VERSION "dbc-export 1 2025.20.8"

NS_ :

BS_:

BU_: ADSP APB APP APS APSB BB BMS CC CMP CMPD CP DAS DI DIF DIR DPB EPAS3P EPAS3S EPASTP EPASTS EPBL EPBR ESP EVSE FC GTW HCML HCMR HVP IBST ICR IDB LS OCS1P ODIN PARK PCS PLG PM PMF PMR PNCD PTC RADC RCM RCM2 RCM3 RCU SCCM SCM SCS SDCR TAS TCU TPMS TRCM UDS UI UIS UMC USM VC VCFRONT VCLEFT VCRIGHT VCSEC VEH

BO_ 1481 APS_alertLog: 8 APS
 SG_ APS_alertID M : 0|14@1+ (1,0) [0|16383] "" Vector__XXX
 SG_ APS_alertSource : 14|1@1+ (1,0) [0|1] "" Vector__XXX
 SG_ APS_alertState : 15|1@1+ (1,0) [0|1] "" Vector__XXX
 SG_ APS_sw010_a04calibNotDone m10 : 16|1@1+ (1,0) [0|1] "" Vector__XXX
 SG_ APS_sw010_a05calibReqd m10 : 17|1@1+ (1,0) [0|1] "" Vector__XXX
 SG_ APS_sw010_a06calibNotOK m10 : 18|1@1+ (1,0) [0|1] "" Vector__XXX
 SG_ APS_sw010_a08PlantMode m10 : 19|1@1+ (1,0) [0|1] "" Vector__XXX
 SG_ APS_sw010_HorizontalMisalignment m10 : 20|16@1+ (0.00137332,-45) [-45|45.0005262] "deg" Vector__XXX
 SG_ APS_sw010_VerticalMisalignment m10 : 36|10@1+ (0.087977,-45) [-45|45.000471] "deg" Vector__XXX
 SG_ APS_sw010_unusedBits m10 : 46|2@1+ (1,0) [0|3] "" Vector__XXX
 SG_ APS_sw010_VmaPlausibility m10 : 48|16@1+ (1.52587890625e-05,0) [0|0.999984741211] "FIXME" Vector__XXX
 SG_ APS_sw019_taskId m19 : 16|8@1+ (1,0) [0|255] "" Vector__XXX
 SG_ APS_sw019_numFreeBytes m19 : 24|8@1+ (1,-191) [-191|64] "# of bytes" Vector__XXX
 SG_ APS_sw019_timeStamp m19 : 32|32@1+ (1,0) [0|4294967295] "ms" Vector__XXX
 SG_ APS_sw020_unusedW0 m20 : 16|16@1+ (1,0) [0|65535] "" Vector__XXX
 SG_ APS_sw020_unusedW1 m20 : 32|16@1+ (1,0) [0|65535] "" Vector__XXX
 SG_ APS_sw020_unusedW2 m20 : 48|16@1+ (1,0) [0|65535] "" Vector__XXX
 SG_ APS_sw021_tempSensorId m21 : 16|8@1+ (1,0) [0|255] "" Vector__XXX
 SG_ APS_sw021_minThreshold m21 : 24|8@1- (1,0) [-128|127] "degC" Vector__XXX
 SG_ APS_sw021_maxThreshold m21 : 32|8@1- (1,0) [-128|127] "degC" Vector__XXX
 SG_ APS_sw021_currentTemperature m21 : 40|8@1- (1,0) [-128|127] "degC" Vector__XXX
 SG_ APS_sw021_unusedWord m21 : 48|16@1+ (1,0) [0|65535] "" Vector__XXX
 SG_ APS_sw024_Task_ID m24 : 16|4@1+ (1,0) [0|15] "" Vector__XXX
 SG_ APS_sw024_numVirtualLaneVeh m24 : 20|4@1+ (1,0) [0|15] "" Vector__XXX
 SG_ APS_sw024_currentVehicleApp m24 : 24|8@1+ (1,0) [0|255] "" Vector__XXX
 SG_ APS_sw024_taskProgramCounter m24 : 32|32@1+ (1,0) [0|4294967295] "" Vector__XXX
 SG_ APS_sw027_JTAG_Reset m27 : 16|1@1+ (1,0) [0|1] "" Vector__XXX
 SG_ APS_sw027_Core_Reset m27 : 17|1@1+ (1,0) [0|1] "" Vector__XXX
 SG_ APS_sw027_Unused_Bit_0 m27 : 18|1@1+ (1,0) [0|1] "" Vector__XXX
 SG_ APS_sw027_CPU_Checkstop_Error m27 : 19|1@1+ (1,0) [0|1] "" Vector__XXX
 SG_ APS_sw027_PLL_0_Failure m27 : 20|1@1+ (1,0) [0|1] "" Vector__XXX
 SG_ APS_sw027_Clock_Monitor_0_Low m27 : 21|1@1+ (1,0) [0|1] "" Vector__XXX
 SG_ APS_sw027_Clock_Monitor_0_Off m27 : 22|1@1+ (1,0) [0|1] "" Vector__XXX
 SG_ APS_sw027_LVD_4v5 m27 : 23|1@1+ (1,0) [0|1] "" Vector__XXX
 SG_ APS_sw027_Flash_Fatal_Error m27 : 24|1@1+ (1,0) [0|1] "" Vector__XXX
 SG_ APS_sw027_PLL_1_Failure m27 : 25|1@1+ (1,0) [0|1] "" Vector__XXX
 SG_ APS_sw027_Unused_Bit_1 m27 : 26|1@1+ (1,0) [0|1] "" Vector__XXX
 SG_ APS_sw027_f_PLL_1_Off m27 : 27|1@1+ (1,0) [0|1] "" Vector__XXX
 SG_ APS_sw027_Unused_Nibble m27 : 28|4@1+ (1,0) [0|15] "" Vector__XXX
 SG_ APS_sw027_LVD_1v2 m27 : 32|1@1+ (1,0) [0|1] "" Vector__XXX
 SG_ APS_sw027_Unused_Bit_2 m27 : 33|1@1+ (1,0) [0|1] "" Vector__XXX
 SG_ APS_sw027_Watchdog m27 : 34|1@1+ (1,0) [0|1] "" Vector__XXX
 SG_ APS_sw027_Unused_Bit_3 m27 : 35|1@1+ (1,0) [0|1] "" Vector__XXX
 SG_ APS_sw027_LVD_2v7_VREG m27 : 36|1@1+ (1,0) [0|1] "" Vector__XXX
 SG_ APS_sw027_LVD_2v7_Flash m27 : 37|1@1+ (1,0) [0|1] "" Vector__XXX
 SG_ APS_sw027_LVD_2v7_IO m27 : 38|1@1+ (1,0) [0|1] "" Vector__XXX
 SG_ APS_sw027_Unused_Bit_4 m27 : 39|1@1+ (1,0) [0|1] "" Vector__XXX
 SG_ APS_sw027_Unused_Byte m27 : 40|8@1+ (1,0) [0|255] "" Vector__XXX
 SG_ APS_sw027_ESR0 m27 : 48|1@1+ (1,0) [0|1] "" Vector__XXX
 SG_ APS_sw027_ESR1 m27 : 49|1@1+ (1,0) [0|1] "" Vector__XXX
 SG_ APS_sw027_SW m27 : 50|1@1+ (1,0) [0|1] "" Vector__XXX
 SG_ APS_sw027_STM0 m27 : 51|1@1+ (1,0) [0|1] "" Vector__XXX
 SG_ APS_sw027_STM1 m27 : 52|1@1+ (1,0) [0|1] "" Vector__XXX
 SG_ APS_sw027_STM2 m27 : 53|1@1+ (1,0) [0|1] "" Vector__XXX
 SG_ APS_sw027_CBS_SYSTEM m27 : 54|1@1+ (1,0) [0|1] "" Vector__XXX
 SG_ APS_sw027_CBS_DEBUG m27 : 55|1@1+ (1,0) [0|1] "" Vector__XXX
 SG_ APS_sw027_CBS_APP m27 : 56|1@1+ (1,0) [0|1] "" Vector__XXX
 SG_ APS_sw027_EVR13 m27 : 57|1@1+ (1,0) [0|1] "" Vector__XXX
 SG_ APS_sw027_EVR33 m27 : 58|1@1+ (1,0) [0|1] "" Vector__XXX
 SG_ APS_sw027_SWD m27 : 59|1@1+ (1,0) [0|1] "" Vector__XXX
 SG_ APS_sw027_STDBY_WDG m27 : 60|1@1+ (1,0) [0|1] "" Vector__XXX
 SG_ APS_sw027_PORST m27 : 61|1@1+ (1,0) [0|1] "" Vector__XXX
 SG_ APS_sw027_Unused_word m27 : 62|2@1+ (1,0) [0|3] "" Vector__XXX
 SG_ APS_sw030_heaterState m30 : 16|8@1+ (1,0) [0|255] "" Vector__XXX
 SG_ APS_sw030_unusedByte m30 : 24|8@1+ (1,0) [0|255] "" Vector__XXX
 SG_ APS_sw030_unusedW0 m30 : 32|16@1+ (1,0) [0|65535] "" Vector__XXX
 SG_ APS_sw030_unusedW1 m30 : 48|16@1+ (1,0) [0|65535] "" Vector__XXX
 SG_ APS_sw031_canBus m31 : 16|4@1+ (1,0) [0|15] "" Vector__XXX
 SG_ APS_sw031_errorType m31 : 24|8@1+ (1,0) [0|255] "" Vector__XXX
 SG_ APS_sw031_errorData1 m31 : 32|16@1+ (1,0) [0|65535] "" Vector__XXX
 SG_ APS_sw031_errorData2 m31 : 48|16@1+ (1,0) [0|65535] "" Vector__XXX
 SG_ APS_sw032_canBus m32 : 16|4@1+ (1,0) [0|15] "" Vector__XXX
 SG_ APS_sw032_errorType m32 : 24|8@1+ (1,0) [0|255] "" Vector__XXX
 SG_ APS_sw032_errorData1 m32 : 32|16@1+ (1,0) [0|65535] "" Vector__XXX
 SG_ APS_sw032_errorData2 m32 : 48|16@1+ (1,0) [0|65535] "" Vector__XXX
 SG_ APS_sw033_carConfig m33 : 16|1@1+ (1,0) [0|1] "" Vector__XXX
 SG_ APS_sw033_chNm m33 : 17|1@1+ (1,0) [0|1] "" Vector__XXX
 SG_ APS_sw033_vin m33 : 18|1@1+ (1,0) [0|1] "" Vector__XXX
 SG_ APS_sw033_carState m33 : 19|1@1+ (1,0) [0|1] "" Vector__XXX
 SG_ APS_sw034_sccmMia m34 : 16|8@1+ (1,0) [0|255] "" Vector__XXX
 SG_ APS_sw034_unusedByte m34 : 24|8@1+ (1,0) [0|255] "" Vector__XXX
 SG_ APS_sw034_unusedW0 m34 : 32|16@1+ (1,0) [0|65535] "" Vector__XXX
 SG_ APS_sw034_unusedW1 m34 : 48|16@1+ (1,0) [0|65535] "" Vector__XXX
 SG_ APS_sw035_wheelSpeeds m35 : 16|1@1+ (1,0) [0|1] "" Vector__XXX
 SG_ APS_sw035_status m35 : 17|1@1+ (1,0) [0|1] "" Vector__XXX
 SG_ APS_sw035_wheelRotation m35 : 18|1@1+ (1,0) [0|1] "" Vector__XXX
 SG_ APS_sw036_bdyMia m36 : 16|8@1+ (1,0) [0|255] "" Vector__XXX
 SG_ APS_sw036_unusedByte m36 : 24|8@1+ (1,0) [0|255] "" Vector__XXX
 SG_ APS_sw036_unusedW0 m36 : 32|16@1+ (1,0) [0|65535] "" Vector__XXX
 SG_ APS_sw036_unusedW1 m36 : 48|16@1+ (1,0) [0|65535] "" Vector__XXX
 SG_ APS_sw039_sdm_rcm_Mia m39 : 16|8@1+ (1,0) [0|255] "" Vector__XXX
 SG_ APS_sw039_unusedByte m39 : 24|8@1+ (1,0) [0|255] "" Vector__XXX
 SG_ APS_sw039_unusedW0 m39 : 32|16@1+ (1,0) [0|65535] "" Vector__XXX
 SG_ APS_sw039_unusedW1 m39 : 48|16@1+ (1,0) [0|65535] "" Vector__XXX
 SG_ APS_sw045_radMia m45 : 16|8@1+ (1,0) [0|255] "" Vector__XXX
 SG_ APS_sw045_unusedByte m45 : 24|8@1+ (1,0) [0|255] "" Vector__XXX
 SG_ APS_sw045_unusedW0 m45 : 32|16@1+ (1,0) [0|65535] "" Vector__XXX
 SG_ APS_sw045_unusedW1 m45 : 48|16@1+ (1,0) [0|65535] "" Vector__XXX
 SG_ APS_sw048_swAssert m48 : 16|1@1+ (1,0) [0|1] "" Vector__XXX
 SG_ APS_sw048_thermalIssue m48 : 17|1@1+ (1,0) [0|1] "" Vector__XXX
 SG_ APS_sw048_powerIssue m48 : 18|1@1+ (1,0) [0|1] "" Vector__XXX
 SG_ APS_sw048_stackOverflow m48 : 19|1@1+ (1,0) [0|1] "" Vector__XXX
 SG_ APS_sw048_checkStop m48 : 20|1@1+ (1,0) [0|1] "" Vector__XXX
 SG_ APS_sw048_ecuWatchdog m48 : 21|1@1+ (1,0) [0|1] "" Vector__XXX
 SG_ APS_sw048_ecuReset m48 : 22|1@1+ (1,0) [0|1] "" Vector__XXX
 SG_ APS_sw048_radcVersionMismatch m48 : 23|1@1+ (1,0) [0|1] "" Vector__XXX
 SG_ APS_sw048_radcCalibration m48 : 24|1@1+ (1,0) [0|1] "" Vector__XXX
 SG_ APS_sw048_radcMia m48 : 25|1@1+ (1,0) [0|1] "" Vector__XXX
 SG_ APS_sw048_eyeQVersionMismatch m48 : 26|1@1+ (1,0) [0|1] "" Vector__XXX
 SG_ APS_sw048_camIssue m48 : 27|1@1+ (1,0) [0|1] "" Vector__XXX
 SG_ APS_sw048_parkerIssue m48 : 28|1@1+ (1,0) [0|1] "" Vector__XXX
 SG_ APS_sw048_prolongedUiMia m48 : 29|1@1+ (1,0) [0|1] "" Vector__XXX
 SG_ APS_sw048_uiMiaAtBootup m48 : 30|1@1+ (1,0) [0|1] "" Vector__XXX
 SG_ APS_sw051_a01ecuInternalPerf m51 : 16|1@1+ (1,0) [0|1] "" Vector__XXX
 SG_ APS_sw051_a02flashPerformance m51 : 17|1@1+ (1,0) [0|1] "" Vector__XXX
 SG_ APS_sw051_a03vBatHigh m51 : 18|1@1+ (1,0) [0|1] "" Vector__XXX
 SG_ APS_sw051_a09configMismatch m51 : 19|1@1+ (1,0) [0|1] "" Vector__XXX
 SG_ APS_sw051_a52radomeHtrInop m51 : 20|1@1+ (1,0) [0|1] "" Vector__XXX
 SG_ APS_sw051_unused m51 : 21|3@1+ (1,0) [0|7] "" Vector__XXX
 SG_ APS_sw051_SCUTemperature m51 : 24|8@1- (1,0) [-128|127] "" Vector__XXX
 SG_ APS_sw051_HWFail m51 : 32|1@1+ (1,0) [0|1] "" Vector__XXX
 SG_ APS_sw051_SGUFail m51 : 33|1@1+ (1,0) [0|1] "" Vector__XXX
 SG_ APS_sw051_unusedBits m51 : 34|6@1+ (1,0) [0|63] "" Vector__XXX
 SG_ APS_sw051_unusedB0 m51 : 40|8@1+ (1,0) [0|255] "" Vector__XXX
 SG_ APS_sw051_unusedW1 m51 : 48|16@1+ (1,0) [0|65535] "" Vector__XXX
 SG_ APS_sw052_a07sensorBlinded m52 : 16|1@1+ (1,0) [0|1] "" Vector__XXX
 SG_ APS_sw052_sensorDirty m52 : 17|1@1+ (1,0) [0|1] "" Vector__XXX
 SG_ APS_sw052_HWFail m52 : 18|1@1+ (1,0) [0|1] "" Vector__XXX
 SG_ APS_sw052_overTemperature m52 : 19|1@1+ (1,0) [0|1] "" Vector__XXX
 SG_ APS_sw052_underTemperature m52 : 20|1@1+ (1,0) [0|1] "" Vector__XXX
 SG_ APS_sw052_chirpError m52 : 21|1@1+ (1,0) [0|1] "" Vector__XXX
 SG_ APS_sw052_rspError m52 : 22|1@1+ (1,0) [0|1] "" Vector__XXX
 SG_ APS_sw052_sensorBlocked m52 : 23|1@1+ (1,0) [0|1] "" Vector__XXX
 SG_ APS_sw053_a10canBusOff m53 : 16|1@1+ (1,0) [0|1] "" Vector__XXX
 SG_ APS_sw053_a11bdyMIA m53 : 17|1@1+ (1,0) [0|1] "" Vector__XXX
 SG_ APS_sw053_a12espMIA m53 : 18|1@1+ (1,0) [0|1] "" Vector__XXX
 SG_ APS_sw053_a13gtwMIA m53 : 19|1@1+ (1,0) [0|1] "" Vector__XXX
 SG_ APS_sw053_a14sccmMIA m53 : 20|1@1+ (1,0) [0|1] "" Vector__XXX
 SG_ APS_sw053_a15adasMIA m53 : 21|1@1+ (1,0) [0|1] "" Vector__XXX
 SG_ APS_sw053_a16bdyInvalidCount m53 : 22|1@1+ (1,0) [0|1] "" Vector__XXX
 SG_ APS_sw053_a17adasInvalidCount m53 : 23|1@1+ (1,0) [0|1] "" Vector__XXX
 SG_ APS_sw053_a18espInvalidCount m53 : 24|1@1+ (1,0) [0|1] "" Vector__XXX
 SG_ APS_sw053_a19sccmInvalidCount m53 : 25|1@1+ (1,0) [0|1] "" Vector__XXX
 SG_ APS_sw053_a20bdyInvalidChkSm m53 : 26|1@1+ (1,0) [0|1] "" Vector__XXX
 SG_ APS_sw053_a21espInvalidChkSm m53 : 27|1@1+ (1,0) [0|1] "" Vector__XXX
 SG_ APS_sw053_a22sccmInvalidChkSm m53 : 28|1@1+ (1,0) [0|1] "" Vector__XXX
 SG_ APS_sw053_a23sccmInvalidChkSm m53 : 29|1@1+ (1,0) [0|1] "" Vector__XXX
 SG_ APS_sw053_a24absValidity m53 : 30|1@1+ (1,0) [0|1] "" Vector__XXX
 SG_ APS_sw053_a25ambTValidity m53 : 31|1@1+ (1,0) [0|1] "" Vector__XXX
 SG_ APS_sw053_a26brakeValidity m53 : 32|1@1+ (1,0) [0|1] "" Vector__XXX
 SG_ APS_sw053_a27CntryCdValidity m53 : 33|1@1+ (1,0) [0|1] "" Vector__XXX
 SG_ APS_sw053_a28espValidity m53 : 34|1@1+ (1,0) [0|1] "" Vector__XXX
 SG_ APS_sw053_a29longAccOffValidity m53 : 35|1@1+ (1,0) [0|1] "" Vector__XXX
 SG_ APS_sw053_a30longAccValidity m53 : 36|1@1+ (1,0) [0|1] "" Vector__XXX
 SG_ APS_sw053_a31odoValidity m53 : 37|1@1+ (1,0) [0|1] "" Vector__XXX
 SG_ APS_sw053_a32gearValidity m53 : 38|1@1+ (1,0) [0|1] "" Vector__XXX
 SG_ APS_sw053_a33steerAngValidity m53 : 39|1@1+ (1,0) [0|1] "" Vector__XXX
 SG_ APS_sw053_a34steerAngSpdValidity m53 : 40|1@1+ (1,0) [0|1] "" Vector__XXX
 SG_ APS_sw053_a35indctrValidity m53 : 41|1@1+ (1,0) [0|1] "" Vector__XXX
 SG_ APS_sw053_a36vehStndStllValidty m53 : 42|1@1+ (1,0) [0|1] "" Vector__XXX
 SG_ APS_sw053_a37vinValidity m53 : 43|1@1+ (1,0) [0|1] "" Vector__XXX
 SG_ APS_sw053_a38whlRotValidity m53 : 44|1@1+ (1,0) [0|1] "" Vector__XXX
 SG_ APS_sw053_a39whlSpdValidity m53 : 45|1@1+ (1,0) [0|1] "" Vector__XXX
 SG_ APS_sw053_a40whlStndStllValidty m53 : 46|1@1+ (1,0) [0|1] "" Vector__XXX
 SG_ APS_sw053_a41wiperValidity m53 : 47|1@1+ (1,0) [0|1] "" Vector__XXX
 SG_ APS_sw053_a42xwdValidity m53 : 48|1@1+ (1,0) [0|1] "" Vector__XXX
 SG_ APS_sw053_a43yawOffValidity m53 : 49|1@1+ (1,0) [0|1] "" Vector__XXX
 SG_ APS_sw053_a44yawValidity m53 : 50|1@1+ (1,0) [0|1] "" Vector__XXX
 SG_ APS_sw053_a48steerAngOffSanity m53 : 51|1@1+ (1,0) [0|1] "" Vector__XXX
 SG_ APS_sw053_a49tireSizeSanity m53 : 52|1@1+ (1,0) [0|1] "" Vector__XXX
 SG_ APS_sw053_a50velocitySanity m53 : 53|1@1+ (1,0) [0|1] "" Vector__XXX
 SG_ APS_sw053_a51yawSanity m53 : 54|1@1+ (1,0) [0|1] "" Vector__XXX
 SG_ APS_sw053_a53espmodValidity m53 : 55|1@1+ (1,0) [0|1] "" Vector__XXX
 SG_ APS_sw053_a54gtwmodValidity m53 : 56|1@1+ (1,0) [0|1] "" Vector__XXX
 SG_ APS_sw053_a55stwmodValidity m53 : 57|1@1+ (1,0) [0|1] "" Vector__XXX
 SG_ APS_sw053_a56bcmodValidity m53 : 58|1@1+ (1,0) [0|1] "" Vector__XXX
 SG_ APS_sw053_a57dimodValidity m53 : 59|1@1+ (1,0) [0|1] "" Vector__XXX
 SG_ APS_sw053_a59drmiInvalidChkSm m53 : 60|1@1+ (1,0) [0|1] "" Vector__XXX
 SG_ APS_sw053_a60drmiInvalidCount m53 : 61|1@1+ (1,0) [0|1] "" Vector__XXX
 SG_ APS_sw053_a61radPositionMismatch m53 : 62|1@1+ (1,0) [0|1] "" Vector__XXX
 SG_ APS_sw053_a62strRackMismatch m53 : 63|1@1+ (1,0) [0|1] "" Vector__XXX
 SG_ APS_sw055_detectedRadcVersion m55 : 16|32@1+ (1,0) [0|4294967295] "" Vector__XXX
 SG_ APS_sw055_expectedCrcLsw m55 : 48|16@1+ (1,0) [0|65535] "" Vector__XXX
 SG_ APS_sw056_diMia m56 : 16|8@1+ (1,0) [0|255] "" Vector__XXX
 SG_ APS_sw056_unusedByte m56 : 24|8@1+ (1,0) [0|255] "" Vector__XXX
 SG_ APS_sw056_unusedW0 m56 : 32|16@1+ (1,0) [0|65535] "" Vector__XXX
 SG_ APS_sw056_unusedW1 m56 : 48|16@1+ (1,0) [0|65535] "" Vector__XXX
 SG_ APS_sw058_epbMia m58 : 16|8@1+ (1,0) [0|255] "" Vector__XXX
 SG_ APS_sw058_unusedByte m58 : 24|8@1+ (1,0) [0|255] "" Vector__XXX
 SG_ APS_sw058_unusedW0 m58 : 32|16@1+ (1,0) [0|65535] "" Vector__XXX
 SG_ APS_sw058_unusedW1 m58 : 48|16@1+ (1,0) [0|65535] "" Vector__XXX
 SG_ APS_sw059_sdiFront m59 : 16|1@1+ (1,0) [0|1] "" Vector__XXX
 SG_ APS_sw059_sdiRear m59 : 17|1@1+ (1,0) [0|1] "" Vector__XXX
 SG_ APS_sw059_status m59 : 18|1@1+ (1,0) [0|1] "" Vector__XXX
 SG_ APS_sw059_sensorStatusFront m59 : 19|1@1+ (1,0) [0|1] "" Vector__XXX
 SG_ APS_sw059_pasFrontMiddle m59 : 20|1@1+ (1,0) [0|1] "" Vector__XXX
 SG_ APS_sw059_sensorStatusRear m59 : 21|1@1+ (1,0) [0|1] "" Vector__XXX
 SG_ APS_sw059_pasRearMiddle m59 : 22|1@1+ (1,0) [0|1] "" Vector__XXX
 SG_ APS_sw059_pscStatus m59 : 23|1@1+ (1,0) [0|1] "" Vector__XXX
 SG_ APS_sw059_pscVehSlot m59 : 24|1@1+ (1,0) [0|1] "" Vector__XXX
 SG_ APS_sw059_status2 m59 : 25|1@1+ (1,0) [0|1] "" Vector__XXX
 SG_ APS_sw059_oloDict m59 : 26|1@1+ (1,0) [0|1] "" Vector__XXX
 SG_ APS_sw059_oocStatus m59 : 27|1@1+ (1,0) [0|1] "" Vector__XXX
 SG_ APS_sw061_states m61 : 16|1@1+ (1,0) [0|1] "" Vector__XXX
 SG_ APS_sw063_expectedMajorVer m63 : 16|8@1+ (1,0) [0|255] "" Vector__XXX
 SG_ APS_sw063_detectedMajorVer m63 : 24|8@1+ (1,0) [0|255] "" Vector__XXX
 SG_ APS_sw063_expectedMinorVer m63 : 32|8@1+ (1,0) [0|255] "" Vector__XXX
 SG_ APS_sw063_detectedMinorVer m63 : 40|8@1+ (1,0) [0|255] "" Vector__XXX
 SG_ APS_sw063_expectedSubMinorVer m63 : 48|8@1+ (1,0) [0|255] "" Vector__XXX
 SG_ APS_sw063_detectedSubMinorVer m63 : 56|8@1+ (1,0) [0|255] "" Vector__XXX
 SG_ APS_sw064_sysStatus m64 : 16|1@1+ (1,0) [0|1] "" Vector__XXX
 SG_ APS_sw064_status m64 : 17|1@1+ (1,0) [0|1] "" Vector__XXX
 SG_ APS_sw070_currTireFitment m70 : 16|3@1+ (1,0) [0|7] "" Vector__XXX
 SG_ APS_sw070_lastTireFitment m70 : 19|3@1+ (1,0) [0|7] "" Vector__XXX
 SG_ APS_sw070_diGear m70 : 24|3@1+ (1,0) [0|7] "" Vector__XXX
 SG_ APS_sw070_driveRail m70 : 27|1@1+ (1,0) [0|1] "" Vector__XXX
 SG_ APS_sw070_accRail m70 : 28|1@1+ (1,0) [0|1] "" Vector__XXX
 SG_ APS_sw070_temperature m70 : 32|8@1+ (0.5,-40) [-40|87.5] "C" Vector__XXX
 SG_ APS_sw070_currentSpeed m70 : 40|12@1+ (0.1,-204.7) [-204.7|204.8] "mph" Vector__XXX
 SG_ APS_sw071_selfParkType m71 : 16|4@1+ (1,0) [0|15] "" Vector__XXX
 SG_ APS_sw071_endPosX m71 : 20|10@1+ (0.05,-25.6) [-25.6|25.55] "m" Vector__XXX
 SG_ APS_sw071_endPosY m71 : 30|10@1+ (0.05,-25.6) [-25.6|25.55] "m" Vector__XXX
 SG_ APS_sw071_roadClass m71 : 40|3@1+ (1,0) [0|7] "" Vector__XXX
 SG_ APS_sw071_driverPresent m71 : 43|1@1+ (1,0) [0|1] "" Vector__XXX
 SG_ APS_sw071_airSuspension m71 : 44|3@1+ (1,0) [0|7] "" Vector__XXX
 SG_ APS_sw071_temperature m71 : 48|8@1+ (0.5,-40) [-40|87.5] "C" Vector__XXX
 SG_ APS_sw071_activationType m71 : 56|2@1+ (1,0) [0|3] "" Vector__XXX
 SG_ APS_sw072_vehicleX m72 : 16|10@1+ (0.05,-25.6) [-25.6|25.55] "m" Vector__XXX
 SG_ APS_sw072_vehicleY m72 : 26|10@1+ (0.05,-25.6) [-25.6|25.55] "m" Vector__XXX
 SG_ APS_sw072_vehicleHeading m72 : 36|10@1+ (0.005,-2.56) [-2.56|2.555] "rad" Vector__XXX
 SG_ APS_sw072_endDistance m72 : 48|8@1+ (1,0) [0|255] "cm" Vector__XXX
 SG_ APS_sw072_guidanceComplete m72 : 56|1@1+ (1,0) [0|1] "" Vector__XXX
 SG_ APS_sw072_guidanceRunaway m72 : 57|1@1+ (1,0) [0|1] "" Vector__XXX
 SG_ APS_sw072_guidanceTimer m72 : 58|1@1+ (1,0) [0|1] "" Vector__XXX
 SG_ APS_sw072_handlePress m72 : 59|1@1+ (1,0) [0|1] "" Vector__XXX
 SG_ APS_sw072_keyfobPress m72 : 60|1@1+ (1,0) [0|1] "" Vector__XXX
 SG_ APS_sw072_garageOpened m72 : 61|1@1+ (1,0) [0|1] "" Vector__XXX
 SG_ APS_sw072_userTimeout m72 : 62|1@1+ (1,0) [0|1] "" Vector__XXX
 SG_ APS_sw075_scMia m75 : 16|8@1+ (1,0) [0|255] "" Vector__XXX
 SG_ APS_sw075_unusedByte m75 : 24|8@1+ (1,0) [0|255] "" Vector__XXX
 SG_ APS_sw075_unusedW0 m75 : 32|16@1+ (1,0) [0|65535] "" Vector__XXX
 SG_ APS_sw075_unusedW1 m75 : 48|16@1+ (1,0) [0|65535] "" Vector__XXX
 SG_ APS_sw077_oocDistance m77 : 16|9@1+ (1,0) [0|511] "cm" Vector__XXX
 SG_ APS_sw077_oocConfidence m77 : 25|7@1+ (1,0) [0|127] "%" Vector__XXX
 SG_ APS_sw077_oocCollisionSide m77 : 32|3@1+ (1,0) [0|7] "" Vector__XXX
 SG_ APS_sw077_oocHeight m77 : 35|2@1+ (1,0) [0|3] "" Vector__XXX
 SG_ APS_sw077_vehicleSpeed m77 : 37|10@1+ (0.05,-25) [-25|26.15] "MPH" Vector__XXX
 SG_ APS_sw077_oocUntrackedTime m77 : 48|6@1+ (0.1,0) [0|6.3] "s" Vector__XXX
 SG_ APS_sw077_oocOffCourseDist_cm m77 : 54|10@1- (1,0) [-512|511] "" Vector__XXX
 SG_ APS_sw081_radarDistance m81 : 16|8@1+ (0.0625,0) [0|15.9375] "m" Vector__XXX
 SG_ APS_sw081_radarTTC m81 : 24|8@1+ (0.02,0) [0|5.1] "seconds" Vector__XXX
 SG_ APS_sw081_cameraDistance m81 : 32|8@1+ (0.0625,0) [0|15.9375] "m" Vector__XXX
 SG_ APS_sw081_cameraTTC m81 : 40|8@1+ (0.02,0) [0|5.1] "seconds" Vector__XXX
 SG_ APS_sw081_pedalPosition m81 : 48|7@1+ (1,0) [0|127] "%" Vector__XXX
 SG_ APS_sw129_currentVoltage m129 : 16|14@1+ (1,0) [0|16383] "mV" Vector__XXX
 SG_ APS_sw129_maxThreshold m129 : 30|13@1+ (1,50) [50|8241] "mV" Vector__XXX
 SG_ APS_sw129_minThreshold m129 : 43|13@1+ (1,0) [0|8191] "mV" Vector__XXX
 SG_ APS_sw129_powerSequnceError m129 : 56|1@1+ (1,0) [0|1] "" Vector__XXX
 SG_ APS_sw129_railControl m129 : 57|1@1+ (1,0) [0|1] "" Vector__XXX
 SG_ APS_sw129_railID m129 : 58|6@1+ (1,0) [0|63] "" Vector__XXX
 SG_ APS_sw130_currentTemperature m130 : 16|8@1- (1,0) [-128|127] "degC" Vector__XXX
 SG_ APS_sw130_maxThreshold m130 : 24|8@1- (1,0) [-128|127] "degC" Vector__XXX
 SG_ APS_sw130_minThreshold m130 : 32|8@1- (1,0) [-128|127] "degC" Vector__XXX
 SG_ APS_sw130_tempSensorId m130 : 40|6@1+ (1,0) [0|63] "" Vector__XXX
 SG_ APS_sw130_shouldForceApPowerOn m130 : 46|1@1+ (1,0) [0|1] "" Vector__XXX
 SG_ APS_sw130_shouldBlockOkToPowerAp m130 : 47|1@1+ (1,0) [0|1] "" Vector__XXX
 SG_ APS_sw132_mismatchType m132 : 16|1@1+ (1,0) [0|1] "" Vector__XXX
 SG_ APS_sw132_actualHash m132 : 24|24@1+ (1,0) [0|16777215] "" Vector__XXX
 SG_ APS_sw132_expectedHash m132 : 48|16@1+ (1,0) [0|65535] "" Vector__XXX
 SG_ APS_sw133_failedInitStep m133 : 16|8@1+ (1,0) [0|255] "" Vector__XXX
 SG_ APS_sw133_switchInReset m133 : 24|1@1+ (1,0) [0|1] "" Vector__XXX
 SG_ APS_sw133_phyIsNotRMIIMode m133 : 25|1@1+ (1,0) [0|1] "" Vector__XXX
 SG_ APS_sw133_phyInterruptStorm m133 : 26|1@1+ (1,0) [0|1] "" Vector__XXX
 SG_ APS_sw133_switchEthernetInterLin m133 : 27|1@1+ (1,0) [0|1] "" Vector__XXX
 SG_ APS_sw133_ethSwitchReadFwVerFail m133 : 28|1@1+ (1,0) [0|1] "" Vector__XXX
 SG_ APS_sw133_ethSwitchFailedToBoot m133 : 29|1@1+ (1,0) [0|1] "" Vector__XXX
 SG_ APS_sw133_ethSwitchTimedoutUpdat m133 : 30|1@1+ (1,0) [0|1] "" Vector__XXX
 SG_ APS_sw133_unused m133 : 31|33@1+ (1,0) [0|8589934591] "" Vector__XXX
 SG_ APS_sw134_appCamCalibStatus m134 : 16|1@1+ (1,0) [0|1] "" Vector__XXX
 SG_ APS_sw134_appCameraLux m134 : 17|1@1+ (1,0) [0|1] "" Vector__XXX
 SG_ APS_sw134_appInfo m134 : 18|1@1+ (1,0) [0|1] "" Vector__XXX
 SG_ APS_sw134_appStatus m134 : 19|1@1+ (1,0) [0|1] "" Vector__XXX
 SG_ APS_sw134_dasBodyControlsVEH m134 : 20|1@1+ (1,0) [0|1] "" Vector__XXX
 SG_ APS_sw134_dasControl m134 : 21|1@1+ (1,0) [0|1] "" Vector__XXX
 SG_ APS_sw134_dasControlPty m134 : 22|1@1+ (1,0) [0|1] "" Vector__XXX
 SG_ APS_sw134_dasIntSafetyFrontPty m134 : 23|1@1+ (1,0) [0|1] "" Vector__XXX
 SG_ APS_sw134_dasLanes m134 : 24|1@1+ (1,0) [0|1] "" Vector__XXX
 SG_ APS_sw134_dasObject m134 : 25|1@1+ (1,0) [0|1] "" Vector__XXX
 SG_ APS_sw134_dasPscControl m134 : 26|1@1+ (1,0) [0|1] "" Vector__XXX
 SG_ APS_sw134_dasStatus m134 : 27|1@1+ (1,0) [0|1] "" Vector__XXX
 SG_ APS_sw134_dasStatus2 m134 : 28|1@1+ (1,0) [0|1] "" Vector__XXX
 SG_ APS_sw134_dasSteeringControl m134 : 29|1@1+ (1,0) [0|1] "" Vector__XXX
 SG_ APS_sw134_dasVisualDebug m134 : 30|1@1+ (1,0) [0|1] "" Vector__XXX
 SG_ APS_sw134_dasSteeringControlPty m134 : 31|1@1+ (1,0) [0|1] "" Vector__XXX
 SG_ APS_sw134_dasChNm m134 : 32|1@1+ (1,0) [0|1] "" Vector__XXX
 SG_ APS_sw134_appSummon m134 : 33|1@1+ (1,0) [0|1] "" Vector__XXX
 SG_ APS_sw134_appEnvironment m134 : 34|1@1+ (1,0) [0|1] "" Vector__XXX
 SG_ APS_sw134_dasStatusPty m134 : 35|1@1+ (1,0) [0|1] "" Vector__XXX
 SG_ APS_sw134_dasStatus2Pty m134 : 36|1@1+ (1,0) [0|1] "" Vector__XXX
 SG_ APS_sw134_dasMatrixHighBeamRqVEH m134 : 37|1@1+ (1,0) [0|1] "" Vector__XXX
 SG_ APS_sw134_dasMatrixBendAngleRqPt m134 : 38|1@1+ (1,0) [0|1] "" Vector__XXX
 SG_ APS_sw134_dasBodyControls2VEH m134 : 39|1@1+ (1,0) [0|1] "" Vector__XXX
 SG_ APS_sw134_timeSinceLastMsg m134 : 40|16@1+ (1,0) [0|65535] "" Vector__XXX
 SG_ APS_sw135_appCriticalReason m135 : 16|4@1+ (1,0) [0|15] "" Vector__XXX
 SG_ APS_sw135_appTimesyncStatus m135 : 24|32@1+ (1,0) [0|4294967295] "" Vector__XXX
 SG_ APS_sw136_gpsCommIrrecoverable m136 : 16|1@1+ (1,0) [0|1] "" Vector__XXX
 SG_ APS_sw136_fusionIrrecoverable m136 : 17|1@1+ (1,0) [0|1] "" Vector__XXX
 SG_ APS_sw136_antennaUnplugged m136 : 18|1@1+ (1,0) [0|1] "" Vector__XXX
 SG_ APS_sw136_badgpsfix m136 : 19|1@1+ (1,0) [0|1] "" Vector__XXX
 SG_ APS_sw137_gpsCommMissing m137 : 16|1@1+ (1,0) [0|1] "" Vector__XXX
 SG_ APS_sw137_gpsJunkData m137 : 17|1@1+ (1,0) [0|1] "" Vector__XXX
 SG_ APS_sw137_gpsNMEAmissing m137 : 18|1@1+ (1,0) [0|1] "" Vector__XXX
 SG_ APS_sw137_gpsUBXmissing m137 : 19|1@1+ (1,0) [0|1] "" Vector__XXX
 SG_ APS_sw137_fusionModeDisabled m137 : 20|1@1+ (1,0) [0|1] "" Vector__XXX
 SG_ APS_sw137_gpsCfgFail m137 : 21|1@1+ (1,0) [0|1] "" Vector__XXX
 SG_ APS_sw137_esfStatusMsgMIA m137 : 22|1@1+ (1,0) [0|1] "" Vector__XXX
 SG_ APS_sw137_wheelTickCfgMissmatch m137 : 23|1@1+ (1,0) [0|1] "" Vector__XXX
 SG_ APS_sw137_exitTransportMode m137 : 24|1@1+ (1,0) [0|1] "" Vector__XXX
 SG_ APS_sw137_satRejectionTimeout m137 : 25|1@1+ (1,0) [0|1] "" Vector__XXX
 SG_ APS_sw137_gpsPPSMissing m137 : 26|1@1+ (1,0) [0|1] "" Vector__XXX
 SG_ APS_sw138_cfgBufNull m138 : 16|1@1+ (1,0) [0|1] "" Vector__XXX
 SG_ APS_sw138_invalidID m138 : 17|1@1+ (1,0) [0|1] "" Vector__XXX
 SG_ APS_sw138_gpsBufferOverflow m138 : 18|1@1+ (1,0) [0|1] "" Vector__XXX
 SG_ APS_sw138_navx5CfgFailed m138 : 19|1@1+ (1,0) [0|1] "" Vector__XXX
 SG_ APS_sw138_mcuNMEAmsgUDPinvalid m138 : 20|1@1+ (1,0) [0|1] "" Vector__XXX
 SG_ APS_sw138_mcuDbgMsgInvalid m138 : 21|1@1+ (1,0) [0|1] "" Vector__XXX
 SG_ APS_sw138_mcuDbgMsgTooBig m138 : 22|1@1+ (1,0) [0|1] "" Vector__XXX
 SG_ APS_sw138_mcuFwdNMEAfail m138 : 23|1@1+ (1,0) [0|1] "" Vector__XXX
 SG_ APS_sw138_NMEAinvalidChecksum m138 : 24|1@1+ (1,0) [0|1] "" Vector__XXX
 SG_ APS_sw138_unexpectedNMEAmsg m138 : 25|1@1+ (1,0) [0|1] "" Vector__XXX
 SG_ APS_sw138_UARTbusFull m138 : 26|1@1+ (1,0) [0|1] "" Vector__XXX
 SG_ APS_sw138_UARTframeError m138 : 27|1@1+ (1,0) [0|1] "" Vector__XXX
 SG_ APS_sw138_UBXrxFrameTooBig m138 : 28|1@1+ (1,0) [0|1] "" Vector__XXX
 SG_ APS_sw138_emptyValidNMEA m138 : 29|1@1+ (1,0) [0|1] "" Vector__XXX
 SG_ APS_sw138_invalidAsciiNMEA m138 : 30|1@1+ (1,0) [0|1] "" Vector__XXX
 SG_ APS_sw138_wheeltickUARTfault m138 : 31|1@1+ (1,0) [0|1] "" Vector__XXX
 SG_ APS_sw138_baudrateMismatch m138 : 32|1@1+ (1,0) [0|1] "" Vector__XXX
 SG_ APS_sw138_wheelTickInvalidSrc m138 : 33|1@1+ (1,0) [0|1] "" Vector__XXX
 SG_ APS_sw138_UARTparityError m138 : 34|1@1+ (1,0) [0|1] "" Vector__XXX
 SG_ APS_sw138_UARTrxFifoOverflow m138 : 35|1@1+ (1,0) [0|1] "" Vector__XXX
 SG_ APS_sw138_UARTrxFifoUnderflow m138 : 36|1@1+ (1,0) [0|1] "" Vector__XXX
 SG_ APS_sw138_UARTtxFifoOverflow m138 : 37|1@1+ (1,0) [0|1] "" Vector__XXX
 SG_ APS_sw138_esfWtMsgTimeout m138 : 38|1@1+ (1,0) [0|1] "" Vector__XXX
 SG_ APS_sw138_PFLASHReadError m138 : 39|1@1+ (1,0) [0|1] "" Vector__XXX
 SG_ APS_sw138_PFLASHWriteError m138 : 40|1@1+ (1,0) [0|1] "" Vector__XXX
 SG_ APS_sw138_gpsCfgNack m138 : 41|1@1+ (1,0) [0|1] "" Vector__XXX
 SG_ APS_sw138_gpsCfgIdFail m138 : 42|6@1+ (1,0) [0|63] "" Vector__XXX
 SG_ APS_sw138_gpsSetCfgNoAck m138 : 48|1@1+ (1,0) [0|1] "" Vector__XXX
 SG_ APS_sw138_gpsReadCfgNoResponse m138 : 49|1@1+ (1,0) [0|1] "" Vector__XXX
 SG_ APS_sw138_ubxErrorReported m138 : 50|1@1+ (1,0) [0|1] "" Vector__XXX
 SG_ APS_sw140_lvPowerState m140 : 16|1@1+ (1,0) [0|1] "" Vector__XXX
 SG_ APS_sw140_vehicleStatus m140 : 17|1@1+ (1,0) [0|1] "" Vector__XXX
 SG_ APS_sw140_status m140 : 18|1@1+ (1,0) [0|1] "" Vector__XXX
 SG_ APS_sw140_lighting m140 : 19|1@1+ (1,0) [0|1] "" Vector__XXX
 SG_ APS_sw140_sensors m140 : 20|1@1+ (1,0) [0|1] "" Vector__XXX
 SG_ APS_sw140_coolant m140 : 21|1@1+ (1,0) [0|1] "" Vector__XXX
 SG_ APS_sw140_okToUseHighPower m140 : 22|1@1+ (1,0) [0|1] "" Vector__XXX
 SG_ APS_sw141_inertial1 m141 : 16|1@1+ (1,0) [0|1] "" Vector__XXX
 SG_ APS_sw141_inertial2 m141 : 17|1@1+ (1,0) [0|1] "" Vector__XXX
 SG_ APS_sw142_speed m142 : 16|1@1+ (1,0) [0|1] "" Vector__XXX
 SG_ APS_sw142_locStatus m142 : 17|1@1+ (1,0) [0|1] "" Vector__XXX
 SG_ APS_sw142_locStatus2 m142 : 18|1@1+ (1,0) [0|1] "" Vector__XXX
 SG_ APS_sw142_systemStatus m142 : 19|1@1+ (1,0) [0|1] "" Vector__XXX
 SG_ APS_sw142_chassisControl m142 : 20|1@1+ (1,0) [0|1] "" Vector__XXX
 SG_ APS_sw143_status m143 : 16|1@1+ (1,0) [0|1] "" Vector__XXX
 SG_ APS_sw143_wheelRotation m143 : 17|1@1+ (1,0) [0|1] "" Vector__XXX
 SG_ APS_sw143_wheelSpeeds m143 : 18|1@1+ (1,0) [0|1] "" Vector__XXX
 SG_ APS_sw144_restraintStatus m144 : 16|1@1+ (1,0) [0|1] "" Vector__XXX
 SG_ APS_sw145_restraintStatus m145 : 16|1@1+ (1,0) [0|1] "" Vector__XXX
 SG_ APS_sw146_sysStatus m146 : 16|1@1+ (1,0) [0|1] "" Vector__XXX
 SG_ APS_sw146_status m146 : 17|1@1+ (1,0) [0|1] "" Vector__XXX
 SG_ APS_sw147_doorStatus m147 : 16|1@1+ (1,0) [0|1] "" Vector__XXX
 SG_ APS_sw147_switchStatus m147 : 17|1@1+ (1,0) [0|1] "" Vector__XXX
 SG_ APS_sw148_doorStatus m148 : 16|1@1+ (1,0) [0|1] "" Vector__XXX
 SG_ APS_sw148_hvacStatus m148 : 17|1@1+ (1,0) [0|1] "" Vector__XXX
 SG_ APS_sw149_status m149 : 16|1@1+ (1,0) [0|1] "" Vector__XXX
 SG_ APS_sw150_steeringAngleSensor m150 : 16|1@1+ (1,0) [0|1] "" Vector__XXX
 SG_ APS_sw150_rightStalk m150 : 17|1@1+ (1,0) [0|1] "" Vector__XXX
 SG_ APS_sw150_leftStalk m150 : 18|1@1+ (1,0) [0|1] "" Vector__XXX
 SG_ APS_sw151_apGpioState m151 : 16|2@1+ (1,0) [0|3] "" Vector__XXX
 SG_ APS_sw151_apWatchDogState m151 : 18|3@1+ (1,0) [0|6] "" Vector__XXX
 SG_ APS_sw151_diGear m151 : 21|3@1+ (1,0) [0|6] "" Vector__XXX
 SG_ APS_sw151_recoveryPathway m151 : 24|2@1+ (1,0) [0|3] "" Vector__XXX
 SG_ APS_sw151_parkerType m151 : 26|1@1+ (1,0) [0|1] "" Vector__XXX
 SG_ APS_sw153_eacInhibitReason m153 : 16|4@1+ (1,0) [0|15] "" Vector__XXX
 SG_ APS_sw153_eacInternalState m153 : 20|3@1+ (1,0) [0|7] "" Vector__XXX
 SG_ APS_sw155_InUnicastError m155 : 16|1@1+ (1,0) [0|1] "" Vector__XXX
 SG_ APS_sw155_UDPRecvError m155 : 17|1@1+ (1,0) [0|1] "" Vector__XXX
 SG_ APS_sw155_UDPMiscError m155 : 18|1@1+ (1,0) [0|1] "" Vector__XXX
 SG_ APS_sw155_UDPRTEError m155 : 19|1@1+ (1,0) [0|1] "" Vector__XXX
 SG_ APS_sw155_UDPCheckError m155 : 20|1@1+ (1,0) [0|1] "" Vector__XXX
 SG_ APS_sw155_UDPDropError m155 : 21|1@1+ (1,0) [0|1] "" Vector__XXX
 SG_ APS_sw155_UDPMemError m155 : 22|1@1+ (1,0) [0|1] "" Vector__XXX
 SG_ APS_sw155_UDPProtoError m155 : 23|1@1+ (1,0) [0|1] "" Vector__XXX
 SG_ APS_sw155_IPRecvError m155 : 24|1@1+ (1,0) [0|1] "" Vector__XXX
 SG_ APS_sw155_IPMiscError m155 : 25|1@1+ (1,0) [0|1] "" Vector__XXX
 SG_ APS_sw155_IPRTEError m155 : 26|1@1+ (1,0) [0|1] "" Vector__XXX
 SG_ APS_sw155_IPCheckError m155 : 27|1@1+ (1,0) [0|1] "" Vector__XXX
 SG_ APS_sw155_IPMemError m155 : 28|1@1+ (1,0) [0|1] "" Vector__XXX
 SG_ APS_sw155_IPDropError m155 : 29|1@1+ (1,0) [0|1] "" Vector__XXX
 SG_ APS_sw155_IPProtoError m155 : 30|1@1+ (1,0) [0|1] "" Vector__XXX
 SG_ APS_sw158_apbInfo m158 : 16|1@1+ (1,0) [0|1] "" Vector__XXX
 SG_ APS_sw158_apbStatus m158 : 17|1@1+ (1,0) [0|1] "" Vector__XXX
 SG_ APS_sw158_dasBodyControlsVEH m158 : 18|1@1+ (1,0) [0|1] "" Vector__XXX
 SG_ APS_sw158_dasControl m158 : 19|1@1+ (1,0) [0|1] "" Vector__XXX
 SG_ APS_sw158_dasControlPty m158 : 20|1@1+ (1,0) [0|1] "" Vector__XXX
 SG_ APS_sw158_dasIntSafetyFrontPty m158 : 21|1@1+ (1,0) [0|1] "" Vector__XXX
 SG_ APS_sw158_dasLanes m158 : 22|1@1+ (1,0) [0|1] "" Vector__XXX
 SG_ APS_sw158_dasObject m158 : 23|1@1+ (1,0) [0|1] "" Vector__XXX
 SG_ APS_sw158_dasPscControl m158 : 24|1@1+ (1,0) [0|1] "" Vector__XXX
 SG_ APS_sw158_dasStatus m158 : 25|1@1+ (1,0) [0|1] "" Vector__XXX
 SG_ APS_sw158_dasStatus2 m158 : 26|1@1+ (1,0) [0|1] "" Vector__XXX
 SG_ APS_sw158_dasSteeringControl m158 : 27|1@1+ (1,0) [0|1] "" Vector__XXX
 SG_ APS_sw158_dasVisualDebug m158 : 28|1@1+ (1,0) [0|1] "" Vector__XXX
 SG_ APS_sw158_dasSteeringControlPty m158 : 29|1@1+ (1,0) [0|1] "" Vector__XXX
 SG_ APS_sw158_dasChNm m158 : 30|1@1+ (1,0) [0|1] "" Vector__XXX
 SG_ APS_sw158_dasStatusPty m158 : 31|1@1+ (1,0) [0|1] "" Vector__XXX
 SG_ APS_sw158_dasStatus2Pty m158 : 32|1@1+ (1,0) [0|1] "" Vector__XXX
 SG_ APS_sw158_dasMatrixHighBeamRqVEH m158 : 33|1@1+ (1,0) [0|1] "" Vector__XXX
 SG_ APS_sw158_dasMatrixBendAngleRqPt m158 : 34|1@1+ (1,0) [0|1] "" Vector__XXX
 SG_ APS_sw158_dasBodyControls2VEH m158 : 35|1@1+ (1,0) [0|1] "" Vector__XXX
 SG_ APS_sw158_timeSinceLastMsg m158 : 40|24@1+ (1,0) [0|16777215] "" Vector__XXX
 SG_ APS_sw159_apbCriticalReason m159 : 16|4@1+ (1,0) [0|15] "" Vector__XXX
 SG_ APS_sw159_apbTimesyncStatus m159 : 24|32@1+ (1,0) [0|4294967295] "" Vector__XXX
 SG_ APS_sw160_mismatchType m160 : 16|1@1+ (1,0) [0|1] "" Vector__XXX
 SG_ APS_sw160_actualHash m160 : 24|24@1+ (1,0) [0|16777215] "" Vector__XXX
 SG_ APS_sw160_expectedHash m160 : 48|16@1+ (1,0) [0|65535] "" Vector__XXX
 SG_ APS_sw161_antennaDisconnected m161 : 16|1@1+ (1,0) [0|1] "" Vector__XXX
 SG_ APS_sw172_prolongedUiMia m172 : 16|1@1+ (1,0) [0|1] "" Vector__XXX
 SG_ APS_sw172_uiMiaAtBootup m172 : 17|1@1+ (1,0) [0|1] "" Vector__XXX
 SG_ APS_sw188_otherTurbo m188 : 16|2@1+ (1,0) [0|3] "" Vector__XXX
 SG_ APS_sw188_arbUartMiaState m188 : 18|1@1+ (1,0) [0|1] "" Vector__XXX
 SG_ APS_sw188_powerUartMiaState m188 : 19|1@1+ (1,0) [0|1] "" Vector__XXX
 SG_ APS_sw188_faultsUartMiaState m188 : 20|1@1+ (1,0) [0|1] "" Vector__XXX
 SG_ APS_sw188_sleepUartMiaState m188 : 21|1@1+ (1,0) [0|1] "" Vector__XXX
 SG_ APS_sw188_resetUartMiaState m188 : 22|1@1+ (1,0) [0|1] "" Vector__XXX
 SG_ APS_sw188_statMonUartMiaState m188 : 23|1@1+ (1,0) [0|1] "" Vector__XXX
 SG_ APS_sw188_wdogStateUartMiaState m188 : 24|1@1+ (1,0) [0|1] "" Vector__XXX
 SG_ APS_sw188_critReasUartMiaState m188 : 25|1@1+ (1,0) [0|1] "" Vector__XXX
 SG_ APS_sw189_AP_vehicleState10Hz m189 : 16|1@1+ (1,0) [0|1] "" Vector__XXX
 SG_ APS_sw189_AP_vehicleState1Hz m189 : 17|1@1+ (1,0) [0|1] "" Vector__XXX
 SG_ APS_sw190_IBST_status m190 : 16|1@1+ (1,0) [0|1] "" Vector__XXX
 SG_ APS_sw192_CANbus m192 : 16|3@1+ (1,0) [0|7] "" Vector__XXX
 SG_ APS_sw192_SWTxQueueFull m192 : 19|1@1+ (1,0) [0|1] "" Vector__XXX
 SG_ APS_sw192_Busoff m192 : 20|1@1+ (1,0) [0|1] "" Vector__XXX
 SG_ APS_sw192_UncorrectedBitError m192 : 21|1@1+ (1,0) [0|1] "" Vector__XXX
 SG_ APS_sw192_CorrectedBitError m192 : 22|1@1+ (1,0) [0|1] "" Vector__XXX
 SG_ APS_sw192_ErrorPassive m192 : 23|1@1+ (1,0) [0|1] "" Vector__XXX
 SG_ APS_sw192_RamAccessFailed m192 : 24|1@1+ (1,0) [0|1] "" Vector__XXX
 SG_ APS_sw192_RxMsgLost m192 : 25|1@1+ (1,0) [0|1] "" Vector__XXX
 SG_ APS_sw192_msgIo m192 : 26|2@1+ (1,0) [0|3] "" Vector__XXX
 SG_ APS_sw192_queueFailure m192 : 28|2@1+ (1,0) [0|3] "" Vector__XXX
 SG_ APS_sw192_msgId m192 : 32|11@1+ (1,0) [0|2047] "" Vector__XXX
 SG_ APS_sw199_abortCodeDas m199 : 16|6@1+ (1,0) [0|63] "" Vector__XXX
 SG_ APS_sw199_abortCodePARK m199 : 22|5@1+ (1,0) [0|30] "" Vector__XXX
 SG_ APS_sw199_currentSTW m199 : 27|14@1+ (0.1,-819.2) [-819.2|819.1] "deg" Vector__XXX
 SG_ APS_sw199_currentSpeed m199 : 41|8@1+ (0.1,-12.2) [-12.2|13.3] "mph" Vector__XXX
 SG_ APS_sw199_internalState m199 : 49|4@1+ (1,0) [0|15] "" Vector__XXX
 SG_ APS_sw199_maxSpeed m199 : 53|7@1+ (0.2,-12.2) [-12.2|13.2] "mph" Vector__XXX
 SG_ APS_sw199_numShifts m199 : 60|4@1+ (1,0) [0|15] "" Vector__XXX
 SG_ APS_sw203_controlType m203 : 16|4@1+ (1,0) [0|14] "" Vector__XXX
 SG_ APS_sw203_curbType m203 : 20|2@1+ (1,0) [0|3] "" Vector__XXX
 SG_ APS_sw203_roadClass m203 : 22|3@1+ (1,0) [0|7] "" Vector__XXX
 SG_ APS_sw203_slotSizeX m203 : 25|8@1+ (4,0) [0|1020] "cm" Vector__XXX
 SG_ APS_sw203_slotSizeY m203 : 33|8@1+ (4,0) [0|1020] "cm" Vector__XXX
 SG_ APS_sw203_startDistance m203 : 41|11@1+ (1,0) [0|2047] "cm" Vector__XXX
 SG_ APS_sw203_vehicleSkew m203 : 52|12@1+ (0.002,0) [0|8.19] "radians" Vector__XXX
 SG_ APS_sw204_frLeft m204 : 16|8@1+ (1,0) [0|255] "cm" Vector__XXX
 SG_ APS_sw204_frLeftMiddle m204 : 24|8@1+ (1,0) [0|255] "cm" Vector__XXX
 SG_ APS_sw204_frMiddle m204 : 32|8@1+ (1,0) [0|255] "cm" Vector__XXX
 SG_ APS_sw204_frRight m204 : 40|8@1+ (1,0) [0|255] "cm" Vector__XXX
 SG_ APS_sw204_frRightMiddle m204 : 48|8@1+ (1,0) [0|255] "cm" Vector__XXX
 SG_ APS_sw204_maxSpeed m204 : 56|8@1+ (0.1,-12.2) [-12.2|13.3] "mph" Vector__XXX
 SG_ APS_sw205_oocDistance m205 : 16|8@1+ (1,0) [0|255] "cm" Vector__XXX
 SG_ APS_sw205_rrLeft m205 : 24|8@1+ (1,0) [0|255] "cm" Vector__XXX
 SG_ APS_sw205_rrLeftMiddle m205 : 32|8@1+ (1,0) [0|255] "cm" Vector__XXX
 SG_ APS_sw205_rrMiddle m205 : 40|8@1+ (1,0) [0|255] "cm" Vector__XXX
 SG_ APS_sw205_rrRight m205 : 48|8@1+ (1,0) [0|255] "cm" Vector__XXX
 SG_ APS_sw205_rrRightMiddle m205 : 56|8@1+ (1,0) [0|255] "cm" Vector__XXX
 SG_ APS_sw235_resetOrigin m235 : 16|2@1+ (1,0) [0|3] "" Vector__XXX
 SG_ APS_sw235_generalUnrecoverable m235 : 18|1@1+ (1,0) [0|1] "" Vector__XXX
 SG_ APS_sw235_pgoodUnrecoverable m235 : 19|1@1+ (1,0) [0|1] "" Vector__XXX
 SG_ APS_sw235_faultUnrecoverable m235 : 20|1@1+ (1,0) [0|1] "" Vector__XXX
 SG_ APS_sw235_12VFuseUnrecoverable m235 : 21|1@1+ (1,0) [0|1] "" Vector__XXX
 SG_ APS_sw235_pgoodLevelUnrcvrble m235 : 22|1@1+ (1,0) [0|1] "" Vector__XXX
 SG_ APS_sw235_faultLevelUnrcvrble m235 : 23|1@1+ (1,0) [0|1] "" Vector__XXX
 SG_ APS_sw235_12VFuseLvlUnrcvrble m235 : 24|1@1+ (1,0) [0|1] "" Vector__XXX
 SG_ APS_sw235_localSoftwareFault m235 : 25|1@1+ (1,0) [0|1] "" Vector__XXX
 SG_ APS_sw235_unrecoverableFailReset m235 : 26|1@1+ (1,0) [0|1] "" Vector__XXX
 SG_ APS_sw235_generalGic m235 : 27|1@1+ (1,0) [0|1] "" Vector__XXX
 SG_ APS_sw235_a72WdtTimeout m235 : 28|1@1+ (1,0) [0|1] "" Vector__XXX
 SG_ APS_sw235_generalScs m235 : 29|1@1+ (1,0) [0|1] "" Vector__XXX
 SG_ APS_sw235_generalUnexpected m235 : 30|1@1+ (1,0) [0|1] "" Vector__XXX
 SG_ APS_sw235_canUncorrectedBitError m235 : 31|1@1+ (1,0) [0|1] "" Vector__XXX
 SG_ APS_sw235_canExitBusoffFailed m235 : 32|1@1+ (1,0) [0|1] "" Vector__XXX
 SG_ APS_sw235_txEnFdbckNotExpected m235 : 33|1@1+ (1,0) [0|1] "" Vector__XXX
 SG_ APS_sw235_nocSmsFailed m235 : 34|1@1+ (1,0) [0|1] "" Vector__XXX
 SG_ APS_sw235_nocCamFailed m235 : 35|1@1+ (1,0) [0|1] "" Vector__XXX
 SG_ APS_sw235_nocCoreFailed m235 : 36|1@1+ (1,0) [0|1] "" Vector__XXX
 SG_ APS_sw235_nocScsFailed m235 : 37|1@1+ (1,0) [0|1] "" Vector__XXX
 SG_ APS_sw235_model3UiReset m235 : 38|1@1+ (1,0) [0|1] "" Vector__XXX
 SG_ APS_sw235_modelsUiReset m235 : 39|1@1+ (1,0) [0|1] "" Vector__XXX
 SG_ APS_sw235_pmicApOnPrpUnrcvrble m235 : 40|1@1+ (1,0) [0|1] "" Vector__XXX
 SG_ APS_sw235_apOnReadyTimeout m235 : 41|1@1+ (1,0) [0|1] "" Vector__XXX
 SG_ APS_sw235_pmicApOnWaitUnrcvrble m235 : 42|1@1+ (1,0) [0|1] "" Vector__XXX
 SG_ APS_sw235_apBootingTimeout m235 : 43|1@1+ (1,0) [0|1] "" Vector__XXX
 SG_ APS_sw235_pmicApOffWaitUnrcvrble m235 : 44|1@1+ (1,0) [0|1] "" Vector__XXX
 SG_ APS_sw235_resetBeingSent m235 : 45|1@1+ (1,0) [0|1] "" Vector__XXX
 SG_ APS_sw235_udsResetBeingSent m235 : 46|1@1+ (1,0) [0|1] "" Vector__XXX
 SG_ APS_sw235_smsWdtTimeout m235 : 47|1@1+ (1,0) [0|1] "" Vector__XXX
 SG_ APS_sw235_smsCanApHealthTimeout m235 : 48|1@1+ (1,0) [0|1] "" Vector__XXX
 SG_ APS_sw235_smsTaskWdtTimeout m235 : 49|1@1+ (1,0) [0|1] "" Vector__XXX
 SG_ APS_sw236_fifoSizeInvalid m236 : 16|1@1+ (1,0) [0|1] "" Vector__XXX
 SG_ APS_sw236_nocRemapInvalid m236 : 17|1@1+ (1,0) [0|1] "" Vector__XXX
 SG_ APS_sw236_txFifoInvalid m236 : 18|1@1+ (1,0) [0|1] "" Vector__XXX
 SG_ APS_sw236_rxFifoInvalid m236 : 19|1@1+ (1,0) [0|1] "" Vector__XXX
 SG_ APS_sw237_faultSource m237 : 16|7@1+ (1,0) [0|127] "" Vector__XXX
 SG_ APS_sw237_peerSoCFaulted m237 : 23|1@1+ (1,0) [0|1] "" Vector__XXX
 SG_ APS_sw242_instance m242 : 16|3@1+ (1,0) [0|7] "" Vector__XXX
 SG_ APS_sw242_clusterSRAMMBISTFailed m242 : 19|1@1+ (1,0) [0|1] "" Vector__XXX
 SG_ APS_sw242_SRAMBankMBISTFailed m242 : 20|1@1+ (1,0) [0|1] "" Vector__XXX
 SG_ APS_sw243_instance m243 : 16|3@1+ (1,0) [0|7] "" Vector__XXX
 SG_ APS_sw243_errorStatus m243 : 24|8@1+ (1,0) [0|255] "" Vector__XXX
 SG_ APS_sw243_extendedErrorStatus m243 : 32|24@1+ (1,0) [0|16777215] "" Vector__XXX
 SG_ APS_sw244_instance m244 : 16|3@1+ (1,0) [0|7] "" Vector__XXX
 SG_ APS_sw244_exceptionCode m244 : 24|8@1+ (1,0) [0|255] "" Vector__XXX
 SG_ APS_sw245_unknownMACAddrByte0 m245 : 16|8@1+ (1,0) [0|255] "" Vector__XXX
 SG_ APS_sw245_unknownMACAddrByte1 m245 : 24|8@1+ (1,0) [0|255] "" Vector__XXX
 SG_ APS_sw245_unknownMACAddrByte2 m245 : 32|8@1+ (1,0) [0|255] "" Vector__XXX
 SG_ APS_sw245_unknownMACAddrByte3 m245 : 40|8@1+ (1,0) [0|255] "" Vector__XXX
 SG_ APS_sw245_unknownMACAddrByte4 m245 : 48|8@1+ (1,0) [0|255] "" Vector__XXX
 SG_ APS_sw245_unknownMACAddrByte5 m245 : 56|8@1+ (1,0) [0|255] "" Vector__XXX
 SG_ APS_sw246_ethloopSwitchPort0 m246 : 16|1@1+ (1,0) [0|1] "" Vector__XXX
 SG_ APS_sw246_ethloopSwitchPort1 m246 : 17|1@1+ (1,0) [0|1] "" Vector__XXX
 SG_ APS_sw246_ethloopSwitchPort2 m246 : 18|1@1+ (1,0) [0|1] "" Vector__XXX
 SG_ APS_sw246_ethloopSwitchPort3 m246 : 19|1@1+ (1,0) [0|1] "" Vector__XXX
 SG_ APS_sw246_ethloopSwitchPort4 m246 : 20|1@1+ (1,0) [0|1] "" Vector__XXX
 SG_ APS_sw246_ethloopSwitchPort5 m246 : 21|1@1+ (1,0) [0|1] "" Vector__XXX
 SG_ APS_sw246_ethloopSwitchPort6 m246 : 22|1@1+ (1,0) [0|1] "" Vector__XXX
 SG_ APS_sw246_ethloopSwitchPort7 m246 : 23|1@1+ (1,0) [0|1] "" Vector__XXX
 SG_ APS_sw247_crcError m247 : 16|1@1+ (1,0) [0|1] "" Vector__XXX
 SG_ APS_sw247_dribbleError m247 : 17|1@1+ (1,0) [0|1] "" Vector__XXX
 SG_ APS_sw247_receiveError m247 : 18|1@1+ (1,0) [0|1] "" Vector__XXX
 SG_ APS_sw247_wdogTimeout m247 : 19|1@1+ (1,0) [0|1] "" Vector__XXX
 SG_ APS_sw247_overflowError m247 : 20|1@1+ (1,0) [0|1] "" Vector__XXX
 SG_ APS_sw247_giantPacket m247 : 21|1@1+ (1,0) [0|1] "" Vector__XXX
 SG_ APS_sw247_destAddrFilterFail m247 : 22|1@1+ (1,0) [0|1] "" Vector__XXX
 SG_ APS_sw247_saAddressFilterFail m247 : 23|1@1+ (1,0) [0|1] "" Vector__XXX
 SG_ APS_sw248_ethloopSwitchPort2Sqi m248 : 16|3@1+ (1,0) [0|7] "" Vector__XXX
 SG_ APS_sw248_ethloopSwitchPort3Sqi m248 : 19|3@1+ (1,0) [0|7] "" Vector__XXX
 SG_ APS_sw249_ufsInitFailureReason m249 : 16|3@1+ (1,0) [0|7] "" Vector__XXX
 SG_ APS_sw252_ethSwitchPort2 m252 : 16|1@1+ (1,0) [0|1] "" Vector__XXX
 SG_ APS_sw253_apWaitForShutdownTimeo m253 : 16|1@1+ (1,0) [0|1] "" Vector__XXX
 SG_ APS_sw253_apOffPrepareTimeout m253 : 17|1@1+ (1,0) [0|1] "" Vector__XXX
 SG_ APS_sw253_apSuspendedTimeout m253 : 18|1@1+ (1,0) [0|1] "" Vector__XXX
 SG_ APS_sw253_socOffReadyTimeout m253 : 19|1@1+ (1,0) [0|1] "" Vector__XXX
 SG_ APS_sw253_apInLinuxTimeout m253 : 20|1@1+ (1,0) [0|1] "" Vector__XXX
 SG_ APS_sw253_apInCorebootTimeout m253 : 21|1@1+ (1,0) [0|1] "" Vector__XXX
 SG_ APS_sw253_apBootingTimeout m253 : 22|1@1+ (1,0) [0|1] "" Vector__XXX
 SG_ APS_sw253_apOnTimeout m253 : 23|1@1+ (1,0) [0|1] "" Vector__XXX
 SG_ APS_sw254_waitForBusSilenceTimeo m254 : 16|1@1+ (1,0) [0|1] "" Vector__XXX
 SG_ APS_sw254_sleepReadyTimeout m254 : 17|1@1+ (1,0) [0|1] "" Vector__XXX
 SG_ APS_sw254_sleepingTimeout m254 : 18|1@1+ (1,0) [0|1] "" Vector__XXX
 SG_ APS_sw255_unknownBootError m255 : 16|1@1+ (1,0) [0|1] "" Vector__XXX
 SG_ APS_sw255_adcWrapperInitBootErro m255 : 17|1@1+ (1,0) [0|1] "" Vector__XXX
 SG_ APS_sw255_boardRevisionInitBootE m255 : 18|1@1+ (1,0) [0|1] "" Vector__XXX
 SG_ APS_sw255_i2cInitBootError m255 : 19|1@1+ (1,0) [0|1] "" Vector__XXX
 SG_ APS_sw255_provisionInitBootError m255 : 20|1@1+ (1,0) [0|1] "" Vector__XXX
 SG_ APS_sw255_rtcInitBootError m255 : 21|1@1+ (1,0) [0|1] "" Vector__XXX
 SG_ APS_sw255_vrmInitConfigBootError m255 : 22|1@1+ (1,0) [0|1] "" Vector__XXX
 SG_ APS_sw255_powerAonIoBootError m255 : 23|1@1+ (1,0) [0|1] "" Vector__XXX
 SG_ APS_sw255_bl1TocInitBootError m255 : 24|1@1+ (1,0) [0|1] "" Vector__XXX
 SG_ APS_sw255_tmuInitBootError m255 : 25|1@1+ (1,0) [0|1] "" Vector__XXX
 SG_ APS_sw255_udpInitBootError m255 : 26|1@1+ (1,0) [0|1] "" Vector__XXX
 SG_ APS_sw255_gpsInitBootError m255 : 27|1@1+ (1,0) [0|1] "" Vector__XXX
 SG_ APS_sw255_canInitBootError m255 : 28|1@1+ (1,0) [0|1] "" Vector__XXX
 SG_ APS_sw255_dfuCheckinSubsystemBoo m255 : 29|1@1+ (1,0) [0|1] "" Vector__XXX
 SG_ APS_sw255_sectorProtectionBootEr m255 : 30|1@1+ (1,0) [0|1] "" Vector__XXX
 SG_ APS_sw255_flashOpBootError m255 : 31|1@1+ (1,0) [0|1] "" Vector__XXX
 SG_ APS_sw280_pepsStatus m280 : 16|1@1+ (1,0) [0|1] "" Vector__XXX
 SG_ APS_sw281_rearSteerStatus m281 : 16|1@1+ (1,0) [0|1] "" Vector__XXX
 SG_ APS_sw288_status m288 : 16|1@1+ (1,0) [0|1] "" Vector__XXX
 SG_ APS_sw289_turboTemperature m289 : 16|8@1- (1,0) [-128|127] "degC" Vector__XXX
 SG_ APS_sw289_turboProbe m289 : 24|6@1+ (1,0) [0|63] "" Vector__XXX
 SG_ APS_sw289_peer_turboTemperature m289 : 32|8@1- (1,0) [-128|127] "degC" Vector__XXX
 SG_ APS_sw289_peer_turboProbe m289 : 40|6@1+ (1,0) [0|63] "" Vector__XXX

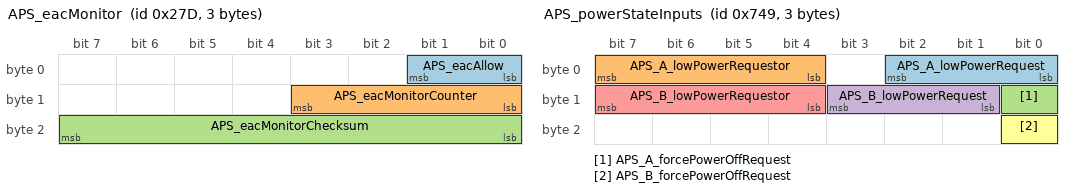
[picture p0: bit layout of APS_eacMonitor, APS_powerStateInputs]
BO_ 637 APS_eacMonitor: 3 APS
 SG_ APS_eacAllow : 0|2@1+ (1,0) [0|2] "" Vector__XXX
 SG_ APS_eacMonitorCounter : 8|4@1+ (1,0) [0|15] "" Vector__XXX
 SG_ APS_eacMonitorChecksum : 16|8@1+ (1,0) [0|255] "" Vector__XXX

BO_ 1865 APS_powerStateInputs: 3 APS
 SG_ APS_A_lowPowerRequest : 0|3@1+ (1,0) [0|7] "" Vector__XXX
 SG_ APS_A_lowPowerRequestor : 4|4@1+ (1,0) [0|15] "" Vector__XXX
 SG_ APS_A_forcePowerOffRequest : 8|1@1+ (1,0) [0|1] "" Vector__XXX
 SG_ APS_B_lowPowerRequest : 9|3@1+ (1,0) [0|7] "" Vector__XXX
 SG_ APS_B_lowPowerRequestor : 12|4@1+ (1,0) [0|15] "" Vector__XXX
 SG_ APS_B_forcePowerOffRequest : 16|1@1+ (1,0) [0|1] "" Vector__XXX

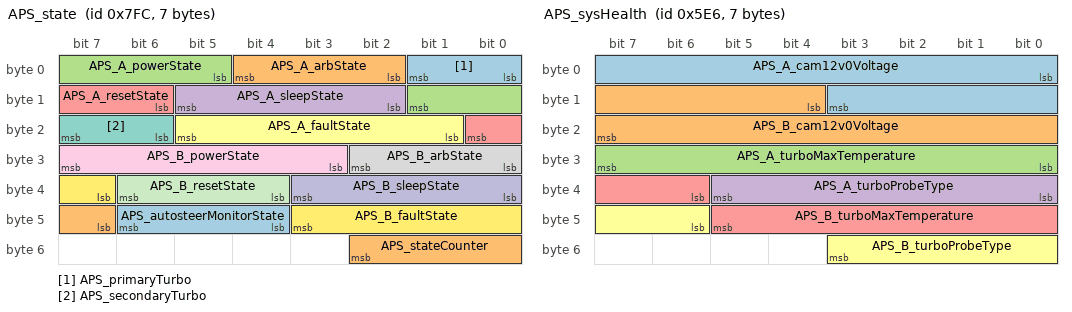
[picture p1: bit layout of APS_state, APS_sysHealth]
BO_ 2044 APS_state: 7 APS
 SG_ APS_primaryTurbo : 0|2@1+ (1,0) [0|3] "" Vector__XXX
 SG_ APS_A_arbState : 2|3@1+ (1,0) [0|7] "" Vector__XXX
 SG_ APS_A_powerState : 5|5@1+ (1,0) [0|31] "" Vector__XXX
 SG_ APS_A_sleepState : 10|4@1+ (1,0) [0|15] "" Vector__XXX
 SG_ APS_A_resetState : 14|3@1+ (1,0) [0|7] "" Vector__XXX
 SG_ APS_A_faultState : 17|5@1+ (1,0) [0|31] "" Vector__XXX
 SG_ APS_secondaryTurbo : 22|2@1+ (1,0) [0|3] "" Vector__XXX
 SG_ APS_B_arbState : 24|3@1+ (1,0) [0|7] "" Vector__XXX
 SG_ APS_B_powerState : 27|5@1+ (1,0) [0|31] "" Vector__XXX
 SG_ APS_B_sleepState : 32|4@1+ (1,0) [0|15] "" Vector__XXX
 SG_ APS_B_resetState : 36|3@1+ (1,0) [0|7] "" Vector__XXX
 SG_ APS_B_faultState : 39|5@1+ (1,0) [0|31] "" Vector__XXX
 SG_ APS_autosteerMonitorState : 44|3@1+ (1,0) [0|7] "" Vector__XXX
 SG_ APS_stateCounter : 47|4@1+ (1,0) [0|15] "" Vector__XXX

BO_ 970 APS_status: 8 APS
 SG_ APS_appStatusMonitorState : 0|3@1+ (1,0) [0|7] "" Vector__XXX
 SG_ APS_vehBehaviorState : 4|4@1+ (1,0) [0|15] "" Vector__XXX
 SG_ APS_canMaster : 8|2@1+ (1,0) [0|2] "" Vector__XXX
 SG_ APS_appGpioState : 10|2@1+ (1,0) [0|3] "" Vector__XXX
 SG_ APS_eacInternalState : 12|3@1+ (1,0) [0|7] "" Vector__XXX
 SG_ APS_switchState : 15|1@1+ (1,0) [0|1] "" Vector__XXX
 SG_ APS_apbStatusMonitorState : 16|3@1+ (1,0) [0|7] "" Vector__XXX
 SG_ APS_apbGpioState : 20|2@1+ (1,0) [0|3] "" Vector__XXX
 SG_ APS_statusCounter : 22|4@1+ (1,0) [0|15] "" Vector__XXX
 SG_ APS_locLimitReason : 26|3@1+ (1,0) [0|7] "" Vector__XXX
 SG_ APS_appPowerStateRequest : 29|2@1+ (1,0) [0|3] "" Vector__XXX
 SG_ APS_appPowerStateReason : 31|4@1+ (1,0) [0|15] "" Vector__XXX
 SG_ APS_apbPowerStateRequest : 36|2@1+ (1,0) [0|3] "" Vector__XXX
 SG_ APS_apbPowerStateReason : 38|4@1+ (1,0) [0|15] "" Vector__XXX
 SG_ APS_heaterStateDebug : 43|3@1+ (1,0) [0|6] "" Vector__XXX
 SG_ APS_autosummonCounter : 46|3@1+ (1,0) [0|7] "" Vector__XXX
 SG_ APS_autosummonAlert : 49|1@1+ (1,0) [0|1] "" Vector__XXX
 SG_ APS_gpsAntennaState : 50|2@1+ (1,0) [0|3] "" Vector__XXX
 SG_ APS_arbState : 52|3@1+ (1,0) [0|7] "" Vector__XXX
 SG_ APS_socPowerOperatingMode : 55|2@1+ (1,0) [0|3] "" Vector__XXX
 SG_ APS_otherArbState : 57|3@1+ (1,0) [0|7] "" Vector__XXX

BO_ 1510 APS_sysHealth: 7 APS
 SG_ APS_A_cam12v0Voltage : 0|12@1+ (0.0048,0) [0|19.44] "V" Vector__XXX
 SG_ APS_B_cam12v0Voltage : 12|12@1+ (0.0048,0) [0|19.44] "V" Vector__XXX
 SG_ APS_A_turboMaxTemperature : 24|8@1- (1,0) [-128|127] "degC" Vector__XXX
 SG_ APS_A_turboProbeType : 32|6@1+ (1,0) [0|62] "" Vector__XXX
 SG_ APS_B_turboMaxTemperature : 38|8@1- (1,0) [-128|127] "degC" Vector__XXX
 SG_ APS_B_turboProbeType : 46|6@1+ (1,0) [0|62] "" Vector__XXX

BO_ 811 APS_warningMatrix0: 8 APS
 SG_ APS_w001_DEPRECATED : 0|1@1+ (1,0) [0|1] "" Vector__XXX
 SG_ APS_w002_ldwDisabled : 1|1@1+ (1,0) [0|1] "" Vector__XXX
 SG_ APS_w003_isaDisabled : 2|1@1+ (1,0) [0|1] "" Vector__XXX
 SG_ APS_w004_accDisabled : 3|1@1+ (1,0) [0|1] "" Vector__XXX
 SG_ APS_w005_fcwCancelled : 4|1@1+ (1,0) [0|1] "" Vector__XXX
 SG_ APS_w006_aebCancelled : 5|1@1+ (1,0) [0|1] "" Vector__XXX
 SG_ APS_w007_ahlbDisabled : 6|1@1+ (1,0) [0|1] "" Vector__XXX
 SG_ APS_w008_parkDisabled : 7|1@1+ (1,0) [0|1] "" Vector__XXX
 SG_ APS_w009_aebFault : 8|1@1+ (1,0) [0|1] "" Vector__XXX
 SG_ APS_w010_radcCalibIssue : 9|1@1+ (1,0) [0|1] "" Vector__XXX
 SG_ APS_w011_scaEvent : 10|1@1+ (1,0) [0|1] "" Vector__XXX
 SG_ APS_w012_Cam_BootFailure : 11|1@1+ (1,0) [0|1] "" Vector__XXX
 SG_ APS_w013_Cam_Watchdog : 12|1@1+ (1,0) [0|1] "" Vector__XXX
 SG_ APS_w014_swAssert : 13|1@1+ (1,0) [0|1] "" Vector__XXX
 SG_ APS_w015_Camera_Failsafes : 14|1@1+ (1,0) [0|1] "" Vector__XXX
 SG_ APS_w016_aeb_e_event : 15|1@1+ (1,0) [0|1] "" Vector__XXX
 SG_ APS_w017_Cam_Msg_MIA : 16|1@1+ (1,0) [0|1] "" Vector__XXX
 SG_ APS_w018_ECU_Power_Issue : 17|1@1+ (1,0) [0|1] "" Vector__XXX
 SG_ APS_w019_ECU_Stack_Overflow : 18|1@1+ (1,0) [0|1] "" Vector__XXX
 SG_ APS_w020_ECU_checkstopError : 19|1@1+ (1,0) [0|1] "" Vector__XXX
 SG_ APS_w021_ECU_Temperature_Issue : 20|1@1+ (1,0) [0|1] "" Vector__XXX
 SG_ APS_w022_ECU_EEPROM_Failure : 21|1@1+ (1,0) [0|1] "" Vector__XXX
 SG_ APS_w023_ECU_Cam_Statemismatc : 22|1@1+ (1,0) [0|1] "" Vector__XXX
 SG_ APS_w024_ECU_Watchdog_Reset : 23|1@1+ (1,0) [0|1] "" Vector__XXX
 SG_ APS_w025_LC_Steering_Override : 24|1@1+ (1,0) [0|1] "" Vector__XXX
 SG_ APS_w026_ECU_timingIssue : 25|1@1+ (1,0) [0|1] "" Vector__XXX
 SG_ APS_w027_ECU_Reset_Fault : 26|1@1+ (1,0) [0|1] "" Vector__XXX
 SG_ APS_w028_spi_rx_error : 27|1@1+ (1,0) [0|1] "" Vector__XXX
 SG_ APS_w029_spi_tx_error : 28|1@1+ (1,0) [0|1] "" Vector__XXX
 SG_ APS_w030_Heater_Issue : 29|1@1+ (1,0) [0|1] "" Vector__XXX
 SG_ APS_w031_canRxError : 30|1@1+ (1,0) [0|1] "" Vector__XXX
 SG_ APS_w032_canTxError : 31|1@1+ (1,0) [0|1] "" Vector__XXX
 SG_ APS_w033_gtwMia : 32|1@1+ (1,0) [0|1] "" Vector__XXX
 SG_ APS_w034_sccmMia : 33|1@1+ (1,0) [0|1] "" Vector__XXX
 SG_ APS_w035_espMia : 34|1@1+ (1,0) [0|1] "" Vector__XXX
 SG_ APS_w036_bdyMia : 35|1@1+ (1,0) [0|1] "" Vector__XXX
 SG_ APS_w037_camTacIssue : 36|1@1+ (1,0) [0|1] "" Vector__XXX
 SG_ APS_w038_camFailure : 37|1@1+ (1,0) [0|1] "" Vector__XXX
 SG_ APS_w039_sdm_rcm_Mia : 38|1@1+ (1,0) [0|1] "" Vector__XXX
 SG_ APS_w040_autopilotAngleSaturated : 39|1@1+ (1,0) [0|1] "" Vector__XXX
 SG_ APS_w041_autopilotRateSaturated : 40|1@1+ (1,0) [0|1] "" Vector__XXX
 SG_ APS_w042_autopilotAborting : 41|1@1+ (1,0) [0|1] "" Vector__XXX
 SG_ APS_w043_camLongRunTime : 42|1@1+ (1,0) [0|1] "" Vector__XXX
 SG_ APS_w044_appMobileyeFailure : 43|1@1+ (1,0) [0|1] "" Vector__XXX
 SG_ APS_w045_radMia : 44|1@1+ (1,0) [0|1] "" Vector__XXX
 SG_ APS_w046_eepromRecordAbsent : 45|1@1+ (1,0) [0|1] "" Vector__XXX
 SG_ APS_w047_edrEvent : 46|1@1+ (1,0) [0|1] "" Vector__XXX
 SG_ APS_w048_DAS_Features_Disabled : 47|1@1+ (1,0) [0|1] "" Vector__XXX
 SG_ APS_w049_eyeqVersionMismatch : 48|1@1+ (1,0) [0|1] "" Vector__XXX
 SG_ APS_w050_aeb_event : 49|1@1+ (1,0) [0|1] "" Vector__XXX
 SG_ APS_w051_radcEcuIssue : 50|1@1+ (1,0) [0|1] "" Vector__XXX
 SG_ APS_w052_radcSensorIssue : 51|1@1+ (1,0) [0|1] "" Vector__XXX
 SG_ APS_w053_radcCommIssue : 52|1@1+ (1,0) [0|1] "" Vector__XXX
 SG_ APS_w054_camAutofix : 53|1@1+ (1,0) [0|1] "" Vector__XXX
 SG_ APS_w055_radcVersionMismatch : 54|1@1+ (1,0) [0|1] "" Vector__XXX
 SG_ APS_w056_diMia : 55|1@1+ (1,0) [0|1] "" Vector__XXX
 SG_ APS_w057_mcuMia : 56|1@1+ (1,0) [0|1] "" Vector__XXX
 SG_ APS_w058_epbMia : 57|1@1+ (1,0) [0|1] "" Vector__XXX
 SG_ APS_w059_parkMia : 58|1@1+ (1,0) [0|1] "" Vector__XXX
 SG_ APS_w060_fcw_event : 59|1@1+ (1,0) [0|1] "" Vector__XXX
 SG_ APS_w061_tasMia : 60|1@1+ (1,0) [0|1] "" Vector__XXX
 SG_ APS_w062_radcAlignment : 61|1@1+ (1,0) [0|1] "" Vector__XXX
 SG_ APS_w063_parkVersionMismatch : 62|1@1+ (1,0) [0|1] "" Vector__XXX
 SG_ APS_w064_epasMia : 63|1@1+ (1,0) [0|1] "" Vector__XXX

BO_ 876 APS_warningMatrix1: 8 APS
 SG_ APS_w065_deserializerOvercurrent : 0|1@1+ (1,0) [0|1] "" Vector__XXX
 SG_ APS_w066_deserializerLockLost : 1|1@1+ (1,0) [0|1] "" Vector__XXX
 SG_ APS_w067_steeringAlignment : 2|1@1+ (1,0) [0|1] "" Vector__XXX
 SG_ APS_w068_vlInconsistency : 3|1@1+ (1,0) [0|1] "" Vector__XXX
 SG_ APS_w069_apcSpaceMasked : 4|1@1+ (1,0) [0|1] "" Vector__XXX
 SG_ APS_w070_apcIncompleteCal : 5|1@1+ (1,0) [0|1] "" Vector__XXX
 SG_ APS_w071_selfparkStarted : 6|1@1+ (1,0) [0|1] "" Vector__XXX
 SG_ APS_w072_selfparkComplete : 7|1@1+ (1,0) [0|1] "" Vector__XXX
 SG_ APS_w073_issueEscalatedLDW : 8|1@1+ (1,0) [0|1] "" Vector__XXX
 SG_ APS_w074_inPathStationaryObst : 9|1@1+ (1,0) [0|1] "" Vector__XXX
 SG_ APS_w075_scMia : 10|1@1+ (1,0) [0|1] "" Vector__XXX
 SG_ APS_w076_mobilEyeSetC : 11|1@1+ (1,0) [0|1] "" Vector__XXX
 SG_ APS_w077_pmmActive : 12|1@1+ (1,0) [0|1] "" Vector__XXX
 SG_ APS_w078_pmmActive2 : 13|1@1+ (1,0) [0|1] "" Vector__XXX
 SG_ APS_w079_edrAvailable : 14|1@1+ (1,0) [0|1] "" Vector__XXX
 SG_ APS_w080_accFailedActivation : 15|1@1+ (1,0) [0|1] "" Vector__XXX
 SG_ APS_w081_pmmActiveBraking : 16|1@1+ (1,0) [0|1] "" Vector__XXX
 SG_ APS_w082_inPathFSviolation : 17|1@1+ (1,0) [0|1] "" Vector__XXX
 SG_ APS_w083_inPathRADObject : 18|1@1+ (1,0) [0|1] "" Vector__XXX
 SG_ APS_w084_pmmIPSO : 19|1@1+ (1,0) [0|1] "" Vector__XXX
 SG_ APS_w085_pmmSteering : 20|1@1+ (1,0) [0|1] "" Vector__XXX
 SG_ APS_w086_robCollision : 21|1@1+ (1,0) [0|1] "" Vector__XXX
 SG_ APS_w087_DEPRECATED : 22|1@1+ (1,0) [0|1] "" Vector__XXX
 SG_ APS_w088_DEPRECATED : 23|1@1+ (1,0) [0|1] "" Vector__XXX
 SG_ APS_w089_DEPRECATED : 24|1@1+ (1,0) [0|1] "" Vector__XXX
 SG_ APS_w090_DEPRECATED : 25|1@1+ (1,0) [0|1] "" Vector__XXX
 SG_ APS_w091_DEPRECATED : 26|1@1+ (1,0) [0|1] "" Vector__XXX
 SG_ APS_w092_DEPRECATED : 27|1@1+ (1,0) [0|1] "" Vector__XXX
 SG_ APS_w093_DEPRECATED : 28|1@1+ (1,0) [0|1] "" Vector__XXX
 SG_ APS_w094_DEPRECATED : 29|1@1+ (1,0) [0|1] "" Vector__XXX
 SG_ APS_w095_DEPRECATED : 30|1@1+ (1,0) [0|1] "" Vector__XXX
 SG_ APS_w096_DEPRECATED : 31|1@1+ (1,0) [0|1] "" Vector__XXX
 SG_ APS_w097_DEPRECATED : 32|1@1+ (1,0) [0|1] "" Vector__XXX
 SG_ APS_w098_DEPRECATED : 33|1@1+ (1,0) [0|1] "" Vector__XXX
 SG_ APS_w099_DEPRECATED : 34|1@1+ (1,0) [0|1] "" Vector__XXX
 SG_ APS_w100_DEPRECATED : 35|1@1+ (1,0) [0|1] "" Vector__XXX
 SG_ APS_w101_DEPRECATED : 36|1@1+ (1,0) [0|1] "" Vector__XXX
 SG_ APS_w102_DEPRECATED : 37|1@1+ (1,0) [0|1] "" Vector__XXX
 SG_ APS_w103_robExperimentalAEB : 38|1@1+ (1,0) [0|1] "" Vector__XXX
 SG_ APS_w104_DEPRECATED : 39|1@1+ (1,0) [0|1] "" Vector__XXX
 SG_ APS_w105_DEPRECATED : 40|1@1+ (1,0) [0|1] "" Vector__XXX
 SG_ APS_w106_torsionBarOffset : 41|1@1+ (1,0) [0|1] "" Vector__XXX

BO_ 1113 APS_warningMatrix2: 8 APS
 SG_ APS_w129_ECU_Power_Issue : 0|1@1+ (1,0) [0|1] "" Vector__XXX
 SG_ APS_w130_ECU_Thermal_Issue : 1|1@1+ (1,0) [0|1] "" Vector__XXX
 SG_ APS_w131_trap_exception : 2|1@1+ (1,0) [0|1] "" Vector__XXX
 SG_ APS_w132_appVersionMismatch : 3|1@1+ (1,0) [0|1] "" Vector__XXX
 SG_ APS_w133_ETHSwitchError : 4|1@1+ (1,0) [0|1] "" Vector__XXX
 SG_ APS_w134_appMia : 5|1@1+ (1,0) [0|1] "" Vector__XXX
 SG_ APS_w135_appCritical : 6|1@1+ (1,0) [0|1] "" Vector__XXX
 SG_ APS_w136_gpsDisabled : 7|1@1+ (1,0) [0|1] "" Vector__XXX
 SG_ APS_w137_gpsFaultReset : 8|1@1+ (1,0) [0|1] "" Vector__XXX
 SG_ APS_w138_gpsComIssue : 9|1@1+ (1,0) [0|1] "" Vector__XXX
 SG_ APS_w139_udpBufferOverflow : 10|1@1+ (1,0) [0|1] "" Vector__XXX
 SG_ APS_w140_vcfrontMiaVehicleBus : 11|1@1+ (1,0) [0|1] "" Vector__XXX
 SG_ APS_w141_rcmMiaPartyBus : 12|1@1+ (1,0) [0|1] "" Vector__XXX
 SG_ APS_w142_diMiaPartyBus : 13|1@1+ (1,0) [0|1] "" Vector__XXX
 SG_ APS_w143_espMiaPartyBus : 14|1@1+ (1,0) [0|1] "" Vector__XXX
 SG_ APS_w144_vcleftMiaPartyBus : 15|1@1+ (1,0) [0|1] "" Vector__XXX
 SG_ APS_w145_vcrightMiaPartyBus : 16|1@1+ (1,0) [0|1] "" Vector__XXX
 SG_ APS_w146_epas3pMiaPartyBus : 17|1@1+ (1,0) [0|1] "" Vector__XXX
 SG_ APS_w147_vcleftMiaVehBus : 18|1@1+ (1,0) [0|1] "" Vector__XXX
 SG_ APS_w148_vcrightMiaVehBus : 19|1@1+ (1,0) [0|1] "" Vector__XXX
 SG_ APS_w149_epblMiaVehBus : 20|1@1+ (1,0) [0|1] "" Vector__XXX
 SG_ APS_w150_sccmMiaVehBus : 21|1@1+ (1,0) [0|1] "" Vector__XXX
 SG_ APS_w151_apRecovered : 22|1@1+ (1,0) [0|1] "" Vector__XXX
 SG_ APS_w152_gpsFusionStatus : 23|1@1+ (1,0) [0|1] "" Vector__XXX
 SG_ APS_w153_eacInhibit : 24|1@1+ (1,0) [0|1] "" Vector__XXX
 SG_ APS_w155_ethLwipError : 26|1@1+ (1,0) [0|1] "" Vector__XXX
 SG_ APS_w156_lwipAssert : 27|1@1+ (1,0) [0|1] "" Vector__XXX
 SG_ APS_w157_autopilotReboot : 28|1@1+ (1,0) [0|1] "" Vector__XXX
 SG_ APS_w158_apbMia : 29|1@1+ (1,0) [0|1] "" Vector__XXX
 SG_ APS_w159_apbCritical : 30|1@1+ (1,0) [0|1] "" Vector__XXX
 SG_ APS_w160_apbVersionMismatch : 31|1@1+ (1,0) [0|1] "" Vector__XXX
 SG_ APS_w161_gpsAntennaDisconnected : 32|1@1+ (1,0) [0|1] "" Vector__XXX
 SG_ APS_w162_TurboA_DisRegPgoodErr : 33|1@1+ (1,0) [0|1] "" Vector__XXX
 SG_ APS_w163_TurboA_DisRegNFault : 34|1@1+ (1,0) [0|1] "" Vector__XXX
 SG_ APS_w164_TurboA_12VFuseFault : 35|1@1+ (1,0) [0|1] "" Vector__XXX
 SG_ APS_w165_TurboA_Temp_NOS : 36|1@1+ (1,0) [0|1] "" Vector__XXX
 SG_ APS_w166_TurboA_SMSLockStepErr : 37|1@1+ (1,0) [0|1] "" Vector__XXX
 SG_ APS_w167_TurboA_TMU_Throttle : 38|1@1+ (1,0) [0|1] "" Vector__XXX
 SG_ APS_w168_TurboA_SMS_WDOG : 39|1@1+ (1,0) [0|1] "" Vector__XXX
 SG_ APS_w169_TurboA_SCS_LKUP : 40|1@1+ (1,0) [0|1] "" Vector__XXX
 SG_ APS_w170_TurboA_A72_watchdog : 41|1@1+ (1,0) [0|1] "" Vector__XXX
 SG_ APS_w171_TurboA_SMS_taskUtilErr : 42|1@1+ (1,0) [0|1] "" Vector__XXX
 SG_ APS_w172_apFeaturesUnavailable : 43|1@1+ (1,0) [0|1] "" Vector__XXX
 SG_ APS_w178_TurboB_DisRegPgoodErr : 49|1@1+ (1,0) [0|1] "" Vector__XXX
 SG_ APS_w179_TurboB_DisRegNFault : 50|1@1+ (1,0) [0|1] "" Vector__XXX
 SG_ APS_w180_TurboB_12VFuseFault : 51|1@1+ (1,0) [0|1] "" Vector__XXX
 SG_ APS_w181_TurboB_Temp_NOS : 52|1@1+ (1,0) [0|1] "" Vector__XXX
 SG_ APS_w182_TurboB_SMSLockStepErr : 53|1@1+ (1,0) [0|1] "" Vector__XXX
 SG_ APS_w183_TurboB_TMU_Throttle : 54|1@1+ (1,0) [0|1] "" Vector__XXX
 SG_ APS_w184_TurboB_SMS_WDOG : 55|1@1+ (1,0) [0|1] "" Vector__XXX
 SG_ APS_w185_TurboB_SCS_LKUP : 56|1@1+ (1,0) [0|1] "" Vector__XXX
 SG_ APS_w186_TurboB_A72_watchdog : 57|1@1+ (1,0) [0|1] "" Vector__XXX
 SG_ APS_w187_TurboB_SMS_taskUtilErr : 58|1@1+ (1,0) [0|1] "" Vector__XXX
 SG_ APS_w188_otherTurboUartMIA : 59|1@1+ (1,0) [0|1] "" Vector__XXX
 SG_ APS_w189_vcfrontMiaPartyBus : 60|1@1+ (1,0) [0|1] "" Vector__XXX
 SG_ APS_w190_iboosterMia : 61|1@1+ (1,0) [0|1] "" Vector__XXX
 SG_ APS_w191_timesyncError : 62|1@1+ (1,0) [0|1] "" Vector__XXX
 SG_ APS_w192_CANFault : 63|1@1+ (1,0) [0|1] "" Vector__XXX

BO_ 848 APS_warningMatrix3: 8 APS
 SG_ APS_w193_camWindshieldUnclean : 0|1@1+ (1,0) [0|1] "" Vector__XXX
 SG_ APS_w194_accDriverResumeRqrd : 1|1@1+ (1,0) [0|1] "" Vector__XXX
 SG_ APS_w195_scwUnavailable : 2|1@1+ (1,0) [0|1] "" Vector__XXX
 SG_ APS_w196_stopSignWarning : 3|1@1+ (1,0) [0|1] "" Vector__XXX
 SG_ APS_w197_redLightWarning : 4|1@1+ (1,0) [0|1] "" Vector__XXX
 SG_ APS_w198_tsrUnavailable : 5|1@1+ (1,0) [0|1] "" Vector__XXX
 SG_ APS_w199_apcAbort : 6|1@1+ (1,0) [0|1] "" Vector__XXX
 SG_ APS_w200_lcSlowdown : 7|1@1+ (1,0) [0|1] "" Vector__XXX
 SG_ APS_w201_lcAborting : 8|1@1+ (1,0) [0|1] "" Vector__XXX
 SG_ APS_w202_scwNoisyEnvironment : 9|1@1+ (1,0) [0|1] "" Vector__XXX
 SG_ APS_w203_apcActivation : 10|1@1+ (1,0) [0|1] "" Vector__XXX
 SG_ APS_w204_apcFinalFront : 11|1@1+ (1,0) [0|1] "" Vector__XXX
 SG_ APS_w205_apcFinalRear : 12|1@1+ (1,0) [0|1] "" Vector__XXX
 SG_ APS_w206_autosteerNotEnabled : 13|1@1+ (1,0) [0|1] "" Vector__XXX
 SG_ APS_w207_autosteerUnavailable : 14|1@1+ (1,0) [0|1] "" Vector__XXX
 SG_ APS_w208_rackDetected : 15|1@1+ (1,0) [0|1] "" Vector__XXX
 SG_ APS_w209_autoSummonRequest : 16|1@1+ (1,0) [0|1] "" Vector__XXX
 SG_ APS_w210_camObstrcted : 17|1@1+ (1,0) [0|1] "" Vector__XXX
 SG_ APS_w211_accNoSeatBelt : 18|1@1+ (1,0) [0|1] "" Vector__XXX
 SG_ APS_w212_lcUnavailableStrikeOut : 19|1@1+ (1,0) [0|1] "" Vector__XXX
 SG_ APS_w213_autosteerStruckOut : 20|1@1+ (1,0) [0|1] "" Vector__XXX
 SG_ APS_w214_driverNotIntracting : 21|1@1+ (1,0) [0|1] "" Vector__XXX
 SG_ APS_w215_contDriverNotIntracting : 22|1@1+ (1,0) [0|1] "" Vector__XXX
 SG_ APS_w216_driverOverriding : 23|1@1+ (1,0) [0|1] "" Vector__XXX
 SG_ APS_w217_lcUnavailableSpeeding : 24|1@1+ (1,0) [0|1] "" Vector__XXX
 SG_ APS_w218_lcSpeedExceededLimit : 25|1@1+ (1,0) [0|1] "" Vector__XXX
 SG_ APS_w219_lcTempUnavailableSpeed : 26|1@1+ (1,0) [0|1] "" Vector__XXX
 SG_ APS_w220_lcTempUnavailableRoad : 27|1@1+ (1,0) [0|1] "" Vector__XXX
 SG_ APS_w221_accRadarBlind : 28|1@1+ (1,0) [0|1] "" Vector__XXX
 SG_ APS_w222_accCameraBlind : 29|1@1+ (1,0) [0|1] "" Vector__XXX
 SG_ APS_w223_accObjectInPath : 30|1@1+ (1,0) [0|1] "" Vector__XXX
 SG_ APS_w224_accCameraCalibration : 31|1@1+ (1,0) [0|1] "" Vector__XXX
 SG_ APS_w225_lcDegradedVisSpeedLmt : 32|1@1+ (1,0) [0|1] "" Vector__XXX
 SG_ APS_w226_lcCamCalNeededSpeedLmt : 33|1@1+ (1,0) [0|1] "" Vector__XXX
 SG_ APS_w227_virtualWallBlocked : 34|1@1+ (1,0) [0|1] "" Vector__XXX
 SG_ APS_w228_DEPRECATED : 35|1@1+ (1,0) [0|1] "" Vector__XXX
 SG_ APS_w229_alcUltrasoundDamaged : 36|1@1+ (1,0) [0|1] "" Vector__XXX
 SG_ APS_w230_alcUltrasoundBlocked : 37|1@1+ (1,0) [0|1] "" Vector__XXX
 SG_ APS_w231_idfEvent : 38|1@1+ (1,0) [0|1] "" Vector__XXX
 SG_ APS_w232_laneChangeRequested : 39|1@1+ (1,0) [0|1] "" Vector__XXX
 SG_ APS_w235_a72LoopDetected : 42|1@1+ (1,0) [0|1] "" Vector__XXX
 SG_ APS_w236_canSharedMemError : 43|1@1+ (1,0) [0|1] "" Vector__XXX
 SG_ APS_w237_faultMgrEventDetected : 44|1@1+ (1,0) [0|1] "" Vector__XXX
 SG_ APS_w238_resetReason : 45|1@1+ (1,0) [0|1] "" Vector__XXX
 SG_ APS_w241_ddrInitFailures : 48|1@1+ (1,0) [0|1] "" Vector__XXX
 SG_ APS_w242_tripMBISTFailure : 49|1@1+ (1,0) [0|1] "" Vector__XXX
 SG_ APS_w243_tripHWErrorStatus : 50|1@1+ (1,0) [0|1] "" Vector__XXX
 SG_ APS_w244_gpuHWFaultStatus : 51|1@1+ (1,0) [0|1] "" Vector__XXX
 SG_ APS_w245_eloopRxFromUnexpectedSo : 52|1@1+ (1,0) [0|1] "" Vector__XXX
 SG_ APS_w246_ethloopSwitchPortLinkDo : 53|1@1+ (1,0) [0|1] "" Vector__XXX
 SG_ APS_w247_ethernetFrameError : 54|1@1+ (1,0) [0|1] "" Vector__XXX
 SG_ APS_w248_ethloopSwitchPoorSqi : 55|1@1+ (1,0) [0|1] "" Vector__XXX
 SG_ APS_w249_ufsFailures : 56|1@1+ (1,0) [0|1] "" Vector__XXX
 SG_ APS_w250_ethloopSwitchMemUsageTo : 57|1@1+ (1,0) [0|1] "" Vector__XXX
 SG_ APS_w251_ethloopSwitchMemUsageTo : 58|1@1+ (1,0) [0|1] "" Vector__XXX
 SG_ APS_w252_ethSwitchPortLinkDown : 59|1@1+ (1,0) [0|1] "" Vector__XXX
 SG_ APS_w253_powerStateTimeout : 60|1@1+ (1,0) [0|1] "" Vector__XXX
 SG_ APS_w254_sleepStateTimeout : 61|1@1+ (1,0) [0|1] "" Vector__XXX
 SG_ APS_w255_bootHealth : 62|1@1+ (1,0) [0|1] "" Vector__XXX

BO_ 784 APS_warningMatrix4: 8 APS
 SG_ APS_w257_assertFailure : 0|1@1+ (1,0) [0|1] "" Vector__XXX
 SG_ APS_w258_qspiFlashSectorChecksum : 1|1@1+ (1,0) [0|1] "" Vector__XXX
 SG_ APS_w259_qspiFailure : 2|1@1+ (1,0) [0|1] "" Vector__XXX
 SG_ APS_w260_pgoodFailure : 3|1@1+ (1,0) [0|1] "" Vector__XXX
 SG_ APS_w261_vrmFaultGrpA : 4|1@1+ (1,0) [0|1] "" Vector__XXX
 SG_ APS_w262_vrmFaultGrpB : 5|1@1+ (1,0) [0|1] "" Vector__XXX
 SG_ APS_w263_vrmFaultGrpC : 6|1@1+ (1,0) [0|1] "" Vector__XXX
 SG_ APS_w264_ddrPhy0Failures : 7|1@1+ (1,0) [0|1] "" Vector__XXX
 SG_ APS_w265_ddrPhy1Failures : 8|1@1+ (1,0) [0|1] "" Vector__XXX
 SG_ APS_w266_ddrPhy2Failures : 9|1@1+ (1,0) [0|1] "" Vector__XXX
 SG_ APS_w267_ddrPhy3Failures : 10|1@1+ (1,0) [0|1] "" Vector__XXX
 SG_ APS_w268_ddrControllerFailures : 11|1@1+ (1,0) [0|1] "" Vector__XXX
 SG_ APS_w269_ethSwitchRxPageCountToo : 12|1@1+ (1,0) [0|1] "" Vector__XXX
 SG_ APS_w270_ethSwitchRxPageCountToo : 13|1@1+ (1,0) [0|1] "" Vector__XXX
 SG_ APS_w271_ddrScheduler0EccErrors : 14|1@1+ (1,0) [0|1] "" Vector__XXX
 SG_ APS_w272_ddrScheduler1EccErrors : 15|1@1+ (1,0) [0|1] "" Vector__XXX
 SG_ APS_w273_ddrScheduler2EccErrors : 16|1@1+ (1,0) [0|1] "" Vector__XXX
 SG_ APS_w274_ddrScheduler3EccErrors : 17|1@1+ (1,0) [0|1] "" Vector__XXX
 SG_ APS_w275_ddrScheduler4EccErrors : 18|1@1+ (1,0) [0|1] "" Vector__XXX
 SG_ APS_w276_ddrScheduler5EccErrors : 19|1@1+ (1,0) [0|1] "" Vector__XXX
 SG_ APS_w277_ddrScheduler6EccErrors : 20|1@1+ (1,0) [0|1] "" Vector__XXX
 SG_ APS_w278_ddrScheduler7EccErrors : 21|1@1+ (1,0) [0|1] "" Vector__XXX
 SG_ APS_w279_ufsPartitionError : 22|1@1+ (1,0) [0|1] "" Vector__XXX
 SG_ APS_w280_pepsMia : 23|1@1+ (1,0) [0|1] "" Vector__XXX
 SG_ APS_w281_rsaMia : 24|1@1+ (1,0) [0|1] "" Vector__XXX
 SG_ APS_w282_smmuError : 25|1@1+ (1,0) [0|1] "" Vector__XXX
 SG_ APS_w284_cam12VBuckBoostAPwrIssu : 27|1@1+ (1,0) [0|1] "" Vector__XXX
 SG_ APS_w285_cam12VBuckBoostBPwrIssu : 28|1@1+ (1,0) [0|1] "" Vector__XXX
 SG_ APS_w286_cam12VEFuseAPrimaryIssu : 29|1@1+ (1,0) [0|1] "" Vector__XXX
 SG_ APS_w287_cam12VEFuseASecondaryIs : 30|1@1+ (1,0) [0|1] "" Vector__XXX
 SG_ APS_w288_brakeboosterMia : 31|1@1+ (1,0) [0|1] "" Vector__XXX
 SG_ APS_w289_turboTemperatureWarning : 32|1@1+ (1,0) [0|1] "" Vector__XXX
 SG_ APS_w290_cam12VBuckBoostBPwrRing : 33|1@1+ (1,0) [0|1] "" Vector__XXX

BO_TX_BU_ 1481 : APS;
BO_TX_BU_ 637 : APS;
BO_TX_BU_ 1865 : APS;
BO_TX_BU_ 2044 : APS;
BO_TX_BU_ 970 : APS;
BO_TX_BU_ 1510 : APS;
BO_TX_BU_ 811 : APS;
BO_TX_BU_ 876 : APS;
BO_TX_BU_ 1113 : APS;
BO_TX_BU_ 848 : APS;
BO_TX_BU_ 784 : APS;
CM_ BO_ 1481 "Driver assistance computer (secondary) message: alert log";
CM_ SG_ 1481 APS_alertID "Driver assistance computer (secondary): alert ID";
CM_ SG_ 1481 APS_alertSource "Driver assistance computer (secondary): alert source";
CM_ SG_ 1481 APS_alertState "Driver assistance computer (secondary): alert state";
CM_ SG_ 1481 APS_sw010_a04calibNotDone "Driver assistance computer (secondary): sw010 a04calib not done";
CM_ SG_ 1481 APS_sw010_a05calibReqd "Driver assistance computer (secondary): sw010 a05calib reqd";
CM_ SG_ 1481 APS_sw010_a06calibNotOK "Driver assistance computer (secondary): sw010 a06calib not OK";
CM_ SG_ 1481 APS_sw010_a08PlantMode "Driver assistance computer (secondary): sw010 a08 plant mode";
CM_ SG_ 1481 APS_sw010_HorizontalMisalignment "Driver assistance computer (secondary): sw010 horizontal misalignment";
CM_ SG_ 1481 APS_sw010_VerticalMisalignment "Driver assistance computer (secondary): sw010 vertical misalignment";
CM_ SG_ 1481 APS_sw010_unusedBits "Driver assistance computer (secondary): sw010 unused bits";
CM_ SG_ 1481 APS_sw010_VmaPlausibility "Driver assistance computer (secondary): sw010 vma plausibility";
CM_ SG_ 1481 APS_sw019_taskId "Driver assistance computer (secondary): sw019 task id";
CM_ SG_ 1481 APS_sw019_numFreeBytes "Driver assistance computer (secondary): sw019 num free bytes";
CM_ SG_ 1481 APS_sw019_timeStamp "Driver assistance computer (secondary): sw019 time stamp";
CM_ SG_ 1481 APS_sw020_unusedW0 "Driver assistance computer (secondary): sw020 unused W0";
CM_ SG_ 1481 APS_sw020_unusedW1 "Driver assistance computer (secondary): sw020 unused W1";
CM_ SG_ 1481 APS_sw020_unusedW2 "Driver assistance computer (secondary): sw020 unused W2";
CM_ SG_ 1481 APS_sw021_tempSensorId "Driver assistance computer (secondary): sw021 temp sensor id";
CM_ SG_ 1481 APS_sw021_minThreshold "Driver assistance computer (secondary): sw021 min threshold";
CM_ SG_ 1481 APS_sw021_maxThreshold "Driver assistance computer (secondary): sw021 max threshold";
CM_ SG_ 1481 APS_sw021_currentTemperature "Driver assistance computer (secondary): sw021 current temperature";
CM_ SG_ 1481 APS_sw021_unusedWord "Driver assistance computer (secondary): sw021 unused word";
CM_ SG_ 1481 APS_sw024_Task_ID "Driver assistance computer (secondary): sw024 task ID";
CM_ SG_ 1481 APS_sw024_numVirtualLaneVeh "Driver assistance computer (secondary): sw024 num virtual lane veh";
CM_ SG_ 1481 APS_sw024_currentVehicleApp "Driver assistance computer (secondary): sw024 current vehicle app";
CM_ SG_ 1481 APS_sw024_taskProgramCounter "Driver assistance computer (secondary): sw024 task program counter";
CM_ SG_ 1481 APS_sw027_JTAG_Reset "Driver assistance computer (secondary): sw027 JTAG reset";
CM_ SG_ 1481 APS_sw027_Core_Reset "Driver assistance computer (secondary): sw027 core reset";
CM_ SG_ 1481 APS_sw027_Unused_Bit_0 "Driver assistance computer (secondary): sw027 unused bit 0";
CM_ SG_ 1481 APS_sw027_CPU_Checkstop_Error "Driver assistance computer (secondary): sw027 CPU checkstop error";
CM_ SG_ 1481 APS_sw027_PLL_0_Failure "Driver assistance computer (secondary): sw027 PLL 0 failure";
CM_ SG_ 1481 APS_sw027_Clock_Monitor_0_Low "Driver assistance computer (secondary): sw027 clock monitor 0 low";
CM_ SG_ 1481 APS_sw027_Clock_Monitor_0_Off "Driver assistance computer (secondary): sw027 clock monitor 0 off";
CM_ SG_ 1481 APS_sw027_LVD_4v5 "Driver assistance computer (secondary): sw027 LVD 4v5";
CM_ SG_ 1481 APS_sw027_Flash_Fatal_Error "Driver assistance computer (secondary): sw027 flash fatal error";
CM_ SG_ 1481 APS_sw027_PLL_1_Failure "Driver assistance computer (secondary): sw027 PLL 1 failure";
CM_ SG_ 1481 APS_sw027_Unused_Bit_1 "Driver assistance computer (secondary): sw027 unused bit 1";
CM_ SG_ 1481 APS_sw027_f_PLL_1_Off "Driver assistance computer (secondary): sw027 f PLL 1 off";
CM_ SG_ 1481 APS_sw027_Unused_Nibble "Driver assistance computer (secondary): sw027 unused nibble";
CM_ SG_ 1481 APS_sw027_LVD_1v2 "Driver assistance computer (secondary): sw027 LVD 1v2";
CM_ SG_ 1481 APS_sw027_Unused_Bit_2 "Driver assistance computer (secondary): sw027 unused bit 2";
CM_ SG_ 1481 APS_sw027_Watchdog "Driver assistance computer (secondary): sw027 watchdog";
CM_ SG_ 1481 APS_sw027_Unused_Bit_3 "Driver assistance computer (secondary): sw027 unused bit 3";
CM_ SG_ 1481 APS_sw027_LVD_2v7_VREG "Driver assistance computer (secondary): sw027 LVD 2v7 VREG";
CM_ SG_ 1481 APS_sw027_LVD_2v7_Flash "Driver assistance computer (secondary): sw027 LVD 2v7 flash";
CM_ SG_ 1481 APS_sw027_LVD_2v7_IO "Driver assistance computer (secondary): sw027 LVD 2v7 IO";
CM_ SG_ 1481 APS_sw027_Unused_Bit_4 "Driver assistance computer (secondary): sw027 unused bit 4";
CM_ SG_ 1481 APS_sw027_Unused_Byte "Driver assistance computer (secondary): sw027 unused byte";
CM_ SG_ 1481 APS_sw027_ESR0 "Driver assistance computer (secondary): sw027 ESR0";
CM_ SG_ 1481 APS_sw027_ESR1 "Driver assistance computer (secondary): sw027 ESR1";
CM_ SG_ 1481 APS_sw027_SW "Driver assistance computer (secondary): sw027 SW";
CM_ SG_ 1481 APS_sw027_STM0 "Driver assistance computer (secondary): sw027 STM0";
CM_ SG_ 1481 APS_sw027_STM1 "Driver assistance computer (secondary): sw027 STM1";
CM_ SG_ 1481 APS_sw027_STM2 "Driver assistance computer (secondary): sw027 STM2";
CM_ SG_ 1481 APS_sw027_CBS_SYSTEM "Driver assistance computer (secondary): sw027 CBS SYSTEM";
CM_ SG_ 1481 APS_sw027_CBS_DEBUG "Driver assistance computer (secondary): sw027 CBS DEBUG";
CM_ SG_ 1481 APS_sw027_CBS_APP "Driver assistance computer (secondary): sw027 CBS APP";
CM_ SG_ 1481 APS_sw027_EVR13 "Driver assistance computer (secondary): sw027 EVR13";
CM_ SG_ 1481 APS_sw027_EVR33 "Driver assistance computer (secondary): sw027 EVR33";
CM_ SG_ 1481 APS_sw027_SWD "Driver assistance computer (secondary): sw027 SWD";
CM_ SG_ 1481 APS_sw027_STDBY_WDG "Driver assistance computer (secondary): sw027 STDBY WDG";
CM_ SG_ 1481 APS_sw027_PORST "Driver assistance computer (secondary): sw027 PORST";
CM_ SG_ 1481 APS_sw027_Unused_word "Driver assistance computer (secondary): sw027 unused word";
CM_ SG_ 1481 APS_sw030_heaterState "Driver assistance computer (secondary): sw030 heater state";
CM_ SG_ 1481 APS_sw030_unusedByte "Driver assistance computer (secondary): sw030 unused byte";
CM_ SG_ 1481 APS_sw030_unusedW0 "Driver assistance computer (secondary): sw030 unused W0";
CM_ SG_ 1481 APS_sw030_unusedW1 "Driver assistance computer (secondary): sw030 unused W1";
CM_ SG_ 1481 APS_sw031_canBus "Driver assistance computer (secondary): sw031 can bus";
CM_ SG_ 1481 APS_sw031_errorType "Driver assistance computer (secondary): sw031 error type";
CM_ SG_ 1481 APS_sw031_errorData1 "Driver assistance computer (secondary): sw031 error data1";
CM_ SG_ 1481 APS_sw031_errorData2 "Driver assistance computer (secondary): sw031 error data2";
CM_ SG_ 1481 APS_sw032_canBus "Driver assistance computer (secondary): sw032 can bus";
CM_ SG_ 1481 APS_sw032_errorType "Driver assistance computer (secondary): sw032 error type";
CM_ SG_ 1481 APS_sw032_errorData1 "Driver assistance computer (secondary): sw032 error data1";
CM_ SG_ 1481 APS_sw032_errorData2 "Driver assistance computer (secondary): sw032 error data2";
CM_ SG_ 1481 APS_sw033_carConfig "Driver assistance computer (secondary): sw033 car config";
CM_ SG_ 1481 APS_sw033_chNm "Driver assistance computer (secondary): sw033 ch nm";
CM_ SG_ 1481 APS_sw033_vin "Driver assistance computer (secondary): sw033 vin";
CM_ SG_ 1481 APS_sw033_carState "Driver assistance computer (secondary): sw033 car state";
CM_ SG_ 1481 APS_sw034_sccmMia "Driver assistance computer (secondary): sw034 sccm mia";
CM_ SG_ 1481 APS_sw034_unusedByte "Driver assistance computer (secondary): sw034 unused byte";
CM_ SG_ 1481 APS_sw034_unusedW0 "Driver assistance computer (secondary): sw034 unused W0";
CM_ SG_ 1481 APS_sw034_unusedW1 "Driver assistance computer (secondary): sw034 unused W1";
CM_ SG_ 1481 APS_sw035_wheelSpeeds "Driver assistance computer (secondary): sw035 wheel speeds";
CM_ SG_ 1481 APS_sw035_status "Driver assistance computer (secondary): sw035 status";
CM_ SG_ 1481 APS_sw035_wheelRotation "Driver assistance computer (secondary): sw035 wheel rotation";
CM_ SG_ 1481 APS_sw036_bdyMia "Driver assistance computer (secondary): sw036 bdy mia";
CM_ SG_ 1481 APS_sw036_unusedByte "Driver assistance computer (secondary): sw036 unused byte";
CM_ SG_ 1481 APS_sw036_unusedW0 "Driver assistance computer (secondary): sw036 unused W0";
CM_ SG_ 1481 APS_sw036_unusedW1 "Driver assistance computer (secondary): sw036 unused W1";
CM_ SG_ 1481 APS_sw039_sdm_rcm_Mia "Driver assistance computer (secondary): sw039 sdm rcm mia";
CM_ SG_ 1481 APS_sw039_unusedByte "Driver assistance computer (secondary): sw039 unused byte";
CM_ SG_ 1481 APS_sw039_unusedW0 "Driver assistance computer (secondary): sw039 unused W0";
CM_ SG_ 1481 APS_sw039_unusedW1 "Driver assistance computer (secondary): sw039 unused W1";
CM_ SG_ 1481 APS_sw045_radMia "Driver assistance computer (secondary): sw045 rad mia";
CM_ SG_ 1481 APS_sw045_unusedByte "Driver assistance computer (secondary): sw045 unused byte";
CM_ SG_ 1481 APS_sw045_unusedW0 "Driver assistance computer (secondary): sw045 unused W0";
CM_ SG_ 1481 APS_sw045_unusedW1 "Driver assistance computer (secondary): sw045 unused W1";
CM_ SG_ 1481 APS_sw048_swAssert "Driver assistance computer (secondary): sw048 sw assert";
CM_ SG_ 1481 APS_sw048_thermalIssue "Driver assistance computer (secondary): sw048 thermal issue";
CM_ SG_ 1481 APS_sw048_powerIssue "Driver assistance computer (secondary): sw048 power issue";
CM_ SG_ 1481 APS_sw048_stackOverflow "Driver assistance computer (secondary): sw048 stack overflow";
CM_ SG_ 1481 APS_sw048_checkStop "Driver assistance computer (secondary): sw048 check stop";
CM_ SG_ 1481 APS_sw048_ecuWatchdog "Driver assistance computer (secondary): sw048 ecu watchdog";
CM_ SG_ 1481 APS_sw048_ecuReset "Driver assistance computer (secondary): sw048 ecu reset";
CM_ SG_ 1481 APS_sw048_radcVersionMismatch "Driver assistance computer (secondary): sw048 radc version mismatch";
CM_ SG_ 1481 APS_sw048_radcCalibration "Driver assistance computer (secondary): sw048 radc calibration";
CM_ SG_ 1481 APS_sw048_radcMia "Driver assistance computer (secondary): sw048 radc mia";
CM_ SG_ 1481 APS_sw048_eyeQVersionMismatch "Driver assistance computer (secondary): sw048 eye q version mismatch";
CM_ SG_ 1481 APS_sw048_camIssue "Driver assistance computer (secondary): sw048 cam issue";
CM_ SG_ 1481 APS_sw048_parkerIssue "Driver assistance computer (secondary): sw048 parker issue";
CM_ SG_ 1481 APS_sw048_prolongedUiMia "Driver assistance computer (secondary): sw048 prolonged ui mia";
CM_ SG_ 1481 APS_sw048_uiMiaAtBootup "Driver assistance computer (secondary): sw048 ui mia at bootup";
CM_ SG_ 1481 APS_sw051_a01ecuInternalPerf "Driver assistance computer (secondary): sw051 a01ecu internal perf";
CM_ SG_ 1481 APS_sw051_a02flashPerformance "Driver assistance computer (secondary): sw051 a02flash performance";
CM_ SG_ 1481 APS_sw051_a03vBatHigh "Driver assistance computer (secondary): sw051 a03v bat high";
CM_ SG_ 1481 APS_sw051_a09configMismatch "Driver assistance computer (secondary): sw051 a09config mismatch";
CM_ SG_ 1481 APS_sw051_a52radomeHtrInop "Driver assistance computer (secondary): sw051 a52radome htr inop";
CM_ SG_ 1481 APS_sw051_unused "Driver assistance computer (secondary): sw051 unused";
CM_ SG_ 1481 APS_sw051_SCUTemperature "Driver assistance computer (secondary): sw051 SCU temperature";
CM_ SG_ 1481 APS_sw051_HWFail "Driver assistance computer (secondary): sw051 HW fail";
CM_ SG_ 1481 APS_sw051_SGUFail "Driver assistance computer (secondary): sw051 SGU fail";
CM_ SG_ 1481 APS_sw051_unusedBits "Driver assistance computer (secondary): sw051 unused bits";
CM_ SG_ 1481 APS_sw051_unusedB0 "Driver assistance computer (secondary): sw051 unused B0";
CM_ SG_ 1481 APS_sw051_unusedW1 "Driver assistance computer (secondary): sw051 unused W1";
CM_ SG_ 1481 APS_sw052_a07sensorBlinded "Driver assistance computer (secondary): sw052 a07sensor blinded";
CM_ SG_ 1481 APS_sw052_sensorDirty "Driver assistance computer (secondary): sw052 sensor dirty";
CM_ SG_ 1481 APS_sw052_HWFail "Driver assistance computer (secondary): sw052 HW fail";
CM_ SG_ 1481 APS_sw052_overTemperature "Driver assistance computer (secondary): sw052 over temperature";
CM_ SG_ 1481 APS_sw052_underTemperature "Driver assistance computer (secondary): sw052 under temperature";
CM_ SG_ 1481 APS_sw052_chirpError "Driver assistance computer (secondary): sw052 chirp error";
CM_ SG_ 1481 APS_sw052_rspError "Driver assistance computer (secondary): sw052 rsp error";
CM_ SG_ 1481 APS_sw052_sensorBlocked "Driver assistance computer (secondary): sw052 sensor blocked";
CM_ SG_ 1481 APS_sw053_a10canBusOff "Driver assistance computer (secondary): sw053 a10can bus off";
CM_ SG_ 1481 APS_sw053_a11bdyMIA "Driver assistance computer (secondary): sw053 a11bdy MIA";
CM_ SG_ 1481 APS_sw053_a12espMIA "Driver assistance computer (secondary): sw053 a12esp MIA";
CM_ SG_ 1481 APS_sw053_a13gtwMIA "Driver assistance computer (secondary): sw053 a13gtw MIA";
CM_ SG_ 1481 APS_sw053_a14sccmMIA "Driver assistance computer (secondary): sw053 a14sccm MIA";
CM_ SG_ 1481 APS_sw053_a15adasMIA "Driver assistance computer (secondary): sw053 a15adas MIA";
CM_ SG_ 1481 APS_sw053_a16bdyInvalidCount "Driver assistance computer (secondary): sw053 a16bdy invalid count";
CM_ SG_ 1481 APS_sw053_a17adasInvalidCount "Driver assistance computer (secondary): sw053 a17adas invalid count";
CM_ SG_ 1481 APS_sw053_a18espInvalidCount "Driver assistance computer (secondary): sw053 a18esp invalid count";
CM_ SG_ 1481 APS_sw053_a19sccmInvalidCount "Driver assistance computer (secondary): sw053 a19sccm invalid count";
CM_ SG_ 1481 APS_sw053_a20bdyInvalidChkSm "Driver assistance computer (secondary): sw053 a20bdy invalid chk sm";
CM_ SG_ 1481 APS_sw053_a21espInvalidChkSm "Driver assistance computer (secondary): sw053 a21esp invalid chk sm";
CM_ SG_ 1481 APS_sw053_a22sccmInvalidChkSm "Driver assistance computer (secondary): sw053 a22sccm invalid chk sm";
CM_ SG_ 1481 APS_sw053_a23sccmInvalidChkSm "Driver assistance computer (secondary): sw053 a23sccm invalid chk sm";
CM_ SG_ 1481 APS_sw053_a24absValidity "Driver assistance computer (secondary): sw053 a24abs validity";
CM_ SG_ 1481 APS_sw053_a25ambTValidity "Driver assistance computer (secondary): sw053 a25amb t validity";
CM_ SG_ 1481 APS_sw053_a26brakeValidity "Driver assistance computer (secondary): sw053 a26brake validity";
CM_ SG_ 1481 APS_sw053_a27CntryCdValidity "Driver assistance computer (secondary): sw053 a27 cntry cd validity";
CM_ SG_ 1481 APS_sw053_a28espValidity "Driver assistance computer (secondary): sw053 a28esp validity";
CM_ SG_ 1481 APS_sw053_a29longAccOffValidity "Driver assistance computer (secondary): sw053 a29long acc off validity";
CM_ SG_ 1481 APS_sw053_a30longAccValidity "Driver assistance computer (secondary): sw053 a30long acc validity";
CM_ SG_ 1481 APS_sw053_a31odoValidity "Driver assistance computer (secondary): sw053 a31odo validity";
CM_ SG_ 1481 APS_sw053_a32gearValidity "Driver assistance computer (secondary): sw053 a32gear validity";
CM_ SG_ 1481 APS_sw053_a33steerAngValidity "Driver assistance computer (secondary): sw053 a33steer ang validity";
CM_ SG_ 1481 APS_sw053_a34steerAngSpdValidity "Driver assistance computer (secondary): sw053 a34steer ang spd validity";
CM_ SG_ 1481 APS_sw053_a35indctrValidity "Driver assistance computer (secondary): sw053 a35indctr validity";
CM_ SG_ 1481 APS_sw053_a36vehStndStllValidty "Driver assistance computer (secondary): sw053 a36veh stnd stll validty";
CM_ SG_ 1481 APS_sw053_a37vinValidity "Driver assistance computer (secondary): sw053 a37vin validity";
CM_ SG_ 1481 APS_sw053_a38whlRotValidity "Driver assistance computer (secondary): sw053 a38whl rot validity";
CM_ SG_ 1481 APS_sw053_a39whlSpdValidity "Driver assistance computer (secondary): sw053 a39whl spd validity";
CM_ SG_ 1481 APS_sw053_a40whlStndStllValidty "Driver assistance computer (secondary): sw053 a40whl stnd stll validty";
CM_ SG_ 1481 APS_sw053_a41wiperValidity "Driver assistance computer (secondary): sw053 a41wiper validity";
CM_ SG_ 1481 APS_sw053_a42xwdValidity "Driver assistance computer (secondary): sw053 a42xwd validity";
CM_ SG_ 1481 APS_sw053_a43yawOffValidity "Driver assistance computer (secondary): sw053 a43yaw off validity";
CM_ SG_ 1481 APS_sw053_a44yawValidity "Driver assistance computer (secondary): sw053 a44yaw validity";
CM_ SG_ 1481 APS_sw053_a48steerAngOffSanity "Driver assistance computer (secondary): sw053 a48steer ang off sanity";
CM_ SG_ 1481 APS_sw053_a49tireSizeSanity "Driver assistance computer (secondary): sw053 a49tire size sanity";
CM_ SG_ 1481 APS_sw053_a50velocitySanity "Driver assistance computer (secondary): sw053 a50velocity sanity";
CM_ SG_ 1481 APS_sw053_a51yawSanity "Driver assistance computer (secondary): sw053 a51yaw sanity";
CM_ SG_ 1481 APS_sw053_a53espmodValidity "Driver assistance computer (secondary): sw053 a53espmod validity";
CM_ SG_ 1481 APS_sw053_a54gtwmodValidity "Driver assistance computer (secondary): sw053 a54gtwmod validity";
CM_ SG_ 1481 APS_sw053_a55stwmodValidity "Driver assistance computer (secondary): sw053 a55stwmod validity";
CM_ SG_ 1481 APS_sw053_a56bcmodValidity "Driver assistance computer (secondary): sw053 a56bcmod validity";
CM_ SG_ 1481 APS_sw053_a57dimodValidity "Driver assistance computer (secondary): sw053 a57dimod validity";
CM_ SG_ 1481 APS_sw053_a59drmiInvalidChkSm "Driver assistance computer (secondary): sw053 a59drmi invalid chk sm";
CM_ SG_ 1481 APS_sw053_a60drmiInvalidCount "Driver assistance computer (secondary): sw053 a60drmi invalid count";
CM_ SG_ 1481 APS_sw053_a61radPositionMismatch "Driver assistance computer (secondary): sw053 a61rad position mismatch";
CM_ SG_ 1481 APS_sw053_a62strRackMismatch "Driver assistance computer (secondary): sw053 a62str rack mismatch";
CM_ SG_ 1481 APS_sw055_detectedRadcVersion "Driver assistance computer (secondary): sw055 detected radc version";
CM_ SG_ 1481 APS_sw055_expectedCrcLsw "Driver assistance computer (secondary): sw055 expected crc lsw";
CM_ SG_ 1481 APS_sw056_diMia "Driver assistance computer (secondary): sw056 di mia";
CM_ SG_ 1481 APS_sw056_unusedByte "Driver assistance computer (secondary): sw056 unused byte";
CM_ SG_ 1481 APS_sw056_unusedW0 "Driver assistance computer (secondary): sw056 unused W0";
CM_ SG_ 1481 APS_sw056_unusedW1 "Driver assistance computer (secondary): sw056 unused W1";
CM_ SG_ 1481 APS_sw058_epbMia "Driver assistance computer (secondary): sw058 epb mia";
CM_ SG_ 1481 APS_sw058_unusedByte "Driver assistance computer (secondary): sw058 unused byte";
CM_ SG_ 1481 APS_sw058_unusedW0 "Driver assistance computer (secondary): sw058 unused W0";
CM_ SG_ 1481 APS_sw058_unusedW1 "Driver assistance computer (secondary): sw058 unused W1";
CM_ SG_ 1481 APS_sw059_sdiFront "Driver assistance computer (secondary): sw059 sdi front";
CM_ SG_ 1481 APS_sw059_sdiRear "Driver assistance computer (secondary): sw059 sdi rear";
CM_ SG_ 1481 APS_sw059_status "Driver assistance computer (secondary): sw059 status";
CM_ SG_ 1481 APS_sw059_sensorStatusFront "Driver assistance computer (secondary): sw059 sensor status front";
CM_ SG_ 1481 APS_sw059_pasFrontMiddle "Driver assistance computer (secondary): sw059 pas front middle";
CM_ SG_ 1481 APS_sw059_sensorStatusRear "Driver assistance computer (secondary): sw059 sensor status rear";
CM_ SG_ 1481 APS_sw059_pasRearMiddle "Driver assistance computer (secondary): sw059 pas rear middle";
CM_ SG_ 1481 APS_sw059_pscStatus "Driver assistance computer (secondary): sw059 psc status";
CM_ SG_ 1481 APS_sw059_pscVehSlot "Driver assistance computer (secondary): sw059 psc veh slot";
CM_ SG_ 1481 APS_sw059_status2 "Driver assistance computer (secondary): sw059 status2";
CM_ SG_ 1481 APS_sw059_oloDict "Driver assistance computer (secondary): sw059 olo dict";
CM_ SG_ 1481 APS_sw059_oocStatus "Driver assistance computer (secondary): sw059 ooc status";
CM_ SG_ 1481 APS_sw061_states "Driver assistance computer (secondary): sw061 states";
CM_ SG_ 1481 APS_sw063_expectedMajorVer "Driver assistance computer (secondary): sw063 expected major ver";
CM_ SG_ 1481 APS_sw063_detectedMajorVer "Driver assistance computer (secondary): sw063 detected major ver";
CM_ SG_ 1481 APS_sw063_expectedMinorVer "Driver assistance computer (secondary): sw063 expected minor ver";
CM_ SG_ 1481 APS_sw063_detectedMinorVer "Driver assistance computer (secondary): sw063 detected minor ver";
CM_ SG_ 1481 APS_sw063_expectedSubMinorVer "Driver assistance computer (secondary): sw063 expected sub minor ver";
CM_ SG_ 1481 APS_sw063_detectedSubMinorVer "Driver assistance computer (secondary): sw063 detected sub minor ver";
CM_ SG_ 1481 APS_sw064_sysStatus "Driver assistance computer (secondary): sw064 sys status";
CM_ SG_ 1481 APS_sw064_status "Driver assistance computer (secondary): sw064 status";
CM_ SG_ 1481 APS_sw070_currTireFitment "Driver assistance computer (secondary): sw070 curr tire fitment";
CM_ SG_ 1481 APS_sw070_lastTireFitment "Driver assistance computer (secondary): sw070 last tire fitment";
CM_ SG_ 1481 APS_sw070_diGear "Driver assistance computer (secondary): sw070 di gear";
CM_ SG_ 1481 APS_sw070_driveRail "Driver assistance computer (secondary): sw070 drive rail";
CM_ SG_ 1481 APS_sw070_accRail "Driver assistance computer (secondary): sw070 acc rail";
CM_ SG_ 1481 APS_sw070_temperature "Driver assistance computer (secondary): sw070 temperature";
CM_ SG_ 1481 APS_sw070_currentSpeed "Driver assistance computer (secondary): sw070 current speed";
CM_ SG_ 1481 APS_sw071_selfParkType "Driver assistance computer (secondary): sw071 self park type";
CM_ SG_ 1481 APS_sw071_endPosX "Driver assistance computer (secondary): sw071 end pos x";
CM_ SG_ 1481 APS_sw071_endPosY "Driver assistance computer (secondary): sw071 end pos y";
CM_ SG_ 1481 APS_sw071_roadClass "Driver assistance computer (secondary): sw071 road class";
CM_ SG_ 1481 APS_sw071_driverPresent "Driver assistance computer (secondary): sw071 driver present";
CM_ SG_ 1481 APS_sw071_airSuspension "Driver assistance computer (secondary): sw071 air suspension";
CM_ SG_ 1481 APS_sw071_temperature "Driver assistance computer (secondary): sw071 temperature";
CM_ SG_ 1481 APS_sw071_activationType "Driver assistance computer (secondary): sw071 activation type";
CM_ SG_ 1481 APS_sw072_vehicleX "Driver assistance computer (secondary): sw072 vehicle x";
CM_ SG_ 1481 APS_sw072_vehicleY "Driver assistance computer (secondary): sw072 vehicle y";
CM_ SG_ 1481 APS_sw072_vehicleHeading "Driver assistance computer (secondary): sw072 vehicle heading";
CM_ SG_ 1481 APS_sw072_endDistance "Driver assistance computer (secondary): sw072 end distance";
CM_ SG_ 1481 APS_sw072_guidanceComplete "Driver assistance computer (secondary): sw072 guidance complete";
CM_ SG_ 1481 APS_sw072_guidanceRunaway "Driver assistance computer (secondary): sw072 guidance runaway";
CM_ SG_ 1481 APS_sw072_guidanceTimer "Driver assistance computer (secondary): sw072 guidance timer";
CM_ SG_ 1481 APS_sw072_handlePress "Driver assistance computer (secondary): sw072 handle press";
CM_ SG_ 1481 APS_sw072_keyfobPress "Driver assistance computer (secondary): sw072 keyfob press";
CM_ SG_ 1481 APS_sw072_garageOpened "Driver assistance computer (secondary): sw072 garage opened";
CM_ SG_ 1481 APS_sw072_userTimeout "Driver assistance computer (secondary): sw072 user timeout";
CM_ SG_ 1481 APS_sw075_scMia "Driver assistance computer (secondary): sw075 sc mia";
CM_ SG_ 1481 APS_sw075_unusedByte "Driver assistance computer (secondary): sw075 unused byte";
CM_ SG_ 1481 APS_sw075_unusedW0 "Driver assistance computer (secondary): sw075 unused W0";
CM_ SG_ 1481 APS_sw075_unusedW1 "Driver assistance computer (secondary): sw075 unused W1";
CM_ SG_ 1481 APS_sw077_oocDistance "Driver assistance computer (secondary): sw077 ooc distance";
CM_ SG_ 1481 APS_sw077_oocConfidence "Driver assistance computer (secondary): sw077 ooc confidence";
CM_ SG_ 1481 APS_sw077_oocCollisionSide "Driver assistance computer (secondary): sw077 ooc collision side";
CM_ SG_ 1481 APS_sw077_oocHeight "Driver assistance computer (secondary): sw077 ooc height";
CM_ SG_ 1481 APS_sw077_vehicleSpeed "Driver assistance computer (secondary): sw077 vehicle speed";
CM_ SG_ 1481 APS_sw077_oocUntrackedTime "Driver assistance computer (secondary): sw077 ooc untracked time";
CM_ SG_ 1481 APS_sw077_oocOffCourseDist_cm "Driver assistance computer (secondary): sw077 ooc off course dist cm";
CM_ SG_ 1481 APS_sw081_radarDistance "Driver assistance computer (secondary): sw081 radar distance";
CM_ SG_ 1481 APS_sw081_radarTTC "Driver assistance computer (secondary): sw081 radar TTC";
CM_ SG_ 1481 APS_sw081_cameraDistance "Driver assistance computer (secondary): sw081 camera distance";
CM_ SG_ 1481 APS_sw081_cameraTTC "Driver assistance computer (secondary): sw081 camera TTC";
CM_ SG_ 1481 APS_sw081_pedalPosition "Driver assistance computer (secondary): sw081 pedal position";
CM_ SG_ 1481 APS_sw129_currentVoltage "Driver assistance computer (secondary): sw129 current voltage";
CM_ SG_ 1481 APS_sw129_maxThreshold "Driver assistance computer (secondary): sw129 max threshold";
CM_ SG_ 1481 APS_sw129_minThreshold "Driver assistance computer (secondary): sw129 min threshold";
CM_ SG_ 1481 APS_sw129_powerSequnceError "Driver assistance computer (secondary): sw129 power sequnce error";
CM_ SG_ 1481 APS_sw129_railControl "Driver assistance computer (secondary): sw129 rail control";
CM_ SG_ 1481 APS_sw129_railID "Driver assistance computer (secondary): sw129 rail ID";
CM_ SG_ 1481 APS_sw130_currentTemperature "Driver assistance computer (secondary): sw130 current temperature";
CM_ SG_ 1481 APS_sw130_maxThreshold "Driver assistance computer (secondary): sw130 max threshold";
CM_ SG_ 1481 APS_sw130_minThreshold "Driver assistance computer (secondary): sw130 min threshold";
CM_ SG_ 1481 APS_sw130_tempSensorId "Driver assistance computer (secondary): sw130 temp sensor id";
CM_ SG_ 1481 APS_sw130_shouldForceApPowerOn "Driver assistance computer (secondary): sw130 should force ap power on";
CM_ SG_ 1481 APS_sw130_shouldBlockOkToPowerAp "Driver assistance computer (secondary): sw130 should block ok to power ap";
CM_ SG_ 1481 APS_sw132_mismatchType "Driver assistance computer (secondary): sw132 mismatch type";
CM_ SG_ 1481 APS_sw132_actualHash "Driver assistance computer (secondary): sw132 actual hash";
CM_ SG_ 1481 APS_sw132_expectedHash "Driver assistance computer (secondary): sw132 expected hash";
CM_ SG_ 1481 APS_sw133_failedInitStep "Driver assistance computer (secondary): sw133 failed init step";
CM_ SG_ 1481 APS_sw133_switchInReset "Driver assistance computer (secondary): sw133 switch in reset";
CM_ SG_ 1481 APS_sw133_phyIsNotRMIIMode "Driver assistance computer (secondary): sw133 phy is not RMII mode";
CM_ SG_ 1481 APS_sw133_phyInterruptStorm "Driver assistance computer (secondary): sw133 phy interrupt storm";
CM_ SG_ 1481 APS_sw133_switchEthernetInterLin "Driver assistance computer (secondary): sw133 switch ethernet inter link down";
CM_ SG_ 1481 APS_sw133_ethSwitchReadFwVerFail "Driver assistance computer (secondary): sw133 eth switch read fw ver failed";
CM_ SG_ 1481 APS_sw133_ethSwitchFailedToBoot "Driver assistance computer (secondary): sw133 eth switch failed to boot";
CM_ SG_ 1481 APS_sw133_ethSwitchTimedoutUpdat "Driver assistance computer (secondary): sw133 eth switch timedout update";
CM_ SG_ 1481 APS_sw133_unused "Driver assistance computer (secondary): sw133 unused";
CM_ SG_ 1481 APS_sw134_appCamCalibStatus "Driver assistance computer (secondary): sw134 app cam calib status";
CM_ SG_ 1481 APS_sw134_appCameraLux "Driver assistance computer (secondary): sw134 app camera lux";
CM_ SG_ 1481 APS_sw134_appInfo "Driver assistance computer (secondary): sw134 app info";
CM_ SG_ 1481 APS_sw134_appStatus "Driver assistance computer (secondary): sw134 app status";
CM_ SG_ 1481 APS_sw134_dasBodyControlsVEH "Driver assistance computer (secondary): sw134 das body controls VEH";
CM_ SG_ 1481 APS_sw134_dasControl "Driver assistance computer (secondary): sw134 das control";
CM_ SG_ 1481 APS_sw134_dasControlPty "Driver assistance computer (secondary): sw134 das control pty";
CM_ SG_ 1481 APS_sw134_dasIntSafetyFrontPty "Driver assistance computer (secondary): sw134 das int safety front pty";
CM_ SG_ 1481 APS_sw134_dasLanes "Driver assistance computer (secondary): sw134 das lanes";
CM_ SG_ 1481 APS_sw134_dasObject "Driver assistance computer (secondary): sw134 das object";
CM_ SG_ 1481 APS_sw134_dasPscControl "Driver assistance computer (secondary): sw134 das psc control";
CM_ SG_ 1481 APS_sw134_dasStatus "Driver assistance computer (secondary): sw134 das status";
CM_ SG_ 1481 APS_sw134_dasStatus2 "Driver assistance computer (secondary): sw134 das status2";
CM_ SG_ 1481 APS_sw134_dasSteeringControl "Driver assistance computer (secondary): sw134 das steering control";
CM_ SG_ 1481 APS_sw134_dasVisualDebug "Driver assistance computer (secondary): sw134 das visual debug";
CM_ SG_ 1481 APS_sw134_dasSteeringControlPty "Driver assistance computer (secondary): sw134 das steering control pty";
CM_ SG_ 1481 APS_sw134_dasChNm "Driver assistance computer (secondary): sw134 das ch nm";
CM_ SG_ 1481 APS_sw134_appSummon "Driver assistance computer (secondary): sw134 app summon";
CM_ SG_ 1481 APS_sw134_appEnvironment "Driver assistance computer (secondary): sw134 app environment";
CM_ SG_ 1481 APS_sw134_dasStatusPty "Driver assistance computer (secondary): sw134 das status pty";
CM_ SG_ 1481 APS_sw134_dasStatus2Pty "Driver assistance computer (secondary): sw134 das status2 pty";
CM_ SG_ 1481 APS_sw134_dasMatrixHighBeamRqVEH "Driver assistance computer (secondary): sw134 das matrix high beam rq VEH";
CM_ SG_ 1481 APS_sw134_dasMatrixBendAngleRqPt "Driver assistance computer (secondary): sw134 das matrix bend angle rq pty";
CM_ SG_ 1481 APS_sw134_dasBodyControls2VEH "Driver assistance computer (secondary): sw134 das body controls2 VEH";
CM_ SG_ 1481 APS_sw134_timeSinceLastMsg "Driver assistance computer (secondary): sw134 time since last msg";
CM_ SG_ 1481 APS_sw135_appCriticalReason "Driver assistance computer (secondary): sw135 app critical reason";
CM_ SG_ 1481 APS_sw135_appTimesyncStatus "Driver assistance computer (secondary): sw135 app timesync status";
CM_ SG_ 1481 APS_sw136_gpsCommIrrecoverable "Driver assistance computer (secondary): sw136 gps comm irrecoverable";
CM_ SG_ 1481 APS_sw136_fusionIrrecoverable "Driver assistance computer (secondary): sw136 fusion irrecoverable";
CM_ SG_ 1481 APS_sw136_antennaUnplugged "Driver assistance computer (secondary): sw136 antenna unplugged";
CM_ SG_ 1481 APS_sw136_badgpsfix "Driver assistance computer (secondary): sw136 badgpsfix";
CM_ SG_ 1481 APS_sw137_gpsCommMissing "Driver assistance computer (secondary): sw137 gps comm missing";
CM_ SG_ 1481 APS_sw137_gpsJunkData "Driver assistance computer (secondary): sw137 gps junk data";
CM_ SG_ 1481 APS_sw137_gpsNMEAmissing "Driver assistance computer (secondary): sw137 gps NME amissing";
CM_ SG_ 1481 APS_sw137_gpsUBXmissing "Driver assistance computer (secondary): sw137 gps UB xmissing";
CM_ SG_ 1481 APS_sw137_fusionModeDisabled "Driver assistance computer (secondary): sw137 fusion mode disabled";
CM_ SG_ 1481 APS_sw137_gpsCfgFail "Driver assistance computer (secondary): sw137 gps cfg fail";
CM_ SG_ 1481 APS_sw137_esfStatusMsgMIA "Driver assistance computer (secondary): sw137 esf status msg MIA";
CM_ SG_ 1481 APS_sw137_wheelTickCfgMissmatch "Driver assistance computer (secondary): sw137 wheel tick cfg missmatch";
CM_ SG_ 1481 APS_sw137_exitTransportMode "Driver assistance computer (secondary): sw137 exit transport mode";
CM_ SG_ 1481 APS_sw137_satRejectionTimeout "Driver assistance computer (secondary): sw137 sat rejection timeout";
CM_ SG_ 1481 APS_sw137_gpsPPSMissing "Driver assistance computer (secondary): sw137 gps PPS missing";
CM_ SG_ 1481 APS_sw138_cfgBufNull "Driver assistance computer (secondary): sw138 cfg buf null";
CM_ SG_ 1481 APS_sw138_invalidID "Driver assistance computer (secondary): sw138 invalid ID";
CM_ SG_ 1481 APS_sw138_gpsBufferOverflow "Driver assistance computer (secondary): sw138 gps buffer overflow";
CM_ SG_ 1481 APS_sw138_navx5CfgFailed "Driver assistance computer (secondary): sw138 navx5 cfg failed";
CM_ SG_ 1481 APS_sw138_mcuNMEAmsgUDPinvalid "Driver assistance computer (secondary): sw138 mcu NME amsg UD pinvalid";
CM_ SG_ 1481 APS_sw138_mcuDbgMsgInvalid "Driver assistance computer (secondary): sw138 mcu dbg msg invalid";
CM_ SG_ 1481 APS_sw138_mcuDbgMsgTooBig "Driver assistance computer (secondary): sw138 mcu dbg msg too big";
CM_ SG_ 1481 APS_sw138_mcuFwdNMEAfail "Driver assistance computer (secondary): sw138 mcu fwd NME afail";
CM_ SG_ 1481 APS_sw138_NMEAinvalidChecksum "Driver assistance computer (secondary): sw138 NME ainvalid checksum";
CM_ SG_ 1481 APS_sw138_unexpectedNMEAmsg "Driver assistance computer (secondary): sw138 unexpected NME amsg";
CM_ SG_ 1481 APS_sw138_UARTbusFull "Driver assistance computer (secondary): sw138 UAR tbus full";
CM_ SG_ 1481 APS_sw138_UARTframeError "Driver assistance computer (secondary): sw138 UAR tframe error";
CM_ SG_ 1481 APS_sw138_UBXrxFrameTooBig "Driver assistance computer (secondary): sw138 UB xrx frame too big";
CM_ SG_ 1481 APS_sw138_emptyValidNMEA "Driver assistance computer (secondary): sw138 empty valid NMEA";
CM_ SG_ 1481 APS_sw138_invalidAsciiNMEA "Driver assistance computer (secondary): sw138 invalid ascii NMEA";
CM_ SG_ 1481 APS_sw138_wheeltickUARTfault "Driver assistance computer (secondary): sw138 wheeltick UAR tfault";
CM_ SG_ 1481 APS_sw138_baudrateMismatch "Driver assistance computer (secondary): sw138 baudrate mismatch";
CM_ SG_ 1481 APS_sw138_wheelTickInvalidSrc "Driver assistance computer (secondary): sw138 wheel tick invalid src";
CM_ SG_ 1481 APS_sw138_UARTparityError "Driver assistance computer (secondary): sw138 UAR tparity error";
CM_ SG_ 1481 APS_sw138_UARTrxFifoOverflow "Driver assistance computer (secondary): sw138 UAR trx fifo overflow";
CM_ SG_ 1481 APS_sw138_UARTrxFifoUnderflow "Driver assistance computer (secondary): sw138 UAR trx fifo underflow";
CM_ SG_ 1481 APS_sw138_UARTtxFifoOverflow "Driver assistance computer (secondary): sw138 UAR ttx fifo overflow";
CM_ SG_ 1481 APS_sw138_esfWtMsgTimeout "Driver assistance computer (secondary): sw138 esf wt msg timeout";
CM_ SG_ 1481 APS_sw138_PFLASHReadError "Driver assistance computer (secondary): sw138 PFLASH read error";
CM_ SG_ 1481 APS_sw138_PFLASHWriteError "Driver assistance computer (secondary): sw138 PFLASH write error";
CM_ SG_ 1481 APS_sw138_gpsCfgNack "Driver assistance computer (secondary): sw138 gps cfg nack";
CM_ SG_ 1481 APS_sw138_gpsCfgIdFail "Driver assistance computer (secondary): sw138 gps cfg id fail";
CM_ SG_ 1481 APS_sw138_gpsSetCfgNoAck "Driver assistance computer (secondary): sw138 gps set cfg no ack";
CM_ SG_ 1481 APS_sw138_gpsReadCfgNoResponse "Driver assistance computer (secondary): sw138 gps read cfg no response";
CM_ SG_ 1481 APS_sw138_ubxErrorReported "Driver assistance computer (secondary): sw138 ubx error reported";
CM_ SG_ 1481 APS_sw140_lvPowerState "Driver assistance computer (secondary): sw140 lv power state";
CM_ SG_ 1481 APS_sw140_vehicleStatus "Driver assistance computer (secondary): sw140 vehicle status";
CM_ SG_ 1481 APS_sw140_status "Driver assistance computer (secondary): sw140 status";
CM_ SG_ 1481 APS_sw140_lighting "Driver assistance computer (secondary): sw140 lighting";
CM_ SG_ 1481 APS_sw140_sensors "Driver assistance computer (secondary): sw140 sensors";
CM_ SG_ 1481 APS_sw140_coolant "Driver assistance computer (secondary): sw140 coolant";
CM_ SG_ 1481 APS_sw140_okToUseHighPower "Driver assistance computer (secondary): sw140 ok to use high power";
CM_ SG_ 1481 APS_sw141_inertial1 "Driver assistance computer (secondary): sw141 inertial1";
CM_ SG_ 1481 APS_sw141_inertial2 "Driver assistance computer (secondary): sw141 inertial2";
CM_ SG_ 1481 APS_sw142_speed "Driver assistance computer (secondary): sw142 speed";
CM_ SG_ 1481 APS_sw142_locStatus "Driver assistance computer (secondary): sw142 loc status";
CM_ SG_ 1481 APS_sw142_locStatus2 "Driver assistance computer (secondary): sw142 loc status2";
CM_ SG_ 1481 APS_sw142_systemStatus "Driver assistance computer (secondary): sw142 system status";
CM_ SG_ 1481 APS_sw142_chassisControl "Driver assistance computer (secondary): sw142 chassis control";
CM_ SG_ 1481 APS_sw143_status "Driver assistance computer (secondary): sw143 status";
CM_ SG_ 1481 APS_sw143_wheelRotation "Driver assistance computer (secondary): sw143 wheel rotation";
CM_ SG_ 1481 APS_sw143_wheelSpeeds "Driver assistance computer (secondary): sw143 wheel speeds";
CM_ SG_ 1481 APS_sw144_restraintStatus "Driver assistance computer (secondary): sw144 restraint status";
CM_ SG_ 1481 APS_sw145_restraintStatus "Driver assistance computer (secondary): sw145 restraint status";
CM_ SG_ 1481 APS_sw146_sysStatus "Driver assistance computer (secondary): sw146 sys status";
CM_ SG_ 1481 APS_sw146_status "Driver assistance computer (secondary): sw146 status";
CM_ SG_ 1481 APS_sw147_doorStatus "Driver assistance computer (secondary): sw147 door status";
CM_ SG_ 1481 APS_sw147_switchStatus "Driver assistance computer (secondary): sw147 switch status";
CM_ SG_ 1481 APS_sw148_doorStatus "Driver assistance computer (secondary): sw148 door status";
CM_ SG_ 1481 APS_sw148_hvacStatus "Driver assistance computer (secondary): sw148 hvac status";
CM_ SG_ 1481 APS_sw149_status "Driver assistance computer (secondary): sw149 status";
CM_ SG_ 1481 APS_sw150_steeringAngleSensor "Driver assistance computer (secondary): sw150 steering angle sensor";
CM_ SG_ 1481 APS_sw150_rightStalk "Driver assistance computer (secondary): sw150 right stalk";
CM_ SG_ 1481 APS_sw150_leftStalk "Driver assistance computer (secondary): sw150 left stalk";
CM_ SG_ 1481 APS_sw151_apGpioState "Driver assistance computer (secondary): sw151 ap gpio state";
CM_ SG_ 1481 APS_sw151_apWatchDogState "Driver assistance computer (secondary): sw151 ap watch dog state; raw 7 = signal not available (SNA)";
CM_ SG_ 1481 APS_sw151_diGear "Driver assistance computer (secondary): sw151 di gear; raw 7 = signal not available (SNA)";
CM_ SG_ 1481 APS_sw151_recoveryPathway "Driver assistance computer (secondary): sw151 recovery pathway";
CM_ SG_ 1481 APS_sw151_parkerType "Driver assistance computer (secondary): sw151 parker type";
CM_ SG_ 1481 APS_sw153_eacInhibitReason "Driver assistance computer (secondary): sw153 eac inhibit reason";
CM_ SG_ 1481 APS_sw153_eacInternalState "Driver assistance computer (secondary): sw153 eac internal state";
CM_ SG_ 1481 APS_sw155_InUnicastError "Driver assistance computer (secondary): sw155 in unicast error";
CM_ SG_ 1481 APS_sw155_UDPRecvError "Driver assistance computer (secondary): sw155 UDP recv error";
CM_ SG_ 1481 APS_sw155_UDPMiscError "Driver assistance computer (secondary): sw155 UDP misc error";
CM_ SG_ 1481 APS_sw155_UDPRTEError "Driver assistance computer (secondary): sw155 UDPRTE error";
CM_ SG_ 1481 APS_sw155_UDPCheckError "Driver assistance computer (secondary): sw155 UDP check error";
CM_ SG_ 1481 APS_sw155_UDPDropError "Driver assistance computer (secondary): sw155 UDP drop error";
CM_ SG_ 1481 APS_sw155_UDPMemError "Driver assistance computer (secondary): sw155 UDP mem error";
CM_ SG_ 1481 APS_sw155_UDPProtoError "Driver assistance computer (secondary): sw155 UDP proto error";
CM_ SG_ 1481 APS_sw155_IPRecvError "Driver assistance computer (secondary): sw155 IP recv error";
CM_ SG_ 1481 APS_sw155_IPMiscError "Driver assistance computer (secondary): sw155 IP misc error";
CM_ SG_ 1481 APS_sw155_IPRTEError "Driver assistance computer (secondary): sw155 IPRTE error";
CM_ SG_ 1481 APS_sw155_IPCheckError "Driver assistance computer (secondary): sw155 IP check error";
CM_ SG_ 1481 APS_sw155_IPMemError "Driver assistance computer (secondary): sw155 IP mem error";
CM_ SG_ 1481 APS_sw155_IPDropError "Driver assistance computer (secondary): sw155 IP drop error";
CM_ SG_ 1481 APS_sw155_IPProtoError "Driver assistance computer (secondary): sw155 IP proto error";
CM_ SG_ 1481 APS_sw158_apbInfo "Driver assistance computer (secondary): sw158 apb info";
CM_ SG_ 1481 APS_sw158_apbStatus "Driver assistance computer (secondary): sw158 apb status";
CM_ SG_ 1481 APS_sw158_dasBodyControlsVEH "Driver assistance computer (secondary): sw158 das body controls VEH";
CM_ SG_ 1481 APS_sw158_dasControl "Driver assistance computer (secondary): sw158 das control";
CM_ SG_ 1481 APS_sw158_dasControlPty "Driver assistance computer (secondary): sw158 das control pty";
CM_ SG_ 1481 APS_sw158_dasIntSafetyFrontPty "Driver assistance computer (secondary): sw158 das int safety front pty";
CM_ SG_ 1481 APS_sw158_dasLanes "Driver assistance computer (secondary): sw158 das lanes";
CM_ SG_ 1481 APS_sw158_dasObject "Driver assistance computer (secondary): sw158 das object";
CM_ SG_ 1481 APS_sw158_dasPscControl "Driver assistance computer (secondary): sw158 das psc control";
CM_ SG_ 1481 APS_sw158_dasStatus "Driver assistance computer (secondary): sw158 das status";
CM_ SG_ 1481 APS_sw158_dasStatus2 "Driver assistance computer (secondary): sw158 das status2";
CM_ SG_ 1481 APS_sw158_dasSteeringControl "Driver assistance computer (secondary): sw158 das steering control";
CM_ SG_ 1481 APS_sw158_dasVisualDebug "Driver assistance computer (secondary): sw158 das visual debug";
CM_ SG_ 1481 APS_sw158_dasSteeringControlPty "Driver assistance computer (secondary): sw158 das steering control pty";
CM_ SG_ 1481 APS_sw158_dasChNm "Driver assistance computer (secondary): sw158 das ch nm";
CM_ SG_ 1481 APS_sw158_dasStatusPty "Driver assistance computer (secondary): sw158 das status pty";
CM_ SG_ 1481 APS_sw158_dasStatus2Pty "Driver assistance computer (secondary): sw158 das status2 pty";
CM_ SG_ 1481 APS_sw158_dasMatrixHighBeamRqVEH "Driver assistance computer (secondary): sw158 das matrix high beam rq VEH";
CM_ SG_ 1481 APS_sw158_dasMatrixBendAngleRqPt "Driver assistance computer (secondary): sw158 das matrix bend angle rq pty";
CM_ SG_ 1481 APS_sw158_dasBodyControls2VEH "Driver assistance computer (secondary): sw158 das body controls2 VEH";
CM_ SG_ 1481 APS_sw158_timeSinceLastMsg "Driver assistance computer (secondary): sw158 time since last msg";
CM_ SG_ 1481 APS_sw159_apbCriticalReason "Driver assistance computer (secondary): sw159 apb critical reason";
CM_ SG_ 1481 APS_sw159_apbTimesyncStatus "Driver assistance computer (secondary): sw159 apb timesync status";
CM_ SG_ 1481 APS_sw160_mismatchType "Driver assistance computer (secondary): sw160 mismatch type";
CM_ SG_ 1481 APS_sw160_actualHash "Driver assistance computer (secondary): sw160 actual hash";
CM_ SG_ 1481 APS_sw160_expectedHash "Driver assistance computer (secondary): sw160 expected hash";
CM_ SG_ 1481 APS_sw161_antennaDisconnected "Driver assistance computer (secondary): sw161 antenna disconnected";
CM_ SG_ 1481 APS_sw172_prolongedUiMia "Driver assistance computer (secondary): sw172 prolonged ui mia";
CM_ SG_ 1481 APS_sw172_uiMiaAtBootup "Driver assistance computer (secondary): sw172 ui mia at bootup";
CM_ SG_ 1481 APS_sw188_otherTurbo "Driver assistance computer (secondary): sw188 other turbo";
CM_ SG_ 1481 APS_sw188_arbUartMiaState "Driver assistance computer (secondary): sw188 arb uart mia state";
CM_ SG_ 1481 APS_sw188_powerUartMiaState "Driver assistance computer (secondary): sw188 power uart mia state";
CM_ SG_ 1481 APS_sw188_faultsUartMiaState "Driver assistance computer (secondary): sw188 faults uart mia state";
CM_ SG_ 1481 APS_sw188_sleepUartMiaState "Driver assistance computer (secondary): sw188 sleep uart mia state";
CM_ SG_ 1481 APS_sw188_resetUartMiaState "Driver assistance computer (secondary): sw188 reset uart mia state";
CM_ SG_ 1481 APS_sw188_statMonUartMiaState "Driver assistance computer (secondary): sw188 stat mon uart mia state";
CM_ SG_ 1481 APS_sw188_wdogStateUartMiaState "Driver assistance computer (secondary): sw188 wdog state uart mia state";
CM_ SG_ 1481 APS_sw188_critReasUartMiaState "Driver assistance computer (secondary): sw188 crit reas uart mia state";
CM_ SG_ 1481 APS_sw189_AP_vehicleState10Hz "Driver assistance computer (secondary): sw189 AP vehicle state10 hz";
CM_ SG_ 1481 APS_sw189_AP_vehicleState1Hz "Driver assistance computer (secondary): sw189 AP vehicle state1 hz";
CM_ SG_ 1481 APS_sw190_IBST_status "Driver assistance computer (secondary): sw190 IBST status";
CM_ SG_ 1481 APS_sw192_CANbus "Driver assistance computer (secondary): sw192 CA nbus";
CM_ SG_ 1481 APS_sw192_SWTxQueueFull "Driver assistance computer (secondary): sw192 SW tx queue full";
CM_ SG_ 1481 APS_sw192_Busoff "Driver assistance computer (secondary): sw192 busoff";
CM_ SG_ 1481 APS_sw192_UncorrectedBitError "Driver assistance computer (secondary): sw192 uncorrected bit error";
CM_ SG_ 1481 APS_sw192_CorrectedBitError "Driver assistance computer (secondary): sw192 corrected bit error";
CM_ SG_ 1481 APS_sw192_ErrorPassive "Driver assistance computer (secondary): sw192 error passive";
CM_ SG_ 1481 APS_sw192_RamAccessFailed "Driver assistance computer (secondary): sw192 ram access failed";
CM_ SG_ 1481 APS_sw192_RxMsgLost "Driver assistance computer (secondary): sw192 rx msg lost";
CM_ SG_ 1481 APS_sw192_msgIo "Driver assistance computer (secondary): sw192 msg io";
CM_ SG_ 1481 APS_sw192_queueFailure "Driver assistance computer (secondary): sw192 queue failure";
CM_ SG_ 1481 APS_sw192_msgId "Driver assistance computer (secondary): sw192 msg id";
CM_ SG_ 1481 APS_sw199_abortCodeDas "Driver assistance computer (secondary): sw199 abort code das";
CM_ SG_ 1481 APS_sw199_abortCodePARK "Driver assistance computer (secondary): sw199 abort code PARK; raw 31 = signal not available (SNA)";
CM_ SG_ 1481 APS_sw199_currentSTW "Driver assistance computer (secondary): sw199 current STW";
CM_ SG_ 1481 APS_sw199_currentSpeed "Driver assistance computer (secondary): sw199 current speed";
CM_ SG_ 1481 APS_sw199_internalState "Driver assistance computer (secondary): sw199 internal state";
CM_ SG_ 1481 APS_sw199_maxSpeed "Driver assistance computer (secondary): sw199 max speed";
CM_ SG_ 1481 APS_sw199_numShifts "Driver assistance computer (secondary): sw199 num shifts";
CM_ SG_ 1481 APS_sw203_controlType "Driver assistance computer (secondary): sw203 control type; raw 15 = signal not available (SNA)";
CM_ SG_ 1481 APS_sw203_curbType "Driver assistance computer (secondary): sw203 curb type";
CM_ SG_ 1481 APS_sw203_roadClass "Driver assistance computer (secondary): sw203 road class";
CM_ SG_ 1481 APS_sw203_slotSizeX "Driver assistance computer (secondary): sw203 slot size x";
CM_ SG_ 1481 APS_sw203_slotSizeY "Driver assistance computer (secondary): sw203 slot size y";
CM_ SG_ 1481 APS_sw203_startDistance "Driver assistance computer (secondary): sw203 start distance";
CM_ SG_ 1481 APS_sw203_vehicleSkew "Driver assistance computer (secondary): sw203 vehicle skew";
CM_ SG_ 1481 APS_sw204_frLeft "Driver assistance computer (secondary): sw204 fr left";
CM_ SG_ 1481 APS_sw204_frLeftMiddle "Driver assistance computer (secondary): sw204 fr left middle";
CM_ SG_ 1481 APS_sw204_frMiddle "Driver assistance computer (secondary): sw204 fr middle";
CM_ SG_ 1481 APS_sw204_frRight "Driver assistance computer (secondary): sw204 fr right";
CM_ SG_ 1481 APS_sw204_frRightMiddle "Driver assistance computer (secondary): sw204 fr right middle";
CM_ SG_ 1481 APS_sw204_maxSpeed "Driver assistance computer (secondary): sw204 max speed";
CM_ SG_ 1481 APS_sw205_oocDistance "Driver assistance computer (secondary): sw205 ooc distance";
CM_ SG_ 1481 APS_sw205_rrLeft "Driver assistance computer (secondary): sw205 rr left";
CM_ SG_ 1481 APS_sw205_rrLeftMiddle "Driver assistance computer (secondary): sw205 rr left middle";
CM_ SG_ 1481 APS_sw205_rrMiddle "Driver assistance computer (secondary): sw205 rr middle";
CM_ SG_ 1481 APS_sw205_rrRight "Driver assistance computer (secondary): sw205 rr right";
CM_ SG_ 1481 APS_sw205_rrRightMiddle "Driver assistance computer (secondary): sw205 rr right middle";
CM_ SG_ 1481 APS_sw235_resetOrigin "Driver assistance computer (secondary): sw235 reset origin";
CM_ SG_ 1481 APS_sw235_generalUnrecoverable "Driver assistance computer (secondary): sw235 general unrecoverable";
CM_ SG_ 1481 APS_sw235_pgoodUnrecoverable "Driver assistance computer (secondary): sw235 pgood unrecoverable";
CM_ SG_ 1481 APS_sw235_faultUnrecoverable "Driver assistance computer (secondary): sw235 fault unrecoverable";
CM_ SG_ 1481 APS_sw235_12VFuseUnrecoverable "Driver assistance computer (secondary): sw235 12 v fuse unrecoverable";
CM_ SG_ 1481 APS_sw235_pgoodLevelUnrcvrble "Driver assistance computer (secondary): sw235 pgood level unrcvrble";
CM_ SG_ 1481 APS_sw235_faultLevelUnrcvrble "Driver assistance computer (secondary): sw235 fault level unrcvrble";
CM_ SG_ 1481 APS_sw235_12VFuseLvlUnrcvrble "Driver assistance computer (secondary): sw235 12 v fuse lvl unrcvrble";
CM_ SG_ 1481 APS_sw235_localSoftwareFault "Driver assistance computer (secondary): sw235 local software fault";
CM_ SG_ 1481 APS_sw235_unrecoverableFailReset "Driver assistance computer (secondary): sw235 unrecoverable fail reset";
CM_ SG_ 1481 APS_sw235_generalGic "Driver assistance computer (secondary): sw235 general gic";
CM_ SG_ 1481 APS_sw235_a72WdtTimeout "Driver assistance computer (secondary): sw235 a72 wdt timeout";
CM_ SG_ 1481 APS_sw235_generalScs "Driver assistance computer (secondary): sw235 general scs";
CM_ SG_ 1481 APS_sw235_generalUnexpected "Driver assistance computer (secondary): sw235 general unexpected";
CM_ SG_ 1481 APS_sw235_canUncorrectedBitError "Driver assistance computer (secondary): sw235 can uncorrected bit error";
CM_ SG_ 1481 APS_sw235_canExitBusoffFailed "Driver assistance computer (secondary): sw235 can exit busoff failed";
CM_ SG_ 1481 APS_sw235_txEnFdbckNotExpected "Driver assistance computer (secondary): sw235 tx en fdbck not expected";
CM_ SG_ 1481 APS_sw235_nocSmsFailed "Driver assistance computer (secondary): sw235 noc sms failed";
CM_ SG_ 1481 APS_sw235_nocCamFailed "Driver assistance computer (secondary): sw235 noc cam failed";
CM_ SG_ 1481 APS_sw235_nocCoreFailed "Driver assistance computer (secondary): sw235 noc core failed";
CM_ SG_ 1481 APS_sw235_nocScsFailed "Driver assistance computer (secondary): sw235 noc scs failed";
CM_ SG_ 1481 APS_sw235_model3UiReset "Driver assistance computer (secondary): sw235 model3 ui reset";
CM_ SG_ 1481 APS_sw235_modelsUiReset "Driver assistance computer (secondary): sw235 models ui reset";
CM_ SG_ 1481 APS_sw235_pmicApOnPrpUnrcvrble "Driver assistance computer (secondary): sw235 pmic ap on prp unrcvrble";
CM_ SG_ 1481 APS_sw235_apOnReadyTimeout "Driver assistance computer (secondary): sw235 ap on ready timeout";
CM_ SG_ 1481 APS_sw235_pmicApOnWaitUnrcvrble "Driver assistance computer (secondary): sw235 pmic ap on wait unrcvrble";
CM_ SG_ 1481 APS_sw235_apBootingTimeout "Driver assistance computer (secondary): sw235 ap booting timeout";
CM_ SG_ 1481 APS_sw235_pmicApOffWaitUnrcvrble "Driver assistance computer (secondary): sw235 pmic ap off wait unrcvrble";
CM_ SG_ 1481 APS_sw235_resetBeingSent "Driver assistance computer (secondary): sw235 reset being sent";
CM_ SG_ 1481 APS_sw235_udsResetBeingSent "Driver assistance computer (secondary): sw235 uds reset being sent";
CM_ SG_ 1481 APS_sw235_smsWdtTimeout "Driver assistance computer (secondary): sw235 sms wdt timeout";
CM_ SG_ 1481 APS_sw235_smsCanApHealthTimeout "Driver assistance computer (secondary): sw235 sms can ap health timeout";
CM_ SG_ 1481 APS_sw235_smsTaskWdtTimeout "Driver assistance computer (secondary): sw235 sms task wdt timeout";
CM_ SG_ 1481 APS_sw236_fifoSizeInvalid "Driver assistance computer (secondary): sw236 fifo size invalid";
CM_ SG_ 1481 APS_sw236_nocRemapInvalid "Driver assistance computer (secondary): sw236 noc remap invalid";
CM_ SG_ 1481 APS_sw236_txFifoInvalid "Driver assistance computer (secondary): sw236 tx fifo invalid";
CM_ SG_ 1481 APS_sw236_rxFifoInvalid "Driver assistance computer (secondary): sw236 rx fifo invalid";
CM_ SG_ 1481 APS_sw237_faultSource "Driver assistance computer (secondary): sw237 fault source";
CM_ SG_ 1481 APS_sw237_peerSoCFaulted "Driver assistance computer (secondary): sw237 peer so c faulted";
CM_ SG_ 1481 APS_sw242_instance "Driver assistance computer (secondary): sw242 instance";
CM_ SG_ 1481 APS_sw242_clusterSRAMMBISTFailed "Driver assistance computer (secondary): sw242 cluster SRAMMBIST failed";
CM_ SG_ 1481 APS_sw242_SRAMBankMBISTFailed "Driver assistance computer (secondary): sw242 SRAM bank MBIST failed";
CM_ SG_ 1481 APS_sw243_instance "Driver assistance computer (secondary): sw243 instance";
CM_ SG_ 1481 APS_sw243_errorStatus "Driver assistance computer (secondary): sw243 error status";
CM_ SG_ 1481 APS_sw243_extendedErrorStatus "Driver assistance computer (secondary): sw243 extended error status";
CM_ SG_ 1481 APS_sw244_instance "Driver assistance computer (secondary): sw244 instance";
CM_ SG_ 1481 APS_sw244_exceptionCode "Driver assistance computer (secondary): sw244 exception code";
CM_ SG_ 1481 APS_sw245_unknownMACAddrByte0 "Driver assistance computer (secondary): sw245 unknown MAC addr byte0";
CM_ SG_ 1481 APS_sw245_unknownMACAddrByte1 "Driver assistance computer (secondary): sw245 unknown MAC addr byte1";
CM_ SG_ 1481 APS_sw245_unknownMACAddrByte2 "Driver assistance computer (secondary): sw245 unknown MAC addr byte2";
CM_ SG_ 1481 APS_sw245_unknownMACAddrByte3 "Driver assistance computer (secondary): sw245 unknown MAC addr byte3";
CM_ SG_ 1481 APS_sw245_unknownMACAddrByte4 "Driver assistance computer (secondary): sw245 unknown MAC addr byte4";
CM_ SG_ 1481 APS_sw245_unknownMACAddrByte5 "Driver assistance computer (secondary): sw245 unknown MAC addr byte5";
CM_ SG_ 1481 APS_sw246_ethloopSwitchPort0 "Driver assistance computer (secondary): sw246 ethloop switch port0";
CM_ SG_ 1481 APS_sw246_ethloopSwitchPort1 "Driver assistance computer (secondary): sw246 ethloop switch port1";
CM_ SG_ 1481 APS_sw246_ethloopSwitchPort2 "Driver assistance computer (secondary): sw246 ethloop switch port2";
CM_ SG_ 1481 APS_sw246_ethloopSwitchPort3 "Driver assistance computer (secondary): sw246 ethloop switch port3";
CM_ SG_ 1481 APS_sw246_ethloopSwitchPort4 "Driver assistance computer (secondary): sw246 ethloop switch port4";
CM_ SG_ 1481 APS_sw246_ethloopSwitchPort5 "Driver assistance computer (secondary): sw246 ethloop switch port5";
CM_ SG_ 1481 APS_sw246_ethloopSwitchPort6 "Driver assistance computer (secondary): sw246 ethloop switch port6";
CM_ SG_ 1481 APS_sw246_ethloopSwitchPort7 "Driver assistance computer (secondary): sw246 ethloop switch port7";
CM_ SG_ 1481 APS_sw247_crcError "Driver assistance computer (secondary): sw247 crc error";
CM_ SG_ 1481 APS_sw247_dribbleError "Driver assistance computer (secondary): sw247 dribble error";
CM_ SG_ 1481 APS_sw247_receiveError "Driver assistance computer (secondary): sw247 receive error";
CM_ SG_ 1481 APS_sw247_wdogTimeout "Driver assistance computer (secondary): sw247 wdog timeout";
CM_ SG_ 1481 APS_sw247_overflowError "Driver assistance computer (secondary): sw247 overflow error";
CM_ SG_ 1481 APS_sw247_giantPacket "Driver assistance computer (secondary): sw247 giant packet";
CM_ SG_ 1481 APS_sw247_destAddrFilterFail "Driver assistance computer (secondary): sw247 dest addr filter fail";
CM_ SG_ 1481 APS_sw247_saAddressFilterFail "Driver assistance computer (secondary): sw247 sa address filter fail";
CM_ SG_ 1481 APS_sw248_ethloopSwitchPort2Sqi "Driver assistance computer (secondary): sw248 ethloop switch port2 sqi";
CM_ SG_ 1481 APS_sw248_ethloopSwitchPort3Sqi "Driver assistance computer (secondary): sw248 ethloop switch port3 sqi";
CM_ SG_ 1481 APS_sw249_ufsInitFailureReason "Driver assistance computer (secondary): sw249 ufs init failure reason";
CM_ SG_ 1481 APS_sw252_ethSwitchPort2 "Driver assistance computer (secondary): sw252 eth switch port2";
CM_ SG_ 1481 APS_sw253_apWaitForShutdownTimeo "Driver assistance computer (secondary): sw253 ap wait for shutdown timeout";
CM_ SG_ 1481 APS_sw253_apOffPrepareTimeout "Driver assistance computer (secondary): sw253 ap off prepare timeout";
CM_ SG_ 1481 APS_sw253_apSuspendedTimeout "Driver assistance computer (secondary): sw253 ap suspended timeout";
CM_ SG_ 1481 APS_sw253_socOffReadyTimeout "Driver assistance computer (secondary): sw253 soc off ready timeout";
CM_ SG_ 1481 APS_sw253_apInLinuxTimeout "Driver assistance computer (secondary): sw253 ap in linux timeout";
CM_ SG_ 1481 APS_sw253_apInCorebootTimeout "Driver assistance computer (secondary): sw253 ap in coreboot timeout";
CM_ SG_ 1481 APS_sw253_apBootingTimeout "Driver assistance computer (secondary): sw253 ap booting timeout";
CM_ SG_ 1481 APS_sw253_apOnTimeout "Driver assistance computer (secondary): sw253 ap on timeout";
CM_ SG_ 1481 APS_sw254_waitForBusSilenceTimeo "Driver assistance computer (secondary): sw254 wait for bus silence timeout";
CM_ SG_ 1481 APS_sw254_sleepReadyTimeout "Driver assistance computer (secondary): sw254 sleep ready timeout";
CM_ SG_ 1481 APS_sw254_sleepingTimeout "Driver assistance computer (secondary): sw254 sleeping timeout";
CM_ SG_ 1481 APS_sw255_unknownBootError "Driver assistance computer (secondary): sw255 unknown boot error";
CM_ SG_ 1481 APS_sw255_adcWrapperInitBootErro "Driver assistance computer (secondary): sw255 adc wrapper init boot error";
CM_ SG_ 1481 APS_sw255_boardRevisionInitBootE "Driver assistance computer (secondary): sw255 board revision init boot error";
CM_ SG_ 1481 APS_sw255_i2cInitBootError "Driver assistance computer (secondary): sw255 i2c init boot error";
CM_ SG_ 1481 APS_sw255_provisionInitBootError "Driver assistance computer (secondary): sw255 provision init boot error";
CM_ SG_ 1481 APS_sw255_rtcInitBootError "Driver assistance computer (secondary): sw255 rtc init boot error";
CM_ SG_ 1481 APS_sw255_vrmInitConfigBootError "Driver assistance computer (secondary): sw255 vrm init config boot error";
CM_ SG_ 1481 APS_sw255_powerAonIoBootError "Driver assistance computer (secondary): sw255 power aon io boot error";
CM_ SG_ 1481 APS_sw255_bl1TocInitBootError "Driver assistance computer (secondary): sw255 bl1 toc init boot error";
CM_ SG_ 1481 APS_sw255_tmuInitBootError "Driver assistance computer (secondary): sw255 tmu init boot error";
CM_ SG_ 1481 APS_sw255_udpInitBootError "Driver assistance computer (secondary): sw255 udp init boot error";
CM_ SG_ 1481 APS_sw255_gpsInitBootError "Driver assistance computer (secondary): sw255 gps init boot error";
CM_ SG_ 1481 APS_sw255_canInitBootError "Driver assistance computer (secondary): sw255 can init boot error";
CM_ SG_ 1481 APS_sw255_dfuCheckinSubsystemBoo "Driver assistance computer (secondary): sw255 dfu checkin subsystem boot error";
CM_ SG_ 1481 APS_sw255_sectorProtectionBootEr "Driver assistance computer (secondary): sw255 sector protection boot error";
CM_ SG_ 1481 APS_sw255_flashOpBootError "Driver assistance computer (secondary): sw255 flash op boot error";
CM_ SG_ 1481 APS_sw280_pepsStatus "Driver assistance computer (secondary): sw280 peps status";
CM_ SG_ 1481 APS_sw281_rearSteerStatus "Driver assistance computer (secondary): sw281 rear steer status";
CM_ SG_ 1481 APS_sw288_status "Driver assistance computer (secondary): sw288 status";
CM_ SG_ 1481 APS_sw289_turboTemperature "Driver assistance computer (secondary): sw289 turbo temperature; raw 128 = signal not available (SNA)";
CM_ SG_ 1481 APS_sw289_turboProbe "Driver assistance computer (secondary): sw289 turbo probe";
CM_ SG_ 1481 APS_sw289_peer_turboTemperature "Driver assistance computer (secondary): sw289 peer turbo temperature; raw 128 = signal not available (SNA)";
CM_ SG_ 1481 APS_sw289_peer_turboProbe "Driver assistance computer (secondary): sw289 peer turbo probe";
CM_ BO_ 637 "Driver assistance computer (secondary) message: eac monitor";
CM_ SG_ 637 APS_eacAllow "Indicates whether or not the Aurix external angle control (EAC) monitor logic currently allows angle control for Autopilot functions; raw 3 = signal not available (SNA)";
CM_ SG_ 637 APS_eacMonitorCounter "Driver assistance computer (secondary): eac monitor counter";
CM_ SG_ 637 APS_eacMonitorChecksum "Driver assistance computer (secondary): eac monitor checksum";
CM_ BO_ 1865 "Driver assistance computer (secondary) message: power state inputs";
CM_ SG_ 1865 APS_A_lowPowerRequest "Indicates Autopilot Secondary Processor (APS) low power state request presence.";
CM_ SG_ 1865 APS_A_lowPowerRequestor "Indicates who initiated the Autopilot Secondary Processor (APS) low power request.";
CM_ SG_ 1865 APS_A_forcePowerOffRequest "Driver assistance computer (secondary): a force power off request";
CM_ SG_ 1865 APS_B_lowPowerRequest "Indicates Autopilot Secondary Processor (APS) low power state request presence.";
CM_ SG_ 1865 APS_B_lowPowerRequestor "Indicates who initiated the Autopilot Secondary Processor (APS) low power request.";
CM_ SG_ 1865 APS_B_forcePowerOffRequest "Driver assistance computer (secondary): b force power off request";
CM_ BO_ 2044 "Driver assistance computer (secondary) message: state";
CM_ SG_ 2044 APS_primaryTurbo "Which of the two Turbos currently holds the primary role.";
CM_ SG_ 2044 APS_A_arbState "The state of the arbitration state machine of Turbo A.";
CM_ SG_ 2044 APS_A_powerState "The state of the power state machine of Turbo A.";
CM_ SG_ 2044 APS_A_sleepState "The state of the sleep state machine of Turbo A.";
CM_ SG_ 2044 APS_A_resetState "The state of the reset state machine of Turbo A.";
CM_ SG_ 2044 APS_A_faultState "The state of the fault state machine of Turbo A.";
CM_ SG_ 2044 APS_secondaryTurbo "Which of the two Turbos currently holds the secondary role.";
CM_ SG_ 2044 APS_B_arbState "The state of the arbitration state machine of Turbo B.";
CM_ SG_ 2044 APS_B_powerState "The state of the power state machine of Turbo B.";
CM_ SG_ 2044 APS_B_sleepState "The state of the sleep state machine of Turbo B.";
CM_ SG_ 2044 APS_B_resetState "The state of the reset state machine of Turbo B.";
CM_ SG_ 2044 APS_B_faultState "The state of the fault state machine of Turbo B.";
CM_ SG_ 2044 APS_autosteerMonitorState "Driver assistance computer (secondary): autosteer monitor state";
CM_ SG_ 2044 APS_stateCounter "Driver assistance computer (secondary): state counter";
CM_ BO_ 970 "Driver assistance computer (secondary) message: status";
CM_ SG_ 970 APS_appStatusMonitorState "The current status of APE, indicates the health of the stack on the APE";
CM_ SG_ 970 APS_vehBehaviorState "Driver assistance computer (secondary): veh behavior state";
CM_ SG_ 970 APS_canMaster "Indicates which of the autopilot computers is currently controlling outgoing CAN traffic; raw 3 = signal not available (SNA)";
CM_ SG_ 970 APS_appGpioState "The GPIO state of APEA, indicates the health of the primary Parker (HW2 and HW2.5)";
CM_ SG_ 970 APS_eacInternalState "Indicates the internal state of the external angle control monitor running on Aurix.";
CM_ SG_ 970 APS_switchState "Driver assistance computer (secondary): switch state";
CM_ SG_ 970 APS_apbStatusMonitorState "The current status of APEB, indicates the health of the stack on the APEB";
CM_ SG_ 970 APS_apbGpioState "The GPIO state of APEB, indicates the health of the secondary Parker (HW2.5 only)";
CM_ SG_ 970 APS_statusCounter "Driver assistance computer (secondary): status counter";
CM_ SG_ 970 APS_locLimitReason "Indicates why longitudinal control limits are currently not relaxed";
CM_ SG_ 970 APS_appPowerStateRequest "Indicates ap primary power state request";
CM_ SG_ 970 APS_appPowerStateReason "Indicates ap primary power state reason";
CM_ SG_ 970 APS_apbPowerStateRequest "Indicates ap backup power state request";
CM_ SG_ 970 APS_apbPowerStateReason "Indicates ap backup power state reason";
CM_ SG_ 970 APS_heaterStateDebug "Driver assistance computer (secondary): heater state debug; raw 7 = signal not available (SNA)";
CM_ SG_ 970 APS_autosummonCounter "Driver assistance computer (secondary): autosummon counter";
CM_ SG_ 970 APS_autosummonAlert "Driver assistance computer (secondary): autosummon alert";
CM_ SG_ 970 APS_gpsAntennaState "Driver assistance computer (secondary): gps antenna state";
CM_ SG_ 970 APS_arbState "Reports the state of the arbitration state machine of this System on Chip (SoC).";
CM_ SG_ 970 APS_socPowerOperatingMode "Reports the total number of System on Chips (SoCs) that are powered on to provide support for active Autopilot features.";
CM_ SG_ 970 APS_otherArbState "Reports the state of the arbitration state machine of the other System on Chip (SoC). Lets the current SoC know the state of the other SoC to achieve safer operations.";
CM_ BO_ 1510 "Driver assistance computer (secondary) message: sys health";
CM_ SG_ 1510 APS_A_cam12v0Voltage "Measures the 12V camera power supply voltage for Autopilot Secondary Processor (APS) Turbo A; raw 4095 = signal not available (SNA)";
CM_ SG_ 1510 APS_B_cam12v0Voltage "Measures the 12V camera power supply voltage for Autopilot Secondary Processor (APS) Turbo B; raw 4095 = signal not available (SNA)";
CM_ SG_ 1510 APS_A_turboMaxTemperature "Reports the maximum temperature recorded by Autopilot Secondary Processor (APS) unit A; raw 128 = signal not available (SNA)";
CM_ SG_ 1510 APS_A_turboProbeType "Driver assistance computer (secondary): a turbo probe type; raw 63 = signal not available (SNA)";
CM_ SG_ 1510 APS_B_turboMaxTemperature "Reports the maximum temperature recorded by Autopilot Secondary Processor (APS) unit B; raw 128 = signal not available (SNA)";
CM_ SG_ 1510 APS_B_turboProbeType "Driver assistance computer (secondary): b turbo probe type; raw 63 = signal not available (SNA)";
CM_ BO_ 811 "Driver assistance computer (secondary) message: warning matrix0";
CM_ SG_ 811 APS_w001_DEPRECATED "Driver assistance computer (secondary): w001 DEPRECATED";
CM_ SG_ 811 APS_w002_ldwDisabled "Driver assistance computer (secondary): w002 ldw disabled";
CM_ SG_ 811 APS_w003_isaDisabled "Driver assistance computer (secondary): w003 isa disabled";
CM_ SG_ 811 APS_w004_accDisabled "Driver assistance computer (secondary): w004 acc disabled";
CM_ SG_ 811 APS_w005_fcwCancelled "Driver assistance computer (secondary): w005 fcw cancelled";
CM_ SG_ 811 APS_w006_aebCancelled "Driver assistance computer (secondary): w006 aeb cancelled";
CM_ SG_ 811 APS_w007_ahlbDisabled "Driver assistance computer (secondary): w007 ahlb disabled";
CM_ SG_ 811 APS_w008_parkDisabled "Driver assistance computer (secondary): w008 park disabled";
CM_ SG_ 811 APS_w009_aebFault "Driver assistance computer (secondary): w009 aeb fault";
CM_ SG_ 811 APS_w010_radcCalibIssue "Driver assistance computer (secondary): w010 radc calib issue";
CM_ SG_ 811 APS_w011_scaEvent "Driver assistance computer (secondary): w011 sca event";
CM_ SG_ 811 APS_w012_Cam_BootFailure "Driver assistance computer (secondary): w012 cam boot failure";
CM_ SG_ 811 APS_w013_Cam_Watchdog "Driver assistance computer (secondary): w013 cam watchdog";
CM_ SG_ 811 APS_w014_swAssert "Driver assistance computer (secondary): w014 sw assert";
CM_ SG_ 811 APS_w015_Camera_Failsafes "Driver assistance computer (secondary): w015 camera failsafes";
CM_ SG_ 811 APS_w016_aeb_e_event "Driver assistance computer (secondary): w016 aeb e event";
CM_ SG_ 811 APS_w017_Cam_Msg_MIA "Driver assistance computer (secondary): w017 cam msg MIA";
CM_ SG_ 811 APS_w018_ECU_Power_Issue "Driver assistance computer (secondary): w018 ECU power issue";
CM_ SG_ 811 APS_w019_ECU_Stack_Overflow "Driver assistance computer (secondary): w019 ECU stack overflow";
CM_ SG_ 811 APS_w020_ECU_checkstopError "Driver assistance computer (secondary): w020 ECU checkstop error";
CM_ SG_ 811 APS_w021_ECU_Temperature_Issue "Driver assistance computer (secondary): w021 ECU temperature issue";
CM_ SG_ 811 APS_w022_ECU_EEPROM_Failure "Driver assistance computer (secondary): w022 ECU EEPROM failure";
CM_ SG_ 811 APS_w023_ECU_Cam_Statemismatc "Driver assistance computer (secondary): w023 ECU cam statemismatc";
CM_ SG_ 811 APS_w024_ECU_Watchdog_Reset "Driver assistance computer (secondary): w024 ECU watchdog reset";
CM_ SG_ 811 APS_w025_LC_Steering_Override "Driver assistance computer (secondary): w025 LC steering override";
CM_ SG_ 811 APS_w026_ECU_timingIssue "Driver assistance computer (secondary): w026 ECU timing issue";
CM_ SG_ 811 APS_w027_ECU_Reset_Fault "Driver assistance computer (secondary): w027 ECU reset fault";
CM_ SG_ 811 APS_w028_spi_rx_error "Driver assistance computer (secondary): w028 spi rx error";
CM_ SG_ 811 APS_w029_spi_tx_error "Driver assistance computer (secondary): w029 spi tx error";
CM_ SG_ 811 APS_w030_Heater_Issue "Driver assistance computer (secondary): w030 heater issue";
CM_ SG_ 811 APS_w031_canRxError "Driver assistance computer (secondary): w031 can rx error";
CM_ SG_ 811 APS_w032_canTxError "Driver assistance computer (secondary): w032 can tx error";
CM_ SG_ 811 APS_w033_gtwMia "Driver assistance computer (secondary): w033 gtw mia";
CM_ SG_ 811 APS_w034_sccmMia "Driver assistance computer (secondary): w034 sccm mia";
CM_ SG_ 811 APS_w035_espMia "Driver assistance computer (secondary): w035 esp mia";
CM_ SG_ 811 APS_w036_bdyMia "Driver assistance computer (secondary): w036 bdy mia";
CM_ SG_ 811 APS_w037_camTacIssue "Driver assistance computer (secondary): w037 cam tac issue";
CM_ SG_ 811 APS_w038_camFailure "Driver assistance computer (secondary): w038 cam failure";
CM_ SG_ 811 APS_w039_sdm_rcm_Mia "Driver assistance computer (secondary): w039 sdm rcm mia";
CM_ SG_ 811 APS_w040_autopilotAngleSaturated "Driver assistance computer (secondary): w040 autopilot angle saturated";
CM_ SG_ 811 APS_w041_autopilotRateSaturated "Driver assistance computer (secondary): w041 autopilot rate saturated";
CM_ SG_ 811 APS_w042_autopilotAborting "Driver assistance computer (secondary): w042 autopilot aborting";
CM_ SG_ 811 APS_w043_camLongRunTime "Driver assistance computer (secondary): w043 cam long run time";
CM_ SG_ 811 APS_w044_appMobileyeFailure "Driver assistance computer (secondary): w044 app mobileye failure";
CM_ SG_ 811 APS_w045_radMia "Driver assistance computer (secondary): w045 rad mia";
CM_ SG_ 811 APS_w046_eepromRecordAbsent "Driver assistance computer (secondary): w046 eeprom record absent";
CM_ SG_ 811 APS_w047_edrEvent "Driver assistance computer (secondary): w047 edr event";
CM_ SG_ 811 APS_w048_DAS_Features_Disabled "Driver assistance computer (secondary): w048 DAS features disabled";
CM_ SG_ 811 APS_w049_eyeqVersionMismatch "Driver assistance computer (secondary): w049 eyeq version mismatch";
CM_ SG_ 811 APS_w050_aeb_event "Driver assistance computer (secondary): w050 aeb event";
CM_ SG_ 811 APS_w051_radcEcuIssue "Driver assistance computer (secondary): w051 radc ecu issue";
CM_ SG_ 811 APS_w052_radcSensorIssue "Driver assistance computer (secondary): w052 radc sensor issue";
CM_ SG_ 811 APS_w053_radcCommIssue "Driver assistance computer (secondary): w053 radc comm issue";
CM_ SG_ 811 APS_w054_camAutofix "Driver assistance computer (secondary): w054 cam autofix";
CM_ SG_ 811 APS_w055_radcVersionMismatch "Driver assistance computer (secondary): w055 radc version mismatch";
CM_ SG_ 811 APS_w056_diMia "Driver assistance computer (secondary): w056 di mia";
CM_ SG_ 811 APS_w057_mcuMia "Driver assistance computer (secondary): w057 mcu mia";
CM_ SG_ 811 APS_w058_epbMia "Driver assistance computer (secondary): w058 epb mia";
CM_ SG_ 811 APS_w059_parkMia "Driver assistance computer (secondary): w059 park mia";
CM_ SG_ 811 APS_w060_fcw_event "Driver assistance computer (secondary): w060 fcw event";
CM_ SG_ 811 APS_w061_tasMia "Driver assistance computer (secondary): w061 tas mia";
CM_ SG_ 811 APS_w062_radcAlignment "Driver assistance computer (secondary): w062 radc alignment";
CM_ SG_ 811 APS_w063_parkVersionMismatch "Driver assistance computer (secondary): w063 park version mismatch";
CM_ SG_ 811 APS_w064_epasMia "Driver assistance computer (secondary): w064 epas mia";
CM_ BO_ 876 "Driver assistance computer (secondary) message: warning matrix1";
CM_ SG_ 876 APS_w065_deserializerOvercurrent "Driver assistance computer (secondary): w065 deserializer overcurrent";
CM_ SG_ 876 APS_w066_deserializerLockLost "Driver assistance computer (secondary): w066 deserializer lock lost";
CM_ SG_ 876 APS_w067_steeringAlignment "Driver assistance computer (secondary): w067 steering alignment";
CM_ SG_ 876 APS_w068_vlInconsistency "Driver assistance computer (secondary): w068 vl inconsistency";
CM_ SG_ 876 APS_w069_apcSpaceMasked "Driver assistance computer (secondary): w069 apc space masked";
CM_ SG_ 876 APS_w070_apcIncompleteCal "Driver assistance computer (secondary): w070 apc incomplete cal";
CM_ SG_ 876 APS_w071_selfparkStarted "Driver assistance computer (secondary): w071 selfpark started";
CM_ SG_ 876 APS_w072_selfparkComplete "Driver assistance computer (secondary): w072 selfpark complete";
CM_ SG_ 876 APS_w073_issueEscalatedLDW "Driver assistance computer (secondary): w073 issue escalated LDW";
CM_ SG_ 876 APS_w074_inPathStationaryObst "Driver assistance computer (secondary): w074 in path stationary obst";
CM_ SG_ 876 APS_w075_scMia "Driver assistance computer (secondary): w075 sc mia";
CM_ SG_ 876 APS_w076_mobilEyeSetC "Driver assistance computer (secondary): w076 mobil eye set c";
CM_ SG_ 876 APS_w077_pmmActive "Driver assistance computer (secondary): w077 pmm active";
CM_ SG_ 876 APS_w078_pmmActive2 "Driver assistance computer (secondary): w078 pmm active2";
CM_ SG_ 876 APS_w079_edrAvailable "Driver assistance computer (secondary): w079 edr available";
CM_ SG_ 876 APS_w080_accFailedActivation "Driver assistance computer (secondary): w080 acc failed activation";
CM_ SG_ 876 APS_w081_pmmActiveBraking "Driver assistance computer (secondary): w081 pmm active braking";
CM_ SG_ 876 APS_w082_inPathFSviolation "Driver assistance computer (secondary): w082 in path f sviolation";
CM_ SG_ 876 APS_w083_inPathRADObject "Driver assistance computer (secondary): w083 in path RAD object";
CM_ SG_ 876 APS_w084_pmmIPSO "Driver assistance computer (secondary): w084 pmm IPSO";
CM_ SG_ 876 APS_w085_pmmSteering "Driver assistance computer (secondary): w085 pmm steering";
CM_ SG_ 876 APS_w086_robCollision "Driver assistance computer (secondary): w086 rob collision";
CM_ SG_ 876 APS_w087_DEPRECATED "Driver assistance computer (secondary): w087 DEPRECATED";
CM_ SG_ 876 APS_w088_DEPRECATED "Driver assistance computer (secondary): w088 DEPRECATED";
CM_ SG_ 876 APS_w089_DEPRECATED "Driver assistance computer (secondary): w089 DEPRECATED";
CM_ SG_ 876 APS_w090_DEPRECATED "Driver assistance computer (secondary): w090 DEPRECATED";
CM_ SG_ 876 APS_w091_DEPRECATED "Driver assistance computer (secondary): w091 DEPRECATED";
CM_ SG_ 876 APS_w092_DEPRECATED "Driver assistance computer (secondary): w092 DEPRECATED";
CM_ SG_ 876 APS_w093_DEPRECATED "Driver assistance computer (secondary): w093 DEPRECATED";
CM_ SG_ 876 APS_w094_DEPRECATED "Driver assistance computer (secondary): w094 DEPRECATED";
CM_ SG_ 876 APS_w095_DEPRECATED "Driver assistance computer (secondary): w095 DEPRECATED";
CM_ SG_ 876 APS_w096_DEPRECATED "Driver assistance computer (secondary): w096 DEPRECATED";
CM_ SG_ 876 APS_w097_DEPRECATED "Driver assistance computer (secondary): w097 DEPRECATED";
CM_ SG_ 876 APS_w098_DEPRECATED "Driver assistance computer (secondary): w098 DEPRECATED";
CM_ SG_ 876 APS_w099_DEPRECATED "Driver assistance computer (secondary): w099 DEPRECATED";
CM_ SG_ 876 APS_w100_DEPRECATED "Driver assistance computer (secondary): w100 DEPRECATED";
CM_ SG_ 876 APS_w101_DEPRECATED "Driver assistance computer (secondary): w101 DEPRECATED";
CM_ SG_ 876 APS_w102_DEPRECATED "Driver assistance computer (secondary): w102 DEPRECATED";
CM_ SG_ 876 APS_w103_robExperimentalAEB "Driver assistance computer (secondary): w103 rob experimental AEB";
CM_ SG_ 876 APS_w104_DEPRECATED "Driver assistance computer (secondary): w104 DEPRECATED";
CM_ SG_ 876 APS_w105_DEPRECATED "Driver assistance computer (secondary): w105 DEPRECATED";
CM_ SG_ 876 APS_w106_torsionBarOffset "Driver assistance computer (secondary): w106 torsion bar offset";
CM_ BO_ 1113 "Driver assistance computer (secondary) message: warning matrix2";
CM_ SG_ 1113 APS_w129_ECU_Power_Issue "Driver assistance computer (secondary): w129 ECU power issue";
CM_ SG_ 1113 APS_w130_ECU_Thermal_Issue "Driver assistance computer (secondary): w130 ECU thermal issue";
CM_ SG_ 1113 APS_w131_trap_exception "Driver assistance computer (secondary): w131 trap exception";
CM_ SG_ 1113 APS_w132_appVersionMismatch "Driver assistance computer (secondary): w132 app version mismatch";
CM_ SG_ 1113 APS_w133_ETHSwitchError "Driver assistance computer (secondary): w133 ETH switch error";
CM_ SG_ 1113 APS_w134_appMia "Driver assistance computer (secondary): w134 app mia";
CM_ SG_ 1113 APS_w135_appCritical "Driver assistance computer (secondary): w135 app critical";
CM_ SG_ 1113 APS_w136_gpsDisabled "Driver assistance computer (secondary): w136 gps disabled";
CM_ SG_ 1113 APS_w137_gpsFaultReset "Driver assistance computer (secondary): w137 gps fault reset";
CM_ SG_ 1113 APS_w138_gpsComIssue "Driver assistance computer (secondary): w138 gps com issue";
CM_ SG_ 1113 APS_w139_udpBufferOverflow "Driver assistance computer (secondary): w139 udp buffer overflow";
CM_ SG_ 1113 APS_w140_vcfrontMiaVehicleBus "Driver assistance computer (secondary): w140 vcfront mia vehicle bus";
CM_ SG_ 1113 APS_w141_rcmMiaPartyBus "Driver assistance computer (secondary): w141 rcm mia party bus";
CM_ SG_ 1113 APS_w142_diMiaPartyBus "Driver assistance computer (secondary): w142 di mia party bus";
CM_ SG_ 1113 APS_w143_espMiaPartyBus "Driver assistance computer (secondary): w143 esp mia party bus";
CM_ SG_ 1113 APS_w144_vcleftMiaPartyBus "Driver assistance computer (secondary): w144 vcleft mia party bus";
CM_ SG_ 1113 APS_w145_vcrightMiaPartyBus "Driver assistance computer (secondary): w145 vcright mia party bus";
CM_ SG_ 1113 APS_w146_epas3pMiaPartyBus "Driver assistance computer (secondary): w146 epas3p mia party bus";
CM_ SG_ 1113 APS_w147_vcleftMiaVehBus "Driver assistance computer (secondary): w147 vcleft mia veh bus";
CM_ SG_ 1113 APS_w148_vcrightMiaVehBus "Driver assistance computer (secondary): w148 vcright mia veh bus";
CM_ SG_ 1113 APS_w149_epblMiaVehBus "Driver assistance computer (secondary): w149 epbl mia veh bus";
CM_ SG_ 1113 APS_w150_sccmMiaVehBus "Driver assistance computer (secondary): w150 sccm mia veh bus";
CM_ SG_ 1113 APS_w151_apRecovered "Driver assistance computer (secondary): w151 ap recovered";
CM_ SG_ 1113 APS_w152_gpsFusionStatus "Driver assistance computer (secondary): w152 gps fusion status";
CM_ SG_ 1113 APS_w153_eacInhibit "Driver assistance computer (secondary): w153 eac inhibit";
CM_ SG_ 1113 APS_w155_ethLwipError "Driver assistance computer (secondary): w155 eth lwip error";
CM_ SG_ 1113 APS_w156_lwipAssert "Driver assistance computer (secondary): w156 lwip assert";
CM_ SG_ 1113 APS_w157_autopilotReboot "Driver assistance computer (secondary): w157 autopilot reboot";
CM_ SG_ 1113 APS_w158_apbMia "Driver assistance computer (secondary): w158 apb mia";
CM_ SG_ 1113 APS_w159_apbCritical "Driver assistance computer (secondary): w159 apb critical";
CM_ SG_ 1113 APS_w160_apbVersionMismatch "Driver assistance computer (secondary): w160 apb version mismatch";
CM_ SG_ 1113 APS_w161_gpsAntennaDisconnected "Driver assistance computer (secondary): w161 gps antenna disconnected";
CM_ SG_ 1113 APS_w162_TurboA_DisRegPgoodErr "Driver assistance computer (secondary): w162 turbo a dis reg pgood err";
CM_ SG_ 1113 APS_w163_TurboA_DisRegNFault "Driver assistance computer (secondary): w163 turbo a dis reg n fault";
CM_ SG_ 1113 APS_w164_TurboA_12VFuseFault "Driver assistance computer (secondary): w164 turbo a 12 v fuse fault";
CM_ SG_ 1113 APS_w165_TurboA_Temp_NOS "Driver assistance computer (secondary): w165 turbo a temp NOS";
CM_ SG_ 1113 APS_w166_TurboA_SMSLockStepErr "Driver assistance computer (secondary): w166 turbo a SMS lock step err";
CM_ SG_ 1113 APS_w167_TurboA_TMU_Throttle "Driver assistance computer (secondary): w167 turbo a TMU throttle";
CM_ SG_ 1113 APS_w168_TurboA_SMS_WDOG "Driver assistance computer (secondary): w168 turbo a SMS WDOG";
CM_ SG_ 1113 APS_w169_TurboA_SCS_LKUP "Driver assistance computer (secondary): w169 turbo a SCS LKUP";
CM_ SG_ 1113 APS_w170_TurboA_A72_watchdog "Driver assistance computer (secondary): w170 turbo a A72 watchdog";
CM_ SG_ 1113 APS_w171_TurboA_SMS_taskUtilErr "Driver assistance computer (secondary): w171 turbo a SMS task util err";
CM_ SG_ 1113 APS_w172_apFeaturesUnavailable "Driver assistance computer (secondary): w172 ap features unavailable";
CM_ SG_ 1113 APS_w178_TurboB_DisRegPgoodErr "Driver assistance computer (secondary): w178 turbo b dis reg pgood err";
CM_ SG_ 1113 APS_w179_TurboB_DisRegNFault "Driver assistance computer (secondary): w179 turbo b dis reg n fault";
CM_ SG_ 1113 APS_w180_TurboB_12VFuseFault "Driver assistance computer (secondary): w180 turbo b 12 v fuse fault";
CM_ SG_ 1113 APS_w181_TurboB_Temp_NOS "Driver assistance computer (secondary): w181 turbo b temp NOS";
CM_ SG_ 1113 APS_w182_TurboB_SMSLockStepErr "Driver assistance computer (secondary): w182 turbo b SMS lock step err";
CM_ SG_ 1113 APS_w183_TurboB_TMU_Throttle "Driver assistance computer (secondary): w183 turbo b TMU throttle";
CM_ SG_ 1113 APS_w184_TurboB_SMS_WDOG "Driver assistance computer (secondary): w184 turbo b SMS WDOG";
CM_ SG_ 1113 APS_w185_TurboB_SCS_LKUP "Driver assistance computer (secondary): w185 turbo b SCS LKUP";
CM_ SG_ 1113 APS_w186_TurboB_A72_watchdog "Driver assistance computer (secondary): w186 turbo b A72 watchdog";
CM_ SG_ 1113 APS_w187_TurboB_SMS_taskUtilErr "Driver assistance computer (secondary): w187 turbo b SMS task util err";
CM_ SG_ 1113 APS_w188_otherTurboUartMIA "Driver assistance computer (secondary): w188 other turbo uart MIA";
CM_ SG_ 1113 APS_w189_vcfrontMiaPartyBus "Driver assistance computer (secondary): w189 vcfront mia party bus";
CM_ SG_ 1113 APS_w190_iboosterMia "Driver assistance computer (secondary): w190 ibooster mia";
CM_ SG_ 1113 APS_w191_timesyncError "Driver assistance computer (secondary): w191 timesync error";
CM_ SG_ 1113 APS_w192_CANFault "Driver assistance computer (secondary): w192 CAN fault";
CM_ BO_ 848 "Driver assistance computer (secondary) message: warning matrix3";
CM_ SG_ 848 APS_w193_camWindshieldUnclean "Driver assistance computer (secondary): w193 cam windshield unclean";
CM_ SG_ 848 APS_w194_accDriverResumeRqrd "Driver assistance computer (secondary): w194 acc driver resume rqrd";
CM_ SG_ 848 APS_w195_scwUnavailable "Driver assistance computer (secondary): w195 scw unavailable";
CM_ SG_ 848 APS_w196_stopSignWarning "Driver assistance computer (secondary): w196 stop sign warning";
CM_ SG_ 848 APS_w197_redLightWarning "Driver assistance computer (secondary): w197 red light warning";
CM_ SG_ 848 APS_w198_tsrUnavailable "Driver assistance computer (secondary): w198 tsr unavailable";
CM_ SG_ 848 APS_w199_apcAbort "Driver assistance computer (secondary): w199 apc abort";
CM_ SG_ 848 APS_w200_lcSlowdown "Driver assistance computer (secondary): w200 lc slowdown";
CM_ SG_ 848 APS_w201_lcAborting "Driver assistance computer (secondary): w201 lc aborting";
CM_ SG_ 848 APS_w202_scwNoisyEnvironment "Driver assistance computer (secondary): w202 scw noisy environment";
CM_ SG_ 848 APS_w203_apcActivation "Driver assistance computer (secondary): w203 apc activation";
CM_ SG_ 848 APS_w204_apcFinalFront "Driver assistance computer (secondary): w204 apc final front";
CM_ SG_ 848 APS_w205_apcFinalRear "Driver assistance computer (secondary): w205 apc final rear";
CM_ SG_ 848 APS_w206_autosteerNotEnabled "Driver assistance computer (secondary): w206 autosteer not enabled";
CM_ SG_ 848 APS_w207_autosteerUnavailable "Driver assistance computer (secondary): w207 autosteer unavailable";
CM_ SG_ 848 APS_w208_rackDetected "Driver assistance computer (secondary): w208 rack detected";
CM_ SG_ 848 APS_w209_autoSummonRequest "Driver assistance computer (secondary): w209 auto summon request";
CM_ SG_ 848 APS_w210_camObstrcted "Driver assistance computer (secondary): w210 cam obstrcted";
CM_ SG_ 848 APS_w211_accNoSeatBelt "Driver assistance computer (secondary): w211 acc no seat belt";
CM_ SG_ 848 APS_w212_lcUnavailableStrikeOut "Driver assistance computer (secondary): w212 lc unavailable strike out";
CM_ SG_ 848 APS_w213_autosteerStruckOut "Driver assistance computer (secondary): w213 autosteer struck out";
CM_ SG_ 848 APS_w214_driverNotIntracting "Driver assistance computer (secondary): w214 driver not intracting";
CM_ SG_ 848 APS_w215_contDriverNotIntracting "Driver assistance computer (secondary): w215 cont driver not intracting";
CM_ SG_ 848 APS_w216_driverOverriding "Driver assistance computer (secondary): w216 driver overriding";
CM_ SG_ 848 APS_w217_lcUnavailableSpeeding "Driver assistance computer (secondary): w217 lc unavailable speeding";
CM_ SG_ 848 APS_w218_lcSpeedExceededLimit "Driver assistance computer (secondary): w218 lc speed exceeded limit";
CM_ SG_ 848 APS_w219_lcTempUnavailableSpeed "Driver assistance computer (secondary): w219 lc temp unavailable speed";
CM_ SG_ 848 APS_w220_lcTempUnavailableRoad "Driver assistance computer (secondary): w220 lc temp unavailable road";
CM_ SG_ 848 APS_w221_accRadarBlind "Driver assistance computer (secondary): w221 acc radar blind";
CM_ SG_ 848 APS_w222_accCameraBlind "Driver assistance computer (secondary): w222 acc camera blind";
CM_ SG_ 848 APS_w223_accObjectInPath "Driver assistance computer (secondary): w223 acc object in path";
CM_ SG_ 848 APS_w224_accCameraCalibration "Driver assistance computer (secondary): w224 acc camera calibration";
CM_ SG_ 848 APS_w225_lcDegradedVisSpeedLmt "Driver assistance computer (secondary): w225 lc degraded vis speed lmt";
CM_ SG_ 848 APS_w226_lcCamCalNeededSpeedLmt "Driver assistance computer (secondary): w226 lc cam cal needed speed lmt";
CM_ SG_ 848 APS_w227_virtualWallBlocked "Driver assistance computer (secondary): w227 virtual wall blocked";
CM_ SG_ 848 APS_w228_DEPRECATED "Driver assistance computer (secondary): w228 DEPRECATED";
CM_ SG_ 848 APS_w229_alcUltrasoundDamaged "Driver assistance computer (secondary): w229 alc ultrasound damaged";
CM_ SG_ 848 APS_w230_alcUltrasoundBlocked "Driver assistance computer (secondary): w230 alc ultrasound blocked";
CM_ SG_ 848 APS_w231_idfEvent "Driver assistance computer (secondary): w231 idf event";
CM_ SG_ 848 APS_w232_laneChangeRequested "Driver assistance computer (secondary): w232 lane change requested";
CM_ SG_ 848 APS_w235_a72LoopDetected "Driver assistance computer (secondary): w235 a72 loop detected";
CM_ SG_ 848 APS_w236_canSharedMemError "Driver assistance computer (secondary): w236 can shared mem error";
CM_ SG_ 848 APS_w237_faultMgrEventDetected "Driver assistance computer (secondary): w237 fault mgr event detected";
CM_ SG_ 848 APS_w238_resetReason "Driver assistance computer (secondary): w238 reset reason";
CM_ SG_ 848 APS_w241_ddrInitFailures "Driver assistance computer (secondary): w241 ddr init failures";
CM_ SG_ 848 APS_w242_tripMBISTFailure "Driver assistance computer (secondary): w242 trip MBIST failure";
CM_ SG_ 848 APS_w243_tripHWErrorStatus "Driver assistance computer (secondary): w243 trip HW error status";
CM_ SG_ 848 APS_w244_gpuHWFaultStatus "Driver assistance computer (secondary): w244 gpu HW fault status";
CM_ SG_ 848 APS_w245_eloopRxFromUnexpectedSo "Driver assistance computer (secondary): w245 eloop rx from unexpected source MAC";
CM_ SG_ 848 APS_w246_ethloopSwitchPortLinkDo "Driver assistance computer (secondary): w246 ethloop switch port link down";
CM_ SG_ 848 APS_w247_ethernetFrameError "Driver assistance computer (secondary): w247 ethernet frame error";
CM_ SG_ 848 APS_w248_ethloopSwitchPoorSqi "Driver assistance computer (secondary): w248 ethloop switch poor sqi";
CM_ SG_ 848 APS_w249_ufsFailures "Driver assistance computer (secondary): w249 ufs failures";
CM_ SG_ 848 APS_w250_ethloopSwitchMemUsageTo "Driver assistance computer (secondary): w250 ethloop switch mem usage too high port2";
CM_ SG_ 848 APS_w251_ethloopSwitchMemUsageTo "Driver assistance computer (secondary): w251 ethloop switch mem usage too high port3";
CM_ SG_ 848 APS_w252_ethSwitchPortLinkDown "Driver assistance computer (secondary): w252 eth switch port link down";
CM_ SG_ 848 APS_w253_powerStateTimeout "Driver assistance computer (secondary): w253 power state timeout";
CM_ SG_ 848 APS_w254_sleepStateTimeout "Driver assistance computer (secondary): w254 sleep state timeout";
CM_ SG_ 848 APS_w255_bootHealth "Driver assistance computer (secondary): w255 boot health";
CM_ BO_ 784 "Driver assistance computer (secondary) message: warning matrix4";
CM_ SG_ 784 APS_w257_assertFailure "Driver assistance computer (secondary): w257 assert failure";
CM_ SG_ 784 APS_w258_qspiFlashSectorChecksum "Driver assistance computer (secondary): w258 qspi flash sector checksum mismatch";
CM_ SG_ 784 APS_w259_qspiFailure "Driver assistance computer (secondary): w259 qspi failure";
CM_ SG_ 784 APS_w260_pgoodFailure "Driver assistance computer (secondary): w260 pgood failure";
CM_ SG_ 784 APS_w261_vrmFaultGrpA "Driver assistance computer (secondary): w261 vrm fault grp a";
CM_ SG_ 784 APS_w262_vrmFaultGrpB "Driver assistance computer (secondary): w262 vrm fault grp b";
CM_ SG_ 784 APS_w263_vrmFaultGrpC "Driver assistance computer (secondary): w263 vrm fault grp c";
CM_ SG_ 784 APS_w264_ddrPhy0Failures "Driver assistance computer (secondary): w264 ddr phy0 failures";
CM_ SG_ 784 APS_w265_ddrPhy1Failures "Driver assistance computer (secondary): w265 ddr phy1 failures";
CM_ SG_ 784 APS_w266_ddrPhy2Failures "Driver assistance computer (secondary): w266 ddr phy2 failures";
CM_ SG_ 784 APS_w267_ddrPhy3Failures "Driver assistance computer (secondary): w267 ddr phy3 failures";
CM_ SG_ 784 APS_w268_ddrControllerFailures "Driver assistance computer (secondary): w268 ddr controller failures";
CM_ SG_ 784 APS_w269_ethSwitchRxPageCountToo "Driver assistance computer (secondary): w269 eth switch rx page count too high port0 3";
CM_ SG_ 784 APS_w270_ethSwitchRxPageCountToo "Driver assistance computer (secondary): w270 eth switch rx page count too high port4 7";
CM_ SG_ 784 APS_w271_ddrScheduler0EccErrors "Driver assistance computer (secondary): w271 ddr scheduler0 ecc errors";
CM_ SG_ 784 APS_w272_ddrScheduler1EccErrors "Driver assistance computer (secondary): w272 ddr scheduler1 ecc errors";
CM_ SG_ 784 APS_w273_ddrScheduler2EccErrors "Driver assistance computer (secondary): w273 ddr scheduler2 ecc errors";
CM_ SG_ 784 APS_w274_ddrScheduler3EccErrors "Driver assistance computer (secondary): w274 ddr scheduler3 ecc errors";
CM_ SG_ 784 APS_w275_ddrScheduler4EccErrors "Driver assistance computer (secondary): w275 ddr scheduler4 ecc errors";
CM_ SG_ 784 APS_w276_ddrScheduler5EccErrors "Driver assistance computer (secondary): w276 ddr scheduler5 ecc errors";
CM_ SG_ 784 APS_w277_ddrScheduler6EccErrors "Driver assistance computer (secondary): w277 ddr scheduler6 ecc errors";
CM_ SG_ 784 APS_w278_ddrScheduler7EccErrors "Driver assistance computer (secondary): w278 ddr scheduler7 ecc errors";
CM_ SG_ 784 APS_w279_ufsPartitionError "Driver assistance computer (secondary): w279 ufs partition error";
CM_ SG_ 784 APS_w280_pepsMia "Driver assistance computer (secondary): w280 peps mia";
CM_ SG_ 784 APS_w281_rsaMia "Driver assistance computer (secondary): w281 rsa mia";
CM_ SG_ 784 APS_w282_smmuError "Driver assistance computer (secondary): w282 smmu error";
CM_ SG_ 784 APS_w284_cam12VBuckBoostAPwrIssu "Driver assistance computer (secondary): w284 cam12 v buck boost a pwr issue";
CM_ SG_ 784 APS_w285_cam12VBuckBoostBPwrIssu "Driver assistance computer (secondary): w285 cam12 v buck boost b pwr issue";
CM_ SG_ 784 APS_w286_cam12VEFuseAPrimaryIssu "Driver assistance computer (secondary): w286 cam12 VE fuse a primary issue";
CM_ SG_ 784 APS_w287_cam12VEFuseASecondaryIs "Driver assistance computer (secondary): w287 cam12 VE fuse a secondary issue";
CM_ SG_ 784 APS_w288_brakeboosterMia "Driver assistance computer (secondary): w288 brakebooster mia";
CM_ SG_ 784 APS_w289_turboTemperatureWarning "Driver assistance computer (secondary): w289 turbo temperature warning";
CM_ SG_ 784 APS_w290_cam12VBuckBoostBPwrRing "Driver assistance computer (secondary): w290 cam12 v buck boost b pwr ringing";
BA_DEF_ BO_ "GenMsgCycleTime" INT 0 3600000;
BA_DEF_ BO_ "GenMsgSendType" ENUM "Cyclic","NotUsed","NotUsed","NotUsed","NotUsed","NotUsed","NotUsed","IfActive","NoMsgSendType","NotUsed";
BA_DEF_ BO_ "VFrameFormat" ENUM "StandardCAN","ExtendedCAN","reserved","J1939PG","reserved","reserved","reserved","reserved","reserved","reserved","reserved","reserved","reserved","reserved","StandardCAN_FD","ExtendedCAN_FD";
BA_DEF_ BO_ "CANFD_BRS" ENUM "0","1";
BA_DEF_ SG_ "GenSigSNA" STRING;
BA_DEF_ SG_ "SystemSignalLongSymbol" STRING;
BA_DEF_ SG_ "Confidence" ENUM "validated","plausible","layout-only","contradicted";
BA_DEF_DEF_ "GenMsgCycleTime" 0;
BA_DEF_DEF_ "GenMsgSendType" "NoMsgSendType";
BA_DEF_DEF_ "VFrameFormat" "StandardCAN";
BA_DEF_DEF_ "CANFD_BRS" "1";
BA_DEF_DEF_ "GenSigSNA" "";
BA_DEF_DEF_ "SystemSignalLongSymbol" "";
BA_DEF_DEF_ "Confidence" "layout-only";
BA_ "GenMsgCycleTime" BO_ 637 100;
BA_ "GenMsgSendType" BO_ 637 0;
BA_ "GenMsgCycleTime" BO_ 1865 100;
BA_ "GenMsgSendType" BO_ 1865 0;
BA_ "GenMsgCycleTime" BO_ 2044 100;
BA_ "GenMsgSendType" BO_ 2044 0;
BA_ "GenMsgCycleTime" BO_ 970 500;
BA_ "GenMsgSendType" BO_ 970 0;
BA_ "GenMsgCycleTime" BO_ 1510 1000;
BA_ "GenMsgSendType" BO_ 1510 0;
BA_ "GenMsgCycleTime" BO_ 811 1000;
BA_ "GenMsgSendType" BO_ 811 0;
BA_ "GenMsgCycleTime" BO_ 876 1000;
BA_ "GenMsgSendType" BO_ 876 0;
BA_ "GenMsgCycleTime" BO_ 1113 1000;
BA_ "GenMsgSendType" BO_ 1113 0;
BA_ "GenMsgCycleTime" BO_ 848 1000;
BA_ "GenMsgSendType" BO_ 848 0;
BA_ "GenMsgCycleTime" BO_ 784 1000;
BA_ "GenMsgSendType" BO_ 784 0;
BA_ "Confidence" SG_ 1481 APS_alertID 1;
BA_ "Confidence" SG_ 1481 APS_alertSource 1;
BA_ "Confidence" SG_ 1481 APS_alertState 1;
BA_ "Confidence" SG_ 1481 APS_sw010_HorizontalMisalignment 1;
BA_ "Confidence" SG_ 1481 APS_sw010_VerticalMisalignment 1;
BA_ "Confidence" SG_ 1481 APS_sw010_VmaPlausibility 1;
BA_ "Confidence" SG_ 1481 APS_sw019_taskId 1;
BA_ "Confidence" SG_ 1481 APS_sw019_numFreeBytes 1;
BA_ "Confidence" SG_ 1481 APS_sw019_timeStamp 1;
BA_ "Confidence" SG_ 1481 APS_sw021_minThreshold 1;
BA_ "Confidence" SG_ 1481 APS_sw021_maxThreshold 1;
BA_ "Confidence" SG_ 1481 APS_sw021_currentTemperature 1;
BA_ "Confidence" SG_ 1481 APS_sw070_temperature 1;
BA_ "Confidence" SG_ 1481 APS_sw070_currentSpeed 1;
BA_ "Confidence" SG_ 1481 APS_sw071_endPosX 1;
BA_ "Confidence" SG_ 1481 APS_sw071_endPosY 1;
BA_ "Confidence" SG_ 1481 APS_sw071_temperature 1;
BA_ "Confidence" SG_ 1481 APS_sw072_vehicleX 1;
BA_ "Confidence" SG_ 1481 APS_sw072_vehicleY 1;
BA_ "Confidence" SG_ 1481 APS_sw072_vehicleHeading 1;
BA_ "Confidence" SG_ 1481 APS_sw072_endDistance 1;
BA_ "Confidence" SG_ 1481 APS_sw077_oocDistance 1;
BA_ "Confidence" SG_ 1481 APS_sw077_oocConfidence 1;
BA_ "Confidence" SG_ 1481 APS_sw077_vehicleSpeed 1;
BA_ "Confidence" SG_ 1481 APS_sw077_oocUntrackedTime 1;
BA_ "Confidence" SG_ 1481 APS_sw081_radarDistance 1;
BA_ "Confidence" SG_ 1481 APS_sw081_radarTTC 1;
BA_ "Confidence" SG_ 1481 APS_sw081_cameraDistance 1;
BA_ "Confidence" SG_ 1481 APS_sw081_cameraTTC 1;
BA_ "Confidence" SG_ 1481 APS_sw081_pedalPosition 1;
BA_ "Confidence" SG_ 1481 APS_sw129_currentVoltage 1;
BA_ "Confidence" SG_ 1481 APS_sw129_maxThreshold 1;
BA_ "Confidence" SG_ 1481 APS_sw129_minThreshold 1;
BA_ "Confidence" SG_ 1481 APS_sw129_railID 1;
BA_ "Confidence" SG_ 1481 APS_sw130_currentTemperature 1;
BA_ "Confidence" SG_ 1481 APS_sw130_maxThreshold 1;
BA_ "Confidence" SG_ 1481 APS_sw130_minThreshold 1;
BA_ "Confidence" SG_ 1481 APS_sw132_mismatchType 1;
BA_ "SystemSignalLongSymbol" SG_ 1481 APS_sw133_switchEthernetInterLin "APS_sw133_switchEthernetInterLinkDown";
BA_ "SystemSignalLongSymbol" SG_ 1481 APS_sw133_ethSwitchReadFwVerFail "APS_sw133_ethSwitchReadFwVerFailed";
BA_ "SystemSignalLongSymbol" SG_ 1481 APS_sw133_ethSwitchTimedoutUpdat "APS_sw133_ethSwitchTimedoutUpdate";
BA_ "SystemSignalLongSymbol" SG_ 1481 APS_sw134_dasMatrixBendAngleRqPt "APS_sw134_dasMatrixBendAngleRqPty";
BA_ "Confidence" SG_ 1481 APS_sw135_appCriticalReason 1;
BA_ "Confidence" SG_ 1481 APS_sw151_apGpioState 1;
BA_ "Confidence" SG_ 1481 APS_sw151_apWatchDogState 1;
BA_ "GenSigSNA" SG_ 1481 APS_sw151_apWatchDogState "7";
BA_ "Confidence" SG_ 1481 APS_sw151_diGear 1;
BA_ "GenSigSNA" SG_ 1481 APS_sw151_diGear "7";
BA_ "Confidence" SG_ 1481 APS_sw151_recoveryPathway 1;
BA_ "Confidence" SG_ 1481 APS_sw151_parkerType 1;
BA_ "Confidence" SG_ 1481 APS_sw153_eacInhibitReason 1;
BA_ "Confidence" SG_ 1481 APS_sw153_eacInternalState 1;
BA_ "SystemSignalLongSymbol" SG_ 1481 APS_sw158_dasMatrixBendAngleRqPt "APS_sw158_dasMatrixBendAngleRqPty";
BA_ "Confidence" SG_ 1481 APS_sw159_apbCriticalReason 1;
BA_ "Confidence" SG_ 1481 APS_sw160_mismatchType 1;
BA_ "Confidence" SG_ 1481 APS_sw188_otherTurbo 1;
BA_ "Confidence" SG_ 1481 APS_sw192_CANbus 1;
BA_ "Confidence" SG_ 1481 APS_sw192_msgIo 1;
BA_ "Confidence" SG_ 1481 APS_sw192_queueFailure 1;
BA_ "Confidence" SG_ 1481 APS_sw199_abortCodeDas 1;
BA_ "Confidence" SG_ 1481 APS_sw199_abortCodePARK 1;
BA_ "GenSigSNA" SG_ 1481 APS_sw199_abortCodePARK "31";
BA_ "Confidence" SG_ 1481 APS_sw199_currentSTW 1;
BA_ "Confidence" SG_ 1481 APS_sw199_currentSpeed 1;
BA_ "Confidence" SG_ 1481 APS_sw199_maxSpeed 1;
BA_ "Confidence" SG_ 1481 APS_sw203_controlType 1;
BA_ "GenSigSNA" SG_ 1481 APS_sw203_controlType "15";
BA_ "Confidence" SG_ 1481 APS_sw203_slotSizeX 1;
BA_ "Confidence" SG_ 1481 APS_sw203_slotSizeY 1;
BA_ "Confidence" SG_ 1481 APS_sw203_startDistance 1;
BA_ "Confidence" SG_ 1481 APS_sw203_vehicleSkew 1;
BA_ "Confidence" SG_ 1481 APS_sw204_frLeft 1;
BA_ "Confidence" SG_ 1481 APS_sw204_frLeftMiddle 1;
BA_ "Confidence" SG_ 1481 APS_sw204_frMiddle 1;
BA_ "Confidence" SG_ 1481 APS_sw204_frRight 1;
BA_ "Confidence" SG_ 1481 APS_sw204_frRightMiddle 1;
BA_ "Confidence" SG_ 1481 APS_sw204_maxSpeed 1;
BA_ "Confidence" SG_ 1481 APS_sw205_oocDistance 1;
BA_ "Confidence" SG_ 1481 APS_sw205_rrLeft 1;
BA_ "Confidence" SG_ 1481 APS_sw205_rrLeftMiddle 1;
BA_ "Confidence" SG_ 1481 APS_sw205_rrMiddle 1;
BA_ "Confidence" SG_ 1481 APS_sw205_rrRight 1;
BA_ "Confidence" SG_ 1481 APS_sw205_rrRightMiddle 1;
BA_ "Confidence" SG_ 1481 APS_sw235_resetOrigin 1;
BA_ "Confidence" SG_ 1481 APS_sw237_faultSource 1;
BA_ "Confidence" SG_ 1481 APS_sw243_errorStatus 1;
BA_ "Confidence" SG_ 1481 APS_sw249_ufsInitFailureReason 1;
BA_ "SystemSignalLongSymbol" SG_ 1481 APS_sw253_apWaitForShutdownTimeo "APS_sw253_apWaitForShutdownTimeout";
BA_ "SystemSignalLongSymbol" SG_ 1481 APS_sw254_waitForBusSilenceTimeo "APS_sw254_waitForBusSilenceTimeout";
BA_ "SystemSignalLongSymbol" SG_ 1481 APS_sw255_adcWrapperInitBootErro "APS_sw255_adcWrapperInitBootError";
BA_ "SystemSignalLongSymbol" SG_ 1481 APS_sw255_boardRevisionInitBootE "APS_sw255_boardRevisionInitBootError";
BA_ "SystemSignalLongSymbol" SG_ 1481 APS_sw255_dfuCheckinSubsystemBoo "APS_sw255_dfuCheckinSubsystemBootError";
BA_ "SystemSignalLongSymbol" SG_ 1481 APS_sw255_sectorProtectionBootEr "APS_sw255_sectorProtectionBootError";
BA_ "Confidence" SG_ 1481 APS_sw289_turboTemperature 1;
BA_ "GenSigSNA" SG_ 1481 APS_sw289_turboTemperature "128";
BA_ "Confidence" SG_ 1481 APS_sw289_peer_turboTemperature 1;
BA_ "GenSigSNA" SG_ 1481 APS_sw289_peer_turboTemperature "128";
BA_ "Confidence" SG_ 637 APS_eacAllow 0;
BA_ "GenSigSNA" SG_ 637 APS_eacAllow "3";
BA_ "Confidence" SG_ 637 APS_eacMonitorCounter 0;
BA_ "Confidence" SG_ 637 APS_eacMonitorChecksum 0;
BA_ "Confidence" SG_ 1865 APS_A_lowPowerRequest 0;
BA_ "Confidence" SG_ 1865 APS_A_lowPowerRequestor 0;
BA_ "Confidence" SG_ 1865 APS_A_forcePowerOffRequest 0;
BA_ "Confidence" SG_ 1865 APS_B_lowPowerRequest 0;
BA_ "Confidence" SG_ 1865 APS_B_lowPowerRequestor 0;
BA_ "Confidence" SG_ 1865 APS_B_forcePowerOffRequest 0;
BA_ "Confidence" SG_ 2044 APS_primaryTurbo 0;
BA_ "Confidence" SG_ 2044 APS_A_arbState 0;
BA_ "Confidence" SG_ 2044 APS_A_powerState 0;
BA_ "Confidence" SG_ 2044 APS_A_sleepState 0;
BA_ "Confidence" SG_ 2044 APS_A_resetState 0;
BA_ "Confidence" SG_ 2044 APS_A_faultState 0;
BA_ "Confidence" SG_ 2044 APS_secondaryTurbo 0;
BA_ "Confidence" SG_ 2044 APS_B_arbState 0;
BA_ "Confidence" SG_ 2044 APS_B_powerState 0;
BA_ "Confidence" SG_ 2044 APS_B_sleepState 0;
BA_ "Confidence" SG_ 2044 APS_B_resetState 0;
BA_ "Confidence" SG_ 2044 APS_B_faultState 0;
BA_ "Confidence" SG_ 2044 APS_autosteerMonitorState 1;
BA_ "Confidence" SG_ 970 APS_appStatusMonitorState 0;
BA_ "Confidence" SG_ 970 APS_vehBehaviorState 0;
BA_ "Confidence" SG_ 970 APS_canMaster 0;
BA_ "GenSigSNA" SG_ 970 APS_canMaster "3";
BA_ "Confidence" SG_ 970 APS_appGpioState 0;
BA_ "Confidence" SG_ 970 APS_eacInternalState 0;
BA_ "Confidence" SG_ 970 APS_switchState 0;
BA_ "Confidence" SG_ 970 APS_apbStatusMonitorState 0;
BA_ "Confidence" SG_ 970 APS_apbGpioState 0;
BA_ "Confidence" SG_ 970 APS_statusCounter 0;
BA_ "Confidence" SG_ 970 APS_locLimitReason 0;
BA_ "Confidence" SG_ 970 APS_appPowerStateRequest 0;
BA_ "Confidence" SG_ 970 APS_appPowerStateReason 0;
BA_ "Confidence" SG_ 970 APS_apbPowerStateRequest 1;
BA_ "Confidence" SG_ 970 APS_apbPowerStateReason 1;
BA_ "Confidence" SG_ 970 APS_heaterStateDebug 1;
BA_ "GenSigSNA" SG_ 970 APS_heaterStateDebug "7";
BA_ "Confidence" SG_ 970 APS_gpsAntennaState 1;
BA_ "Confidence" SG_ 970 APS_arbState 1;
BA_ "Confidence" SG_ 970 APS_socPowerOperatingMode 1;
BA_ "Confidence" SG_ 970 APS_otherArbState 1;
BA_ "Confidence" SG_ 1510 APS_A_cam12v0Voltage 0;
BA_ "GenSigSNA" SG_ 1510 APS_A_cam12v0Voltage "4095";
BA_ "Confidence" SG_ 1510 APS_B_cam12v0Voltage 0;
BA_ "GenSigSNA" SG_ 1510 APS_B_cam12v0Voltage "4095";
BA_ "Confidence" SG_ 1510 APS_A_turboMaxTemperature 0;
BA_ "GenSigSNA" SG_ 1510 APS_A_turboMaxTemperature "128";
BA_ "Confidence" SG_ 1510 APS_A_turboProbeType 0;
BA_ "GenSigSNA" SG_ 1510 APS_A_turboProbeType "63";
BA_ "Confidence" SG_ 1510 APS_B_turboMaxTemperature 0;
BA_ "GenSigSNA" SG_ 1510 APS_B_turboMaxTemperature "128";
BA_ "Confidence" SG_ 1510 APS_B_turboProbeType 0;
BA_ "GenSigSNA" SG_ 1510 APS_B_turboProbeType "63";
BA_ "SystemSignalLongSymbol" SG_ 848 APS_w245_eloopRxFromUnexpectedSo "APS_w245_eloopRxFromUnexpectedSourceMAC";
BA_ "SystemSignalLongSymbol" SG_ 848 APS_w246_ethloopSwitchPortLinkDo "APS_w246_ethloopSwitchPortLinkDown";
BA_ "SystemSignalLongSymbol" SG_ 848 APS_w250_ethloopSwitchMemUsageTo "APS_w250_ethloopSwitchMemUsageTooHighPort2";
BA_ "SystemSignalLongSymbol" SG_ 848 APS_w251_ethloopSwitchMemUsageTo "APS_w251_ethloopSwitchMemUsageTooHighPort3";
BA_ "SystemSignalLongSymbol" SG_ 784 APS_w258_qspiFlashSectorChecksum "APS_w258_qspiFlashSectorChecksumMismatch";
BA_ "SystemSignalLongSymbol" SG_ 784 APS_w269_ethSwitchRxPageCountToo "APS_w269_ethSwitchRxPageCountTooHighPort0_3";
BA_ "SystemSignalLongSymbol" SG_ 784 APS_w270_ethSwitchRxPageCountToo "APS_w270_ethSwitchRxPageCountTooHighPort4_7";
BA_ "SystemSignalLongSymbol" SG_ 784 APS_w284_cam12VBuckBoostAPwrIssu "APS_w284_cam12VBuckBoostAPwrIssue";
BA_ "SystemSignalLongSymbol" SG_ 784 APS_w285_cam12VBuckBoostBPwrIssu "APS_w285_cam12VBuckBoostBPwrIssue";
BA_ "SystemSignalLongSymbol" SG_ 784 APS_w286_cam12VEFuseAPrimaryIssu "APS_w286_cam12VEFuseAPrimaryIssue";
BA_ "SystemSignalLongSymbol" SG_ 784 APS_w287_cam12VEFuseASecondaryIs "APS_w287_cam12VEFuseASecondaryIssue";
BA_ "SystemSignalLongSymbol" SG_ 784 APS_w290_cam12VBuckBoostBPwrRing "APS_w290_cam12VBuckBoostBPwrRinging";
VAL_ 1481 APS_alertID 290 "w290_cam12VBuckBoostBPwrRinging" 289 "w289_turboTemperatureWarning" 288 "w288_brakeboosterMia" 287 "w287_cam12VEFuseASecondaryIssue" 286 "w286_cam12VEFuseAPrimaryIssue" 285 "w285_cam12VBuckBoostBPwrIssue" 284 "w284_cam12VBuckBoostAPwrIssue" 282 "w282_smmuError" 281 "w281_rsaMia" 280 "w280_pepsMia" 279 "w279_ufsPartitionError" 278 "w278_ddrScheduler7EccErrors" 277 "w277_ddrScheduler6EccErrors" 276 "w276_ddrScheduler5EccErrors" 275 "w275_ddrScheduler4EccErrors" 274 "w274_ddrScheduler3EccErrors" 273 "w273_ddrScheduler2EccErrors" 272 "w272_ddrScheduler1EccErrors" 271 "w271_ddrScheduler0EccErrors" 270 "w270_ethSwitchRxPageCountTooHighPort4_7" 269 "w269_ethSwitchRxPageCountTooHighPort0_3" 268 "w268_ddrControllerFailures" 267 "w267_ddrPhy3Failures" 266 "w266_ddrPhy2Failures" 265 "w265_ddrPhy1Failures" 264 "w264_ddrPhy0Failures" 263 "w263_vrmFaultGrpC" 262 "w262_vrmFaultGrpB" 261 "w261_vrmFaultGrpA" 260 "w260_pgoodFailure" 259 "w259_qspiFailure" 258 "w258_qspiFlashSectorChecksumMismatch" 257 "w257_assertFailure" 255 "w255_bootHealth" 254 "w254_sleepStateTimeout" 253 "w253_powerStateTimeout" 252 "w252_ethSwitchPortLinkDown" 251 "w251_ethloopSwitchMemUsageTooHighPort3" 250 "w250_ethloopSwitchMemUsageTooHighPort2" 249 "w249_ufsFailures" 248 "w248_ethloopSwitchPoorSqi" 247 "w247_ethernetFrameError" 246 "w246_ethloopSwitchPortLinkDown" 245 "w245_eloopRxFromUnexpectedSourceMAC" 244 "w244_gpuHWFaultStatus" 243 "w243_tripHWErrorStatus" 242 "w242_tripMBISTFailure" 241 "w241_ddrInitFailures" 238 "w238_resetReason" 237 "w237_faultMgrEventDetected" 236 "w236_canSharedMemError" 235 "w235_a72LoopDetected" 232 "w232_laneChangeRequested" 231 "w231_idfEvent" 230 "w230_alcUltrasoundBlocked" 229 "w229_alcUltrasoundDamaged" 228 "w228_DEPRECATED" 227 "w227_virtualWallBlocked" 226 "w226_lcCamCalNeededSpeedLmt" 225 "w225_lcDegradedVisSpeedLmt" 224 "w224_accCameraCalibration" 223 "w223_accObjectInPath" 222 "w222_accCameraBlind" 221 "w221_accRadarBlind" 220 "w220_lcTempUnavailableRoad" 219 "w219_lcTempUnavailableSpeed" 218 "w218_lcSpeedExceededLimit" 217 "w217_lcUnavailableSpeeding" 216 "w216_driverOverriding" 215 "w215_contDriverNotIntracting" 214 "w214_driverNotIntracting" 213 "w213_autosteerStruckOut" 212 "w212_lcUnavailableStrikeOut" 211 "w211_accNoSeatBelt" 210 "w210_camObstrcted" 209 "w209_autoSummonRequest" 208 "w208_rackDetected" 207 "w207_autosteerUnavailable" 206 "w206_autosteerNotEnabled" 205 "w205_apcFinalRear" 204 "w204_apcFinalFront" 203 "w203_apcActivation" 202 "w202_scwNoisyEnvironment" 201 "w201_lcAborting" 200 "w200_lcSlowdown" 199 "w199_apcAbort" 198 "w198_tsrUnavailable" 197 "w197_redLightWarning" 196 "w196_stopSignWarning" 195 "w195_scwUnavailable" 194 "w194_accDriverResumeRqrd" 193 "w193_camWindshieldUnclean" 192 "w192_CANFault" 191 "w191_timesyncError" 190 "w190_iboosterMia" 189 "w189_vcfrontMiaPartyBus" 188 "w188_otherTurboUartMIA" 187 "w187_TurboB_SMS_taskUtilErr" 186 "w186_TurboB_A72_watchdog" 185 "w185_TurboB_SCS_LKUP" 184 "w184_TurboB_SMS_WDOG" 183 "w183_TurboB_TMU_Throttle" 182 "w182_TurboB_SMSLockStepErr" 181 "w181_TurboB_Temp_NOS" 180 "w180_TurboB_12VFuseFault" 179 "w179_TurboB_DisRegNFault" 178 "w178_TurboB_DisRegPgoodErr" 172 "w172_apFeaturesUnavailable" 171 "w171_TurboA_SMS_taskUtilErr" 170 "w170_TurboA_A72_watchdog" 169 "w169_TurboA_SCS_LKUP" 168 "w168_TurboA_SMS_WDOG" 167 "w167_TurboA_TMU_Throttle" 166 "w166_TurboA_SMSLockStepErr" 165 "w165_TurboA_Temp_NOS" 164 "w164_TurboA_12VFuseFault" 163 "w163_TurboA_DisRegNFault" 162 "w162_TurboA_DisRegPgoodErr" 161 "w161_gpsAntennaDisconnected" 160 "w160_apbVersionMismatch" 159 "w159_apbCritical" 158 "w158_apbMia" 157 "w157_autopilotReboot" 156 "w156_lwipAssert" 155 "w155_ethLwipError" 153 "w153_eacInhibit" 152 "w152_gpsFusionStatus" 151 "w151_apRecovered" 150 "w150_sccmMiaVehBus" 149 "w149_epblMiaVehBus" 148 "w148_vcrightMiaVehBus" 147 "w147_vcleftMiaVehBus" 146 "w146_epas3pMiaPartyBus" 145 "w145_vcrightMiaPartyBus" 144 "w144_vcleftMiaPartyBus" 143 "w143_espMiaPartyBus" 142 "w142_diMiaPartyBus" 141 "w141_rcmMiaPartyBus" 140 "w140_vcfrontMiaVehicleBus" 139 "w139_udpBufferOverflow" 138 "w138_gpsComIssue" 137 "w137_gpsFaultReset" 136 "w136_gpsDisabled" 135 "w135_appCritical" 134 "w134_appMia" 133 "w133_ETHSwitchError" 132 "w132_appVersionMismatch" 131 "w131_trap_exception" 130 "w130_ECU_Thermal_Issue" 129 "w129_ECU_Power_Issue" 106 "w106_torsionBarOffset" 105 "w105_DEPRECATED" 104 "w104_DEPRECATED" 103 "w103_robExperimentalAEB" 102 "w102_DEPRECATED" 101 "w101_DEPRECATED" 100 "w100_DEPRECATED" 99 "w099_DEPRECATED" 98 "w098_DEPRECATED" 97 "w097_DEPRECATED" 96 "w096_DEPRECATED" 95 "w095_DEPRECATED" 94 "w094_DEPRECATED" 93 "w093_DEPRECATED" 92 "w092_DEPRECATED" 91 "w091_DEPRECATED" 90 "w090_DEPRECATED" 89 "w089_DEPRECATED" 88 "w088_DEPRECATED" 87 "w087_DEPRECATED" 86 "w086_robCollision" 85 "w085_pmmSteering" 84 "w084_pmmIPSO" 83 "w083_inPathRADObject" 82 "w082_inPathFSviolation" 81 "w081_pmmActiveBraking" 80 "w080_accFailedActivation" 79 "w079_edrAvailable" 78 "w078_pmmActive2" 77 "w077_pmmActive" 76 "w076_mobilEyeSetC" 75 "w075_scMia" 74 "w074_inPathStationaryObst" 73 "w073_issueEscalatedLDW" 72 "w072_selfparkComplete" 71 "w071_selfparkStarted" 70 "w070_apcIncompleteCal" 69 "w069_apcSpaceMasked" 68 "w068_vlInconsistency" 67 "w067_steeringAlignment" 66 "w066_deserializerLockLost" 65 "w065_deserializerOvercurrent" 64 "w064_epasMia" 63 "w063_parkVersionMismatch" 62 "w062_radcAlignment" 61 "w061_tasMia" 60 "w060_fcw_event" 59 "w059_parkMia" 58 "w058_epbMia" 57 "w057_mcuMia" 56 "w056_diMia" 55 "w055_radcVersionMismatch" 54 "w054_camAutofix" 53 "w053_radcCommIssue" 52 "w052_radcSensorIssue" 51 "w051_radcEcuIssue" 50 "w050_aeb_event" 49 "w049_eyeqVersionMismatch" 48 "w048_DAS_Features_Disabled" 47 "w047_edrEvent" 46 "w046_eepromRecordAbsent" 45 "w045_radMia" 44 "w044_appMobileyeFailure" 43 "w043_camLongRunTime" 42 "w042_autopilotAborting" 41 "w041_autopilotRateSaturated" 40 "w040_autopilotAngleSaturated" 39 "w039_sdm_rcm_Mia" 38 "w038_camFailure" 37 "w037_camTacIssue" 36 "w036_bdyMia" 35 "w035_espMia" 34 "w034_sccmMia" 33 "w033_gtwMia" 32 "w032_canTxError" 31 "w031_canRxError" 30 "w030_Heater_Issue" 29 "w029_spi_tx_error" 28 "w028_spi_rx_error" 27 "w027_ECU_Reset_Fault" 26 "w026_ECU_timingIssue" 25 "w025_LC_Steering_Override" 24 "w024_ECU_Watchdog_Reset" 23 "w023_ECU_Cam_Statemismatc" 22 "w022_ECU_EEPROM_Failure" 21 "w021_ECU_Temperature_Issue" 20 "w020_ECU_checkstopError" 19 "w019_ECU_Stack_Overflow" 18 "w018_ECU_Power_Issue" 17 "w017_Cam_Msg_MIA" 16 "w016_aeb_e_event" 15 "w015_Camera_Failsafes" 14 "w014_swAssert" 13 "w013_Cam_Watchdog" 12 "w012_Cam_BootFailure" 11 "w011_scaEvent" 10 "w010_radcCalibIssue" 9 "w009_aebFault" 8 "w008_parkDisabled" 7 "w007_ahlbDisabled" 6 "w006_aebCancelled" 5 "w005_fcwCancelled" 4 "w004_accDisabled" 3 "w003_isaDisabled" 2 "w002_ldwDisabled" 1 "w001_DEPRECATED" 0 "ALERT_DO_NOT_USE_ZERO" ;
VAL_ 1481 APS_alertSource 1 "TURBOB" 0 "TURBOA" ;
VAL_ 1481 APS_alertState 1 "SET" 0 "CLEARED" ;
VAL_ 1481 APS_sw019_taskId 32 "MAX_TASK_ID" 31 "TASKS_ISOTERM_A72" 30 "TASKS_ISOTERM_SMS" 29 "TASKS_APP_1HZ" 28 "TASKS_APP_1KHZ" 27 "TASKS_SMS_SERIAL" 26 "TASKS_CAN_AP_RX" 25 "TASKS_CAN_AP_TX" 24 "TASKS_TMU" 23 "TASKS_WDG_TASK" 22 "TASKS_MBX_RELAY" 21 "TASKS_MBX_SCS_RX_HIGH" 20 "TASKS_MBX_SCS_RX_LOW" 19 "TASKS_MBX_SCS_TX_HIGH" 18 "TASKS_MBX_SCS_TX_LOW" 17 "TASKS_MBX_AP_RX_HIGH" 16 "TASKS_MBX_AP_RX_LOW" 15 "TASKS_MBX_AP_TX_HIGH" 14 "TASKS_MBX_AP_TX_LOW" 13 "TASKS_VEH_CAN" 12 "TASKS_RADAR_CAN" 11 "TASKS_CH_CAN" 10 "TASKS_PARTY_CAN" 9 "TASK_DEBUG_SMS_SERIAL_RX" 8 "TASK_DEBUG_SERIAL_TX" 7 "TASKS_SMS_SMS_UART_RX" 6 "TASKS_SMS_SMS_UART_TX" 5 "TASKS_VEHICLE" 4 "TASKS_MOBILEYE" 3 "TASKS_UDS" 2 "TASKS_CAN" 1 "TASKS_INIT" 0 "TASKS_RESERVED" ;
VAL_ 1481 APS_sw129_railID 17 "C_RAIL" 16 "SENSOR3_TEMP" 15 "SENSOR2_TEMP" 14 "SENSOR1_TEMP" 13 "SENSOR0_TEMP" 12 "GPS_ANT_DET" 11 "PARK_THERM_ALERT_MON" 10 "PARK_SYS_RST_ARX_MON" 9 "VDD_FAN" 8 "1V1_ETH" 7 "1V5_ETH" 6 "1V3_ARX" 5 "1V8_ARX" 4 "5V0_ARX" 3 "5V0_MAIN4" 2 "5V0_MAIN3" 1 "5V0_MAIN2" 0 "5V0_MAIN1" ;
VAL_ 1481 APS_sw132_mismatchType 1 "GTW_APP_FW_REPO_GITHASH" 0 "APS_APP_FW_REPO_GITHASH" ;
VAL_ 1481 APS_sw135_appCriticalReason 8 "OTHER_TURBO_TIMESYNC_ERROR" 7 "TIMESYNC_ERROR" 6 "OTHER_TURBO_VERSION_MISMATCH" 5 "WATCHDOG_CRITICAL" 4 "MIA" 3 "VERSION_MISMATCH" 2 "GPIO_CRITICAL" 1 "BOOT_TIMEOUT" 0 "UNKNOWN" ;
VAL_ 1481 APS_sw151_apGpioState 3 "HEALTHY" 2 "CRITICAL" 1 "DISABLED" 0 "PWR_DOWN_REBOOT" ;
VAL_ 1481 APS_sw151_apWatchDogState 7 "SNA" 3 "HEALTHY" 2 "CRITICAL" 1 "DEGRADED" 0 "UNKNOWN" ;
VAL_ 1481 APS_sw151_diGear 7 "SNA" 4 "D" 3 "N" 2 "R" 1 "P" 0 "INVALID" ;
VAL_ 1481 APS_sw151_recoveryPathway 3 "RECOVERY_HEALTHY_IN_PARK" 2 "RECOVERY_LOCAL_BUILD_GPIO" 1 "RECOVERY_POWER_DOWN" 0 "NO_RECOVERY_PATH" ;
VAL_ 1481 APS_sw151_parkerType 1 "PRIMARY" 0 "BACKUP" ;
VAL_ 1481 APS_sw153_eacInhibitReason 9 "RSA_MIA" 8 "PEPS_MIA" 7 "LSS_DURATION" 6 "DI_MIA" 5 "DAS_MIA" 4 "EPAS_MIA" 3 "HYSTERESIS" 2 "DURATION" 1 "EPAS" 0 "NONE" ;
VAL_ 1481 APS_sw153_eacInternalState 7 "NUM_STATES" 6 "STATE_LSS" 5 "STATE_OVERRIDE" 4 "STATE_INHIBIT" 3 "STATE_AUTOPARK" 2 "STATE_CONTINUOUS" 1 "STATE_MOMENTARY" 0 "STATE_INIT" ;
VAL_ 1481 APS_sw159_apbCriticalReason 8 "OTHER_TURBO_TIMESYNC_ERROR" 7 "TIMESYNC_ERROR" 6 "OTHER_TURBO_VERSION_MISMATCH" 5 "WATCHDOG_CRITICAL" 4 "MIA" 3 "VERSION_MISMATCH" 2 "GPIO_CRITICAL" 1 "BOOT_TIMEOUT" 0 "UNKNOWN" ;
VAL_ 1481 APS_sw160_mismatchType 1 "GTW_APP_FW_REPO_GITHASH" 0 "APS_APP_FW_REPO_GITHASH" ;
VAL_ 1481 APS_sw188_otherTurbo 2 "UNKNOWN" 1 "B" 0 "A" ;
VAL_ 1481 APS_sw192_CANbus 4 "UNKNOWN" 3 "VEH" 2 "RAD0" 1 "CH" 0 "PARTY" ;
VAL_ 1481 APS_sw192_msgIo 2 "TX" 1 "RX" 0 "NO_MESSAGE" ;
VAL_ 1481 APS_sw192_queueFailure 2 "HW" 1 "SW" 0 "NO_FAILURE" ;
VAL_ 1481 APS_sw199_abortCodeDas 47 "CLOSURE_OPEN" 46 "COLLISION_RISK" 45 "CONTROLLER_HEALTH" 44 "PLANNER_HEALTH" 43 "SPEED_TOO_HIGH" 42 "SEATBELT_UNBUCKLED" 41 "GEAR_SHIFT_TIMEOUT" 40 "CONTROL_INTEGRATOR" 39 "GRADE_TOO_HIGH" 38 "UI_DISPLAY_NOT_OK" 37 "EXTENDED_COMPUTE_NOT_ACTIVE" 36 "REQUIRED_CAMERA_NOT_READY" 35 "FORWARD_CAMERAS_BLINDED" 34 "REPEATER_CAMERA_BLINDED" 33 "BACKUP_CAMERA_BLINDED" 32 "EXTERIOR_LIGHTS_OFF" 31 "DRIVER_NOT_DETECTED" 30 "UNAUTHORIZED_REQUEST" 29 "DRIVABLE_SPACE_STALE" 28 "TOO_MANY_GEAR_CHANGES" 27 "TRAILER_MODE" 26 "PARKER_HEARTBEAT_MISSING" 25 "HEARTBEAT_MISSING" 24 "APP_MIA" 23 "PAUSE_CYCLES" 22 "EPAS_INHIBITED" 21 "USER_KEYFOB" 20 "SC_MIA" 19 "SENSOR_FAILURE" 18 "PRECRUISE_TIMEOUT" 17 "UI_REQUEST" 16 "LOST_DI_CONTROL" 15 "PARK_GEAR" 14 "RESTART_TIMEOUT" 13 "PAUSE_USER_TIMEOUT" 12 "PAUSE_OBSTACLE_TIMEOUT" 11 "ESP_MIA" 10 "SCCM_MIA" 9 "MCU_MIA" 8 "DI_MIA" 7 "EPAS_MIA" 6 "PARK_MIA" 5 "PREGUIDANCE_TIMEOUT" 4 "INVALID_SPACE" 3 "MCU_REQUEST_MISMATCH" 2 "PARK_GUIDANCE_ENDED" 1 "LOST_ANGLE_CONTROL" 0 "NONE" ;
VAL_ 1481 APS_sw199_abortCodePARK 31 "SNA" 25 "PSC_MOVEMENT_AT_ACTIVATION" 24 "PSC_MAX_WAY_BEHIND_HINT" 23 "PSC_PARK_STC_FAILED" 22 "PSC_PARK_PONR_NOT_REACHED" 21 "PSC_VCTL_GENERAL_ABORT" 20 "PSC_HIGH_TORQUE" 19 "PSC_ASYNC_CTRL_SYSTEM" 18 "ERROR" 17 "SYSTEM_SERVICE" 16 "SYSTEM_FAULT" 15 "ECU_INTERNAL_FAULT" 14 "DAS_ABORT" 13 "EPAS_FAULT" 12 "VEHICLE_DYNAMICS_INTERVENTION" 11 "HANDS_ON_DETECTED" 10 "FULL_WARNING_ON_BOTH_SIDES" 9 "PARK_SPACE_TOO_SMALL" 8 "OBSTACLE_ON_PATH" 7 "MAX_YAW_ANGLE_REACHED" 6 "MAX_SWA_DEV_EXCEEDED" 5 "OFF_TRACK" 4 "UNCONTROLLED_TRAVEL_DIST_REACHED" 3 "NO_VALID_PATH" 2 "MAX_NUM_OF_MOVES" 1 "VELOCITY_TOO_HIGH" 0 "NONE" ;
VAL_ 1481 APS_sw203_controlType 15 "SNA" 14 "SUMMON" 10 "PAUSE" 9 "SEARCH" 8 "COMPLETE" 7 "ABORT" 6 "PARALLEL_PULL_OUT_TO_RIGHT" 5 "PARALLEL_PULL_OUT_TO_LEFT" 4 "PARK_RIGHT_CROSS" 3 "PARK_RIGHT_PARALLEL" 2 "PARK_LEFT_CROSS" 1 "PARK_LEFT_PARALLEL" 0 "NONE" ;
VAL_ 1481 APS_sw235_resetOrigin 2 "SOFTWARE" 1 "HARDWARE" 0 "NO_RESET" ;
VAL_ 1481 APS_sw237_faultSource 79 "PEER_TMUTHROT" 78 "PEER_SGK_NFAULT" 77 "PEER_AP_NFAULT" 76 "Veh_FAULT" 75 "CAUSE2_RECEIVED" 74 "CAUSE1_RECEIVED" 73 "NOC_ERRORLOG" 72 "SSS_WDG_RESET" 71 "SSS_SW_RESET" 70 "FaultManager_fm_parity" 69 "FaultManager_softfault" 68 "MemoryStack1_3_UR_int" 67 "MemoryStack0_3_UR_int" 66 "MemoryStack1_2_UR_int" 65 "MemoryStack0_2_UR_int" 64 "MemoryStack1_1_UR_int" 63 "MemoryStack0_1_UR_int" 62 "MemoryStack1_0_UR_int" 61 "MemoryStack0_0_UR_int" 60 "MemoryStack1_3_nw_UR_int" 59 "MemoryStack0_3_nw_UR_int" 58 "MemoryStack1_2_nw_UR_int" 57 "MemoryStack0_2_nw_UR_int" 56 "MemoryStack1_1_nw_UR_int" 55 "MemoryStack0_1_nw_UR_int" 54 "MemoryStack1_0_nw_UR_int" 53 "MemoryStack0_0_nw_UR_int" 52 "FAD_LSIO" 51 "NOC_LSIO_NS_BRDG_LSIO_D_T_mainTimeOut" 50 "NOC_LSIO_AHBBR_UFS_T_mainTimeOut" 49 "NOC_LSIO_AXI2APB_LSIO2_T_mainTimeOut" 48 "NOC_LSIO_AXI2APB_LSIO1_T_mainTimeOut" 47 "NOC_LSIO_AXI2APB_LSIO0_T_mainTimeOut" 46 "NOC_IMEM_NS_BRDG_IMEM_D_T_mainTimeOut" 45 "NOC_IMEM_INTMEM_IMEM_T_mainTimeOut" 44 "NOC_IMEM_AXI2APB_IMEM_T_mainTimeOut" 43 "IMEM_HPM" 42 "CORE_WDT4" 41 "CORE_WDT3" 40 "CORE_WDT2" 39 "CORE_WDT1" 38 "CORE_WDT0" 37 "VEH_FaultManager_FAULT" 36 "NOC_SOJU_AXI2APB_AON_T_mainTimeOut" 35 "TCU_AON_fmu_error_int" 34 "TMU_SGK_THERM_TRIP" 33 "IntMEM_SGK_ECC_INTR0" 32 "PUF_SGK_INT0" 31 "NOC_SGK_PD1_mainMissionInt" 30 "NOC_SGK_PD0_mainMissionInt" 29 "NOC_SGK_INT15" 28 "NOC_SGK_INT14" 27 "NOC_SGK_INT13" 26 "NOC_SGK_INT12" 25 "NOC_SGK_INT10" 24 "NOC_SGK_INT9" 23 "NOC_SGK_INT8" 22 "NOC_SGK_INT3" 21 "NOC_SGK_INT2" 20 "NOC_SGK_INT1" 19 "NOC_SGK_INT0" 18 "CR5_TOP_SGK_LOCKSTEP_FAIL" 17 "CR5_TOP_SGK_ALL_FATAL_BUS_FTLS" 16 "CR5_TOP_SGK_ALL_FATAL_EVTS" 15 "CR5_TOP_SGK_TCM_ECC_AXI_SLV_FATAL" 14 "CR5_TOP_SGK_DCACHE_TAG_ECC_FATAL" 13 "CR5_TOP_SGK_DCACHE_ECC_FATAL" 12 "CR5_TOP_SGK_TCM_ECC_LSU" 11 "CR5_TOP_SGK_TCM_ECC_PFU" 10 "SGK_SSS_FAULT" 9 "SGK_SSS_PKE_UNC" 8 "SGK_SSS_UNCORRECT" 7 "SGK_SSS_LOCKUP" 6 "SGK_ADT" 5 "SGK_GBE" 4 "SGK_HPM" 3 "SGK_DD_SLOW" 2 "SGK_DD_FAST" 1 "SGK_WDT1" 0 "SGK_WDT0" ;
VAL_ 1481 APS_sw243_errorStatus 11 "WATCHDOG_TIMEOUT_ERROR" 10 "HW_ASSERT_ERROR" 9 "FP_UNDERFLOW_ERROR" 8 "FP_OVERFLOW_ERROR" 7 "FP_DENORM_ERROR" 6 "FP_INVALID_ERROR" 5 "AXI_SLAVE_PROTOCOL_ERROR" 4 "DMA_ACE_PROTOCOL_ERROR" 3 "DMA_CRC_ERROR" 2 "SRAM_PARITY_ERROR" 1 "BAD_COMMAND" 0 "NONE" ;
VAL_ 1481 APS_sw249_ufsInitFailureReason 6 "TESTREADY_FAILED" 5 "FDEVICEINIT_FAILED" 4 "POWER_MODE_CHANGE_FAILED" 3 "NOP_CMD_FAILED" 2 "INIT_DESCRIPTOR_FAILED" 1 "LINK_STARTUP_CMD_FAILED" 0 "NO_ERROR" ;
VAL_ 1481 APS_sw289_turboTemperature -128 "SNA" ;
VAL_ 1481 APS_sw289_peer_turboTemperature -128 "SNA" ;
VAL_ 637 APS_eacAllow 3 "APS_EAC_SNA" 2 "APS_EAC_RESERVED" 1 "APS_EAC_ALLOW" 0 "APS_EAC_INHIBIT" ;
VAL_ 1865 APS_A_lowPowerRequest 5 "APS_LOW_POWER_COLD_RESET" 4 "APS_LOW_POWER_SOC_WARM_RESET" 3 "APS_LOW_POWER_AP_WARM_RESET" 2 "APS_LOW_POWER_OFF" 1 "APS_LOW_POWER_SUSPEND" 0 "APS_LOW_POWER_NONE" ;
VAL_ 1865 APS_A_lowPowerRequestor 10 "APS_LOW_POWER_REQ_COUNT" 9 "APS_LOW_POWER_REQ_SGK_PGOOD_IRQ" 8 "APS_LOW_POWER_REQ_SGK_CONSOLE" 7 "APS_LOW_POWER_REQ_SGK_SLEEP" 6 "APS_LOW_POWER_REQ_SGK_UDS" 5 "APS_LOW_POWER_REQ_SGK_BRIDGE" 4 "APS_LOW_POWER_REQ_SGK_FM" 3 "APS_LOW_POWER_REQ_SGK_POWER" 2 "APS_LOW_POWER_REQ_AP_MAILBOX" 1 "APS_LOW_POWER_REQ_AP_ATF" 0 "APS_LOW_POWER_REQ_NONE" ;
VAL_ 1865 APS_B_lowPowerRequest 5 "APS_LOW_POWER_COLD_RESET" 4 "APS_LOW_POWER_SOC_WARM_RESET" 3 "APS_LOW_POWER_AP_WARM_RESET" 2 "APS_LOW_POWER_OFF" 1 "APS_LOW_POWER_SUSPEND" 0 "APS_LOW_POWER_NONE" ;
VAL_ 1865 APS_B_lowPowerRequestor 10 "APS_LOW_POWER_REQ_COUNT" 9 "APS_LOW_POWER_REQ_SGK_PGOOD_IRQ" 8 "APS_LOW_POWER_REQ_SGK_CONSOLE" 7 "APS_LOW_POWER_REQ_SGK_SLEEP" 6 "APS_LOW_POWER_REQ_SGK_UDS" 5 "APS_LOW_POWER_REQ_SGK_BRIDGE" 4 "APS_LOW_POWER_REQ_SGK_FM" 3 "APS_LOW_POWER_REQ_SGK_POWER" 2 "APS_LOW_POWER_REQ_AP_MAILBOX" 1 "APS_LOW_POWER_REQ_AP_ATF" 0 "APS_LOW_POWER_REQ_NONE" ;
VAL_ 2044 APS_primaryTurbo 2 "TURBO_UNKNOWN" 1 "TURBO_B" 0 "TURBO_A" ;
VAL_ 2044 APS_A_arbState 7 "ARB_STATE_COUNT" 6 "ARB_STATE_UNKNOWN" 5 "ARB_STATE_MIA" 4 "ARB_STATE_FAULT" 3 "ARB_STATE_SECONDARY" 2 "ARB_STATE_PRIMARY" 1 "ARB_STATE_IDLE" 0 "ARB_STATE_INIT" ;
VAL_ 2044 APS_A_powerState 28 "POWER_STATE_AP_FORCE_POWER_OFF" 27 "POWER_STATE_AP_WAIT_FOR_SHUTDOWN_ABORT" 26 "POWER_STATE_AP_IN_LINUX" 25 "POWER_STATE_AP_IDLE" 24 "POWER_STATE_VEH_BOOTING" 23 "POWER_STATE_UNKNOWN" 22 "POWER_STATE_MIA" 21 "POWER_STATE_FAULT" 20 "POWER_STATE_SOC_OFF_ABORT" 19 "POWER_STATE_SOC_OFF" 18 "POWER_STATE_SOC_OFF_READY" 17 "POWER_STATE_AP_SUSPENDED" 16 "POWER_STATE_AP_OFF_ABORT_WAIT_FOR_ACK" 15 "POWER_STATE_AP_OFF_ABORT" 14 "POWER_STATE_AP_OFF_READY_WAIT_FOR_RESPONSE" 13 "POWER_STATE_AP_OFF_READY_WAIT_FOR_ACK" 12 "POWER_STATE_AP_OFF_READY" 11 "POWER_STATE_AP_OFF_PREPARE" 10 "POWER_STATE_AP_WAIT_FOR_SHUTDOWN" 9 "POWER_STATE_AP_ON" 8 "POWER_STATE_AP_IN_COREBOOT" 7 "POWER_STATE_AP_BOOTING" 6 "POWER_STATE_AP_ON_READY_WAIT_FOR_RESPONSE" 5 "POWER_STATE_AP_ON_READY_WAIT_FOR_ACK" 4 "POWER_STATE_AP_ON_READY" 3 "POWER_STATE_AP_ON_PREPARE_WAIT_FOR_RESPONSE" 2 "POWER_STATE_AP_ON_PREPARE_WAIT_FOR_ACK" 1 "POWER_STATE_AP_ON_PREPARE" 0 "POWER_STATE_IDLE" ;
VAL_ 2044 APS_A_sleepState 9 "SLEEP_STATE_COUNT" 8 "SLEEP_STATE_UNKNOWN" 7 "SLEEP_STATE_MIA" 6 "SLEEP_STATE_FAULT" 5 "SLEEP_STATE_ABORT" 4 "SLEEP_STATE_SLEEPING" 3 "SLEEP_STATE_GOING_TO_SLEEP" 2 "SLEEP_STATE_READY" 1 "SLEEP_STATE_WAIT_FOR_BUS_SILENCE" 0 "SLEEP_STATE_IDLE" ;
VAL_ 2044 APS_A_resetState 5 "RESET_STATE_COUNT" 4 "RESET_STATE_UNKNOWN" 3 "RESET_STATE_MIA" 2 "RESET_STATE_FAULT" 1 "RESET_STATE_RESETTING" 0 "RESET_STATE_NOT_RESETTING" ;
VAL_ 2044 APS_A_faultState 27 "FAULT_STATE_COUNT" 26 "FAULT_STATE_UNKNOWN" 25 "FAULT_STATE_MIA" 24 "FAULT_STATE_UNEXPECTED" 23 "FAULT_STATE_SCS" 22 "FAULT_STATE_SOFTWARE_FAULT" 21 "FAULT_STATE_TRIP1_FAULT" 20 "FAULT_STATE_TRIP0_FAULT" 19 "FAULT_STATE_WDT" 18 "FAULT_STATE_CPU_FAULT" 17 "FAULT_STATE_DROOP_TRIP" 16 "FAULT_STATE_DROOP_GPU" 15 "FAULT_STATE_DROOP_CPUCL2" 14 "FAULT_STATE_DROOP_CPUCL1" 13 "FAULT_STATE_DROOP_CPUCL0" 12 "FAULT_STATE_MIF_ECC_AP" 11 "FAULT_STATE_MIF7_DFI_ALERT" 10 "FAULT_STATE_MIF6_DFI_ALERT" 9 "FAULT_STATE_MIF5_DFI_ALERT" 8 "FAULT_STATE_MIF4_DFI_ALERT" 7 "FAULT_STATE_MIF3_DFI_ALERT" 6 "FAULT_STATE_MIF2_DFI_ALERT" 5 "FAULT_STATE_MIF1_DFI_ALERT" 4 "FAULT_STATE_MIF0_DFI_ALERT" 3 "FAULT_STATE_MIF_ECC_UNCORRECTED" 2 "FAULT_STATE_MIF_ECC_CORRECTED" 1 "FAULT_STATE_GIC" 0 "FAULT_STATE_NONE" ;
VAL_ 2044 APS_secondaryTurbo 2 "TURBO_UNKNOWN" 1 "TURBO_B" 0 "TURBO_A" ;
VAL_ 2044 APS_B_arbState 7 "ARB_STATE_COUNT" 6 "ARB_STATE_UNKNOWN" 5 "ARB_STATE_MIA" 4 "ARB_STATE_FAULT" 3 "ARB_STATE_SECONDARY" 2 "ARB_STATE_PRIMARY" 1 "ARB_STATE_IDLE" 0 "ARB_STATE_INIT" ;
VAL_ 2044 APS_B_powerState 28 "POWER_STATE_AP_FORCE_POWER_OFF" 27 "POWER_STATE_AP_WAIT_FOR_SHUTDOWN_ABORT" 26 "POWER_STATE_AP_IN_LINUX" 25 "POWER_STATE_AP_IDLE" 24 "POWER_STATE_VEH_BOOTING" 23 "POWER_STATE_UNKNOWN" 22 "POWER_STATE_MIA" 21 "POWER_STATE_FAULT" 20 "POWER_STATE_SOC_OFF_ABORT" 19 "POWER_STATE_SOC_OFF" 18 "POWER_STATE_SOC_OFF_READY" 17 "POWER_STATE_AP_SUSPENDED" 16 "POWER_STATE_AP_OFF_ABORT_WAIT_FOR_ACK" 15 "POWER_STATE_AP_OFF_ABORT" 14 "POWER_STATE_AP_OFF_READY_WAIT_FOR_RESPONSE" 13 "POWER_STATE_AP_OFF_READY_WAIT_FOR_ACK" 12 "POWER_STATE_AP_OFF_READY" 11 "POWER_STATE_AP_OFF_PREPARE" 10 "POWER_STATE_AP_WAIT_FOR_SHUTDOWN" 9 "POWER_STATE_AP_ON" 8 "POWER_STATE_AP_IN_COREBOOT" 7 "POWER_STATE_AP_BOOTING" 6 "POWER_STATE_AP_ON_READY_WAIT_FOR_RESPONSE" 5 "POWER_STATE_AP_ON_READY_WAIT_FOR_ACK" 4 "POWER_STATE_AP_ON_READY" 3 "POWER_STATE_AP_ON_PREPARE_WAIT_FOR_RESPONSE" 2 "POWER_STATE_AP_ON_PREPARE_WAIT_FOR_ACK" 1 "POWER_STATE_AP_ON_PREPARE" 0 "POWER_STATE_IDLE" ;
VAL_ 2044 APS_B_sleepState 9 "SLEEP_STATE_COUNT" 8 "SLEEP_STATE_UNKNOWN" 7 "SLEEP_STATE_MIA" 6 "SLEEP_STATE_FAULT" 5 "SLEEP_STATE_ABORT" 4 "SLEEP_STATE_SLEEPING" 3 "SLEEP_STATE_GOING_TO_SLEEP" 2 "SLEEP_STATE_READY" 1 "SLEEP_STATE_WAIT_FOR_BUS_SILENCE" 0 "SLEEP_STATE_IDLE" ;
VAL_ 2044 APS_B_resetState 5 "RESET_STATE_COUNT" 4 "RESET_STATE_UNKNOWN" 3 "RESET_STATE_MIA" 2 "RESET_STATE_FAULT" 1 "RESET_STATE_RESETTING" 0 "RESET_STATE_NOT_RESETTING" ;
VAL_ 2044 APS_B_faultState 27 "FAULT_STATE_COUNT" 26 "FAULT_STATE_UNKNOWN" 25 "FAULT_STATE_MIA" 24 "FAULT_STATE_UNEXPECTED" 23 "FAULT_STATE_SCS" 22 "FAULT_STATE_SOFTWARE_FAULT" 21 "FAULT_STATE_TRIP1_FAULT" 20 "FAULT_STATE_TRIP0_FAULT" 19 "FAULT_STATE_WDT" 18 "FAULT_STATE_CPU_FAULT" 17 "FAULT_STATE_DROOP_TRIP" 16 "FAULT_STATE_DROOP_GPU" 15 "FAULT_STATE_DROOP_CPUCL2" 14 "FAULT_STATE_DROOP_CPUCL1" 13 "FAULT_STATE_DROOP_CPUCL0" 12 "FAULT_STATE_MIF_ECC_AP" 11 "FAULT_STATE_MIF7_DFI_ALERT" 10 "FAULT_STATE_MIF6_DFI_ALERT" 9 "FAULT_STATE_MIF5_DFI_ALERT" 8 "FAULT_STATE_MIF4_DFI_ALERT" 7 "FAULT_STATE_MIF3_DFI_ALERT" 6 "FAULT_STATE_MIF2_DFI_ALERT" 5 "FAULT_STATE_MIF1_DFI_ALERT" 4 "FAULT_STATE_MIF0_DFI_ALERT" 3 "FAULT_STATE_MIF_ECC_UNCORRECTED" 2 "FAULT_STATE_MIF_ECC_CORRECTED" 1 "FAULT_STATE_GIC" 0 "FAULT_STATE_NONE" ;
VAL_ 2044 APS_autosteerMonitorState 4 "COUNT" 3 "TOI_TRIGGER" 2 "WAIT_FOR_MIA" 1 "ACTIVE" 0 "IDLE" ;
VAL_ 970 APS_appStatusMonitorState 7 "STATUS_MONITOR_NUM_STATES" 6 "STATUS_MONITOR_STATE_RECOVERY" 5 "STATUS_MONITOR_STATE_SHUTTING_DOWN" 4 "STATUS_MONITOR_STATE_CRITICAL" 3 "STATUS_MONITOR_STATE_NOMINAL" 2 "STATUS_MONITOR_STATE_INIT" 1 "STATUS_MONITOR_STATE_PWR_OFF" 0 "STATUS_MONITOR_STATE_UNKNOWN" ;
VAL_ 970 APS_vehBehaviorState 8 "VEH_BEHAVIOR_NUM_STATES" 7 "VEH_BEHAVIOR_STATE_SYSTEM_FAULT" 6 "VEH_BEHAVIOR_STATE_APS_OVERRIDE" 5 "VEH_BEHAVIOR_STATE_APS_FAIL_SAFE" 4 "VEH_BEHAVIOR_STATE_APS_BRIDGE_APB" 3 "VEH_BEHAVIOR_STATE_APS_BRIDGE_APP" 2 "VEH_BEHAVIOR_STATE_APS_CONTROL" 1 "VEH_BEHAVIOR_STATE_APS_AVAILABLE" 0 "VEH_BEHAVIOR_STATE_UNKNOWN" ;
VAL_ 970 APS_canMaster 3 "CAN_MASTER_SNA" 2 "CAN_MASTER_APB" 1 "CAN_MASTER_APP" 0 "CAN_MASTER_APS" ;
VAL_ 970 APS_appGpioState 3 "AP_GPIO_STATE_HEALTHY" 2 "AP_GPIO_STATE_CRITICAL" 1 "AP_GPIO_STATE_DISABLED" 0 "AP_GPIO_STATE_PWR_DOWN_REBOOT" ;
VAL_ 970 APS_eacInternalState 7 "APS_EAC_NUM_STATES" 6 "APS_EAC_STATE_LSS" 5 "APS_EAC_STATE_OVERRIDE" 4 "APS_EAC_STATE_INHIBIT" 3 "APS_EAC_STATE_AUTOPARK" 2 "APS_EAC_STATE_CONTINUOUS" 1 "APS_EAC_STATE_MOMENTARY" 0 "APS_EAC_STATE_INIT" ;
VAL_ 970 APS_apbStatusMonitorState 7 "STATUS_MONITOR_NUM_STATES" 6 "STATUS_MONITOR_STATE_RECOVERY" 5 "STATUS_MONITOR_STATE_SHUTTING_DOWN" 4 "STATUS_MONITOR_STATE_CRITICAL" 3 "STATUS_MONITOR_STATE_NOMINAL" 2 "STATUS_MONITOR_STATE_INIT" 1 "STATUS_MONITOR_STATE_PWR_OFF" 0 "STATUS_MONITOR_STATE_UNKNOWN" ;
VAL_ 970 APS_apbGpioState 3 "AP_GPIO_STATE_HEALTHY" 2 "AP_GPIO_STATE_CRITICAL" 1 "AP_GPIO_STATE_DISABLED" 0 "AP_GPIO_STATE_PWR_DOWN_REBOOT" ;
VAL_ 970 APS_locLimitReason 7 "LOC_LIMITS_EXTENDED" 6 "LOC_MONITOR_UNAVAILABLE" 5 "NO_RADAR_TARGET" 4 "RADAR_NOT_HEALTHY" 3 "PRIMARY_AP_NOT_HEALTHY" 2 "ACC_AND_AEB_UNAVAILABLE" 1 "NOT_IN_DRIVE" 0 "NOMINAL_DEFAULT" ;
VAL_ 970 APS_appPowerStateRequest 3 "AP_POWER_STATE_SLEEP" 2 "AP_POWER_STATE_SUSPEND" 1 "AP_POWER_STATE_SENTRY" 0 "AP_POWER_STATE_NOMINAL" ;
VAL_ 970 APS_appPowerStateReason 12 "UI_SUMMON_STANDBY_MODE_ENABLED" 11 "SLEEP_REQUEST_RECVD" 10 "AP_POWER_REQUEST_OVERHEATED" 9 "LOADSHED_POWER_REQUEST_PENDING" 8 "VC_POWER_REQUEST" 7 "AP_POWER_REQUEST_OVERRIDE" 6 "AP_POWER_REQUEST_OVERHEATING" 5 "AP_POWER_REQUEST_HYSTERESIS" 4 "GTW_GOTO_FULL_POWER" 3 "AP_NOT_IN_PARK" 2 "AP_NM_REASON_SET" 1 "AP_WDOG_UNHEALTHY" 0 "UI_POWER_STATE_REQUEST" ;
VAL_ 970 APS_apbPowerStateRequest 3 "AP_POWER_STATE_SLEEP" 2 "AP_POWER_STATE_SUSPEND" 1 "AP_POWER_STATE_SENTRY" 0 "AP_POWER_STATE_NOMINAL" ;
VAL_ 970 APS_apbPowerStateReason 12 "UI_SUMMON_STANDBY_MODE_ENABLED" 11 "SLEEP_REQUEST_RECVD" 10 "AP_POWER_REQUEST_OVERHEATED" 9 "LOADSHED_POWER_REQUEST_PENDING" 8 "VC_POWER_REQUEST" 7 "AP_POWER_REQUEST_OVERRIDE" 6 "AP_POWER_REQUEST_OVERHEATING" 5 "AP_POWER_REQUEST_HYSTERESIS" 4 "GTW_GOTO_FULL_POWER" 3 "AP_NOT_IN_PARK" 2 "AP_NM_REASON_SET" 1 "AP_WDOG_UNHEALTHY" 0 "UI_POWER_STATE_REQUEST" ;
VAL_ 970 APS_heaterStateDebug 7 "APS_HEATER_SNA" 4 "APS_HEATER_FAULT_SHORT" 3 "APS_HEATER_FAULT_OPEN" 2 "APS_HEATER_ON_NOT_HEATING" 1 "APS_HEATER_ON_HEATING" 0 "APS_HEATER_OFF" ;
VAL_ 970 APS_gpsAntennaState 2 "GPS_ANTENNA_CONNECTED" 1 "GPS_ANTENNA_UNKNOWN" 0 "GPS_ANTENNA_DISCONNECTED" ;
VAL_ 970 APS_arbState 7 "ARB_STATE_N_COUNT" 6 "ARB_STATE_N_UNKNOWN" 5 "ARB_STATE_N_MIA" 4 "ARB_STATE_N_FAULT" 3 "ARB_STATE_N_SECONDARY" 2 "ARB_STATE_N_PRIMARY" 1 "ARB_STATE_N_IDLE" 0 "ARB_STATE_N_INIT" ;
VAL_ 970 APS_socPowerOperatingMode 2 "APS_DUAL_SOC" 1 "APS_SINGLE_SOC" 0 "APS_UNKNOWN" ;
VAL_ 970 APS_otherArbState 7 "ARB_STATE_N_COUNT" 6 "ARB_STATE_N_UNKNOWN" 5 "ARB_STATE_N_MIA" 4 "ARB_STATE_N_FAULT" 3 "ARB_STATE_N_SECONDARY" 2 "ARB_STATE_N_PRIMARY" 1 "ARB_STATE_N_IDLE" 0 "ARB_STATE_N_INIT" ;
VAL_ 1510 APS_A_cam12v0Voltage 4095 "SNA" ;
VAL_ 1510 APS_B_cam12v0Voltage 4095 "SNA" ;
VAL_ 1510 APS_A_turboMaxTemperature -128 "SNA" ;
VAL_ 1510 APS_A_turboProbeType 63 "SNA" ;
VAL_ 1510 APS_B_turboMaxTemperature -128 "SNA" ;
VAL_ 1510 APS_B_turboProbeType 63 "SNA" ;
